VERSION ""

NS_ :

BS_:

BU_: ATCM_DMSM HCM_HS2 PAM_HS2 GSM TRCM GWM _delete SASM SCCM ATCM SUMA_RLM ATCM_FFSM PCU VDM_HS2 TBM OCS GENERIC TSTR RCM

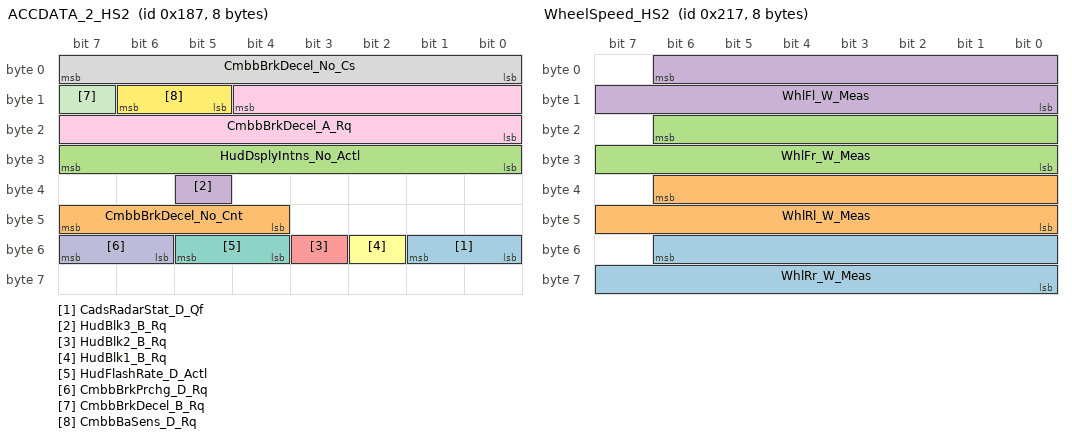
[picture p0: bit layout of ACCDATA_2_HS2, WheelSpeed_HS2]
BO_ 391 ACCDATA_2_HS2: 8 GWM
 SG_ CadsRadarStat_D_Qf : 49|2@0+ (1,0) [0|3] "SED"  GWM,GENERIC
 SG_ CmbbBrkDecel_No_Cnt : 47|4@0+ (1,0) [0|15] "Unitless"  GWM
 SG_ HudDsplyIntns_No_Actl : 31|8@0+ (0.5,0) [0|100] "%"  GWM
 SG_ HudBlk3_B_Rq : 37|1@0+ (1,0) [0|1] "SED"  GWM
 SG_ HudBlk2_B_Rq : 51|1@0+ (1,0) [0|1] "SED"  GWM
 SG_ HudBlk1_B_Rq : 50|1@0+ (1,0) [0|1] "SED"  GWM
 SG_ HudFlashRate_D_Actl : 53|2@0+ (1,0) [0|3] "SED"  GWM
 SG_ CmbbBrkDecel_No_Cs : 7|8@0+ (1,0) [0|255] "Unitless"  GWM
 SG_ CmbbBrkDecel_A_Rq : 12|13@0+ (0.0039,-20) [-20|11.9449] "m/s^2"  GWM,RCM
 SG_ CmbbBrkPrchg_D_Rq : 55|2@0+ (1,0) [0|3] "SED"  GWM,RCM
 SG_ CmbbBrkDecel_B_Rq : 15|1@0+ (1,0) [0|1] "SED"  GWM,RCM
 SG_ CmbbBaSens_D_Rq : 14|2@0+ (1,0) [0|3] "SED"  GWM,RCM

BO_ 535 WheelSpeed_HS2: 8 GWM
 SG_ WhlRr_W_Meas : 54|15@0+ (0.01,0) [0|327.65] "rad/s"  VDM_HS2,PAM_HS2,RCM
 SG_ WhlRl_W_Meas : 38|15@0+ (0.01,0) [0|327.65] "rad/s"  VDM_HS2,PAM_HS2,RCM
 SG_ WhlFr_W_Meas : 22|15@0+ (0.01,0) [0|327.65] "rad/s"  VDM_HS2,PAM_HS2,RCM
 SG_ WhlFl_W_Meas : 6|15@0+ (0.01,0) [0|327.65] "rad/s"  VDM_HS2,PAM_HS2,RCM

BO_ 531 DesiredTorqBrk_HS2: 8 GWM
 SG_ VehStop_D_Stat : 28|2@0+ (1,0) [0|3] "SED" Vector__XXX
 SG_ TracCtlPtActv_B_Actl : 31|1@0+ (1,0) [0|1] "SED"  PAM_HS2,VDM_HS2,RCM
 SG_ LscmbbMntr_B_Err : 17|1@0+ (1,0) [0|1] "SED" Vector__XXX
 SG_ LscmbbBrkDis_B_Actl : 19|1@0+ (1,0) [0|1] "SED" Vector__XXX
 SG_ LscmbbDeny_B_ActlBrk : 18|1@0+ (1,0) [0|1] "SED" Vector__XXX
 SG_ PrkBrkYwLamp_D_Rq : 38|2@0+ (1,0) [0|3] "SED" Vector__XXX
 SG_ PrkBrkRedLamp_D_Rq : 30|2@0+ (1,0) [0|3] "SED" Vector__XXX
 SG_ VehicleStationary : 39|1@0+ (1,0) [0|1] "SED" Vector__XXX
 SG_ LscmbbBrkDecel_B_Actl : 20|1@0+ (1,0) [0|1] "SED" Vector__XXX
 SG_ AbsActv_B_Actl : 45|1@0+ (1,0) [0|1] "SED"  PAM_HS2,SASM,TBM,RCM,TRCM,VDM_HS2
 SG_ StabCtlBrkActv_B_Actl : 23|1@0+ (1,0) [0|1] "SED"  PAM_HS2,SASM,VDM_HS2,RCM
 SG_ CmbbBrkPrchg_B_Actl : 59|1@0+ (1,0) [0|1] "SED"  TBM
 SG_ CmbbBrkDecel_B_Actl : 58|1@0+ (1,0) [0|1] "SED"  TBM
 SG_ CmbbBaSensInc_B_Actl : 57|1@0+ (1,0) [0|1] "SED" Vector__XXX
 SG_ AccBrkWarm_B_Actl : 63|1@0+ (1,0) [0|1] "SED" Vector__XXX
 SG_ AccBrkTotTqMn_B_Actl : 62|1@0+ (1,0) [0|1] "SED"  TBM
 SG_ AccBrkPrchgActv_B_Actl : 61|1@0+ (1,0) [0|1] "SED" Vector__XXX
 SG_ AccBrkDis_B_Actl : 44|1@0+ (1,0) [0|1] "SED" Vector__XXX
 SG_ AccBrkDeny_B_Actl : 42|1@0+ (1,0) [0|1] "SED" Vector__XXX
 SG_ AccBrkActv_B_Actl : 43|1@0+ (1,0) [0|1] "SED" Vector__XXX
 SG_ PrplDrgCtlActv_B_Actl : 46|1@0+ (1,0) [0|1] "SED" Vector__XXX
 SG_ PrplWhlTot_Tq_RqMx : 7|16@0+ (4,-131072) [-131072|131068] "Nm" Vector__XXX
 SG_ LscmbbBaSensInc_B_Actl : 21|1@0+ (1,0) [0|1] "SED" Vector__XXX
 SG_ CmbbBrkDis_B_Actl : 56|1@0+ (1,0) [0|1] "SED" Vector__XXX
 SG_ CmbbDeny_B_ActlBrk : 60|1@0+ (1,0) [0|1] "SED" Vector__XXX
 SG_ CcDis_B_Cmd : 47|1@0+ (1,0) [0|1] "SED" Vector__XXX
 SG_ VehLongOvrGnd_A_Est : 41|10@0+ (0.035,-17.9) [-17.9|17.835] "m/s^2"  VDM_HS2,TBM
 SG_ LscmbBrkPrchg_B_Actl : 16|1@0+ (1,0) [0|1] "SED" Vector__XXX
 SG_ AccStopActv_B_ActlBrk : 22|1@0+ (1,0) [0|1] "SED" Vector__XXX
 SG_ AccDis_B_ActlEpb : 32|1@0+ (1,0) [0|1] "SED" Vector__XXX
 SG_ PrkBrkMsgTxt_D_Rq : 36|4@0+ (1,0) [0|15] "SED" Vector__XXX
 SG_ PrkBrkStatus : 26|3@0+ (1,0) [0|7] "SED"  RCM,PAM_HS2,GSM

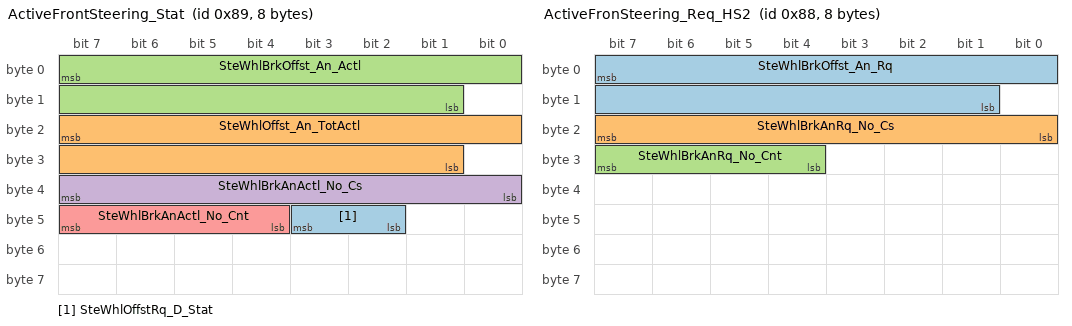
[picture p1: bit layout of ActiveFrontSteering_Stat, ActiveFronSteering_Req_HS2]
BO_ 137 ActiveFrontSteering_Stat: 8 SASM
 SG_ SteWhlOffstRq_D_Stat : 43|2@0+ (1,0) [0|3] "SED"  GWM
 SG_ SteWhlOffst_An_TotActl : 23|15@0+ (0.1,-1600) [-1600|1676.5] "degrees"  GWM
 SG_ SteWhlBrkOffst_An_Actl : 7|15@0+ (0.1,-1600) [-1600|1676.5] "degrees"  GWM
 SG_ SteWhlBrkAnActl_No_Cs : 39|8@0+ (1,0) [0|255] "Unitless"  GWM
 SG_ SteWhlBrkAnActl_No_Cnt : 47|4@0+ (1,0) [0|15] "Unitless"  GWM

BO_ 136 ActiveFronSteering_Req_HS2: 8 GWM
 SG_ SteWhlBrkOffst_An_Rq : 7|15@0+ (0.1,-1600) [-1600|1676.5] "degrees"  SASM
 SG_ SteWhlBrkAnRq_No_Cs : 23|8@0+ (1,0) [0|255] "Unitless"  SASM
 SG_ SteWhlBrkAnRq_No_Cnt : 31|4@0+ (1,0) [0|15] "Unitless"  SASM

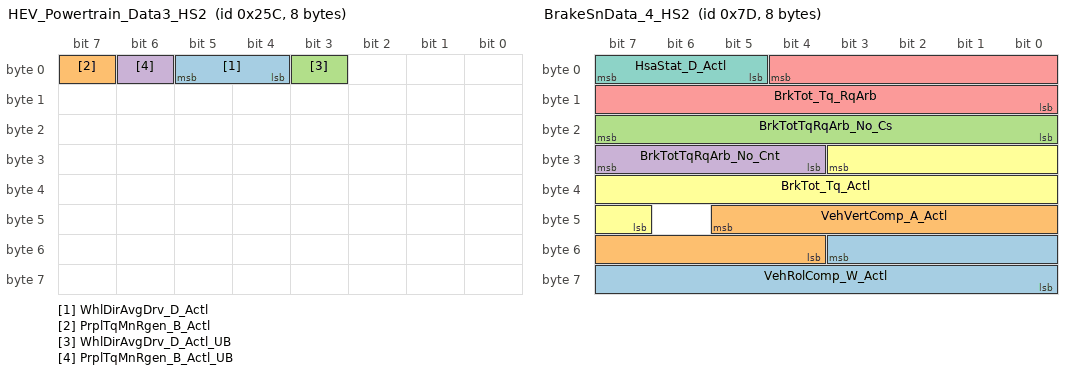
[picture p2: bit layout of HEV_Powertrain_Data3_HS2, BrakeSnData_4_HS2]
BO_ 604 HEV_Powertrain_Data3_HS2: 8 GWM
 SG_ WhlDirAvgDrv_D_Actl : 5|2@0+ (1,0) [0|3] "SED"  PAM_HS2
 SG_ PrplTqMnRgen_B_Actl : 7|1@0+ (1,0) [0|1] "SED" Vector__XXX
 SG_ WhlDirAvgDrv_D_Actl_UB : 3|1@0+ (1,0) [0|1] "SED" Vector__XXX
 SG_ PrplTqMnRgen_B_Actl_UB : 6|1@0+ (1,0) [0|1] "SED" Vector__XXX

BO_ 2015 TesterFunctionalReq_H2: 8 TSTR
 SG_ TesterFunctionalReq : 7|64@0+ (1,0) [0|1.84467E+019] "unitless"  HCM_HS2,PAM_HS2,SUMA_RLM,ATCM_FFSM,SASM,ATCM_DMSM,RCM,GSM,TRCM,PCU,OCS,ATCM,SCCM,TBM,VDM_HS2,GWM

BO_ 125 BrakeSnData_4_HS2: 8 GWM
 SG_ VehRolComp_W_Actl : 51|12@0+ (0.03663,-75) [-75|74.92659] "degrees/sec"  VDM_HS2
 SG_ VehVertComp_A_Actl : 45|10@0+ (0.035,-17.9) [-17.9|17.835] "m/s^2"  VDM_HS2
 SG_ BrkTotTqRqArb_No_Cs : 23|8@0+ (1,0) [0|255] "Unitless"  TBM
 SG_ BrkTotTqRqArb_No_Cnt : 31|4@0+ (1,0) [0|15] "Unitless"  TBM
 SG_ BrkTot_Tq_RqArb : 4|13@0+ (4,0) [0|32756] "Nm"  HCM_HS2,SUMA_RLM,TBM,VDM_HS2
 SG_ BrkTot_Tq_Actl : 27|13@0+ (4,0) [0|32756] "Nm"  RCM
 SG_ HsaStat_D_Actl : 7|3@0+ (1,0) [0|7] "SED"  GENERIC

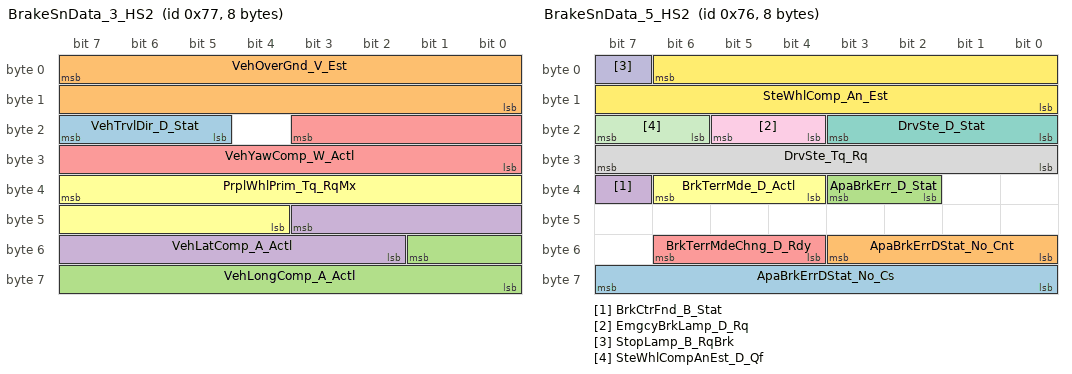
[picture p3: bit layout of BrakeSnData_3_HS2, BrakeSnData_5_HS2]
BO_ 119 BrakeSnData_3_HS2: 8 GWM
 SG_ VehTrvlDir_D_Stat : 23|3@0+ (1,0) [0|7] "SED"  SASM
 SG_ VehOverGnd_V_Est : 7|16@0+ (0.01,0) [0|655.33] "kph"  VDM_HS2,SASM
 SG_ VehLongComp_A_Actl : 49|10@0+ (0.035,-17.9) [-17.9|17.835] "m/s^2"  HCM_HS2,SUMA_RLM,VDM_HS2
 SG_ VehLatComp_A_Actl : 43|10@0+ (0.035,-17.9) [-17.9|17.835] "m/s^2"  HCM_HS2,SUMA_RLM,VDM_HS2
 SG_ VehYawComp_W_Actl : 19|12@0+ (0.03663,-75) [-75|74.92659] "deg/s"  PAM_HS2,VDM_HS2,SASM
 SG_ PrplWhlPrim_Tq_RqMx : 39|12@0+ (8,0) [0|32760] "Nm"  GENERIC

BO_ 118 BrakeSnData_5_HS2: 8 GWM
 SG_ ApaBrkErrDStat_No_Cs : 63|8@0+ (1,0) [0|255] "Unitless"  GENERIC
 SG_ ApaBrkErrDStat_No_Cnt : 51|4@0+ (1,0) [0|15] "Unitless"  GENERIC
 SG_ ApaBrkErr_D_Stat : 35|2@0+ (1,0) [0|3] "SED"  GENERIC
 SG_ BrkCtrFnd_B_Stat : 39|1@0+ (1,0) [0|1] "SED"  SASM
 SG_ BrkTerrMdeChng_D_Rdy : 54|3@0+ (1,0) [0|7] "SED"  ATCM,GENERIC
 SG_ BrkTerrMde_D_Actl : 38|3@0+ (1,0) [0|7] "SED"  ATCM,GENERIC
 SG_ DrvSte_D_Stat : 19|4@0+ (1,0) [0|15] "SED"  GENERIC
 SG_ DrvSte_Tq_Rq : 31|8@0+ (0.0625,-8) [-8|7.8125] "Nm"  GENERIC
 SG_ EmgcyBrkLamp_D_Rq : 21|2@0+ (1,0) [0|3] "SED"  GENERIC
 SG_ StopLamp_B_RqBrk : 7|1@0+ (1,0) [0|1] "SED"  GENERIC
 SG_ SteWhlCompAnEst_D_Qf : 23|2@0+ (1,0) [0|3] "SED"  PAM_HS2,SCCM,RCM
 SG_ SteWhlComp_An_Est : 6|15@0+ (0.1,-1600) [-1600|1676.7] "deg"  PAM_HS2,SCCM,RCM

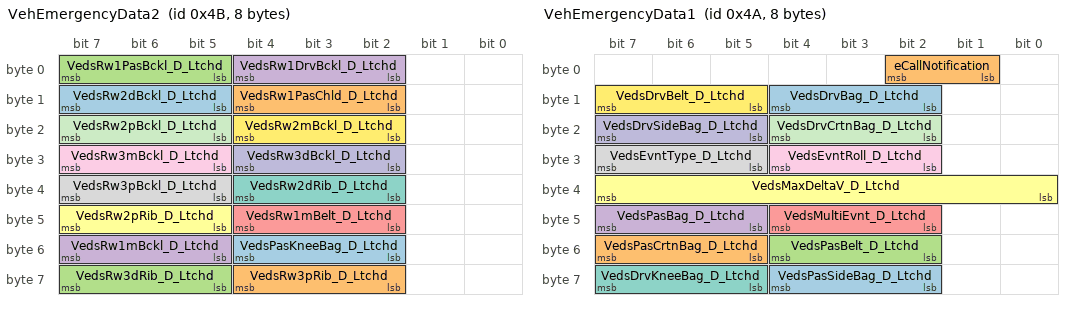
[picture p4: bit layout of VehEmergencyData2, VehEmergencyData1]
BO_ 75 VehEmergencyData2: 8 RCM
 SG_ VedsPasKneeBag_D_Ltchd : 52|3@0+ (1,0) [0|7] "SED"  GWM
 SG_ VedsRw3pRib_D_Ltchd : 60|3@0+ (1,0) [0|7] "SED"  GWM
 SG_ VedsRw3dRib_D_Ltchd : 63|3@0+ (1,0) [0|7] "SED"  GWM
 SG_ VedsRw1mBckl_D_Ltchd : 55|3@0+ (1,0) [0|7] "SED"  GWM
 SG_ VedsRw1mBelt_D_Ltchd : 44|3@0+ (1,0) [0|7] "SED"  GWM
 SG_ VedsRw2pRib_D_Ltchd : 47|3@0+ (1,0) [0|7] "SED"  GWM
 SG_ VedsRw2dRib_D_Ltchd : 36|3@0+ (1,0) [0|7] "SED"  GWM
 SG_ VedsRw3pBckl_D_Ltchd : 39|3@0+ (1,0) [0|7] "SED"  GWM
 SG_ VedsRw3mBckl_D_Ltchd : 31|3@0+ (1,0) [0|7] "SED"  GWM
 SG_ VedsRw3dBckl_D_Ltchd : 28|3@0+ (1,0) [0|7] "SED"  GWM
 SG_ VedsRw2pBckl_D_Ltchd : 23|3@0+ (1,0) [0|7] "SED"  GWM
 SG_ VedsRw2mBckl_D_Ltchd : 20|3@0+ (1,0) [0|7] "SED"  GWM
 SG_ VedsRw2dBckl_D_Ltchd : 15|3@0+ (1,0) [0|7] "SED"  GWM
 SG_ VedsRw1PasChld_D_Ltchd : 12|3@0+ (1,0) [0|7] "SED"  GWM
 SG_ VedsRw1PasBckl_D_Ltchd : 7|3@0+ (1,0) [0|7] "SED"  GWM
 SG_ VedsRw1DrvBckl_D_Ltchd : 4|3@0+ (1,0) [0|7] "SED"  GWM

BO_ 74 VehEmergencyData1: 8 RCM
 SG_ VedsPasSideBag_D_Ltchd : 60|3@0+ (1,0) [0|7] "SED"  GWM
 SG_ VedsPasCrtnBag_D_Ltchd : 55|3@0+ (1,0) [0|7] "SED"  GWM
 SG_ VedsPasBelt_D_Ltchd : 52|3@0+ (1,0) [0|7] "SED"  GWM
 SG_ VedsPasBag_D_Ltchd : 47|3@0+ (1,0) [0|7] "SED"  GWM
 SG_ VedsMultiEvnt_D_Ltchd : 44|3@0+ (1,0) [0|7] "SED"  GWM
 SG_ VedsMaxDeltaV_D_Ltchd : 39|8@0+ (1,0) [0|255] "kph"  GWM
 SG_ VedsDrvKneeBag_D_Ltchd : 63|3@0+ (1,0) [0|7] "SED"  GWM
 SG_ VedsEvntType_D_Ltchd : 31|3@0+ (1,0) [0|7] "SED"  GWM
 SG_ VedsEvntRoll_D_Ltchd : 28|3@0+ (1,0) [0|7] "SED"  GWM
 SG_ VedsDrvSideBag_D_Ltchd : 23|3@0+ (1,0) [0|7] "SED"  GWM
 SG_ VedsDrvCrtnBag_D_Ltchd : 20|3@0+ (1,0) [0|7] "SED"  GWM
 SG_ VedsDrvBelt_D_Ltchd : 15|3@0+ (1,0) [0|7] "SED"  GWM
 SG_ VedsDrvBag_D_Ltchd : 12|3@0+ (1,0) [0|7] "SED"  GWM
 SG_ eCallNotification : 2|2@0+ (1,0) [0|3] "SED"  GWM

BO_ 947 BodyInfo_3_HS2: 8 GWM
 SG_ ValetMode_D_Mem : 16|1@0+ (1,0) [0|1] "SED"  GENERIC
 SG_ DimmingLvlEvnt_No_Actl : 18|2@0+ (1,0) [0|3] "unitless"  GENERIC
 SG_ DrStatDrvErrCnt_B_Stat : 19|1@0+ (1,0) [0|1] "SED"  GENERIC
 SG_ Backlit_LED_Status : 23|4@0+ (1,0) [0|15] "SED"  ATCM_DMSM,ATCM_FFSM,ATCM,TBM,GSM
 SG_ TurnLghtRight_D_Rq : 63|2@0+ (1,0) [0|3] "SED"  HCM_HS2,SCCM
 SG_ TurnLghtRightOn_B_Stat : 35|1@0+ (1,0) [0|1] "SED"  GENERIC
 SG_ TurnLghtLeftOn_B_Stat : 54|1@0+ (1,0) [0|1] "SED"  GENERIC
 SG_ FogLghtRearOn_B_Stat : 1|1@0+ (1,0) [0|1] "SED"  HCM_HS2,GENERIC
 SG_ FogLghtFrontOn_B_Stat : 56|1@0+ (1,0) [0|1] "SED"  HCM_HS2
 SG_ TurnLghtLeft_D_Rq : 9|2@0+ (1,0) [0|3] "SED"  HCM_HS2,SCCM
 SG_ IgnKeyType_D_Actl : 39|4@0+ (1,0) [0|15] "SED"  PAM_HS2
 SG_ Parklamp_Status : 3|2@0+ (1,0) [0|3] "SED"  HCM_HS2,PAM_HS2,GSM,ATCM_FFSM,ATCM_DMSM
 SG_ Litval : 47|8@0+ (1,0) [0|253] "SED"  SCCM,HCM_HS2,ATCM,ATCM_DMSM,ATCM_FFSM,SASM,TBM,GSM
 SG_ Key_In_Ignition_Stat : 11|1@0+ (1,0) [0|1] "SED"  GSM,TRCM
 SG_ Ignition_Status : 7|4@0+ (1,0) [0|15] "SED"  HCM_HS2,PAM_HS2,SASM,SUMA_RLM,ATCM_DMSM,ATCM,OCS,TBM,VDM_HS2,TRCM,SCCM,GSM,RCM,ATCM_FFSM
 SG_ Dimming_Lvl : 31|8@0+ (1,0) [0|253] "SED"  SCCM,PAM_HS2,SASM,RCM,ATCM,ATCM_DMSM,ATCM_FFSM,GSM,TBM
 SG_ Day_Night_Status : 15|2@0+ (1,0) [0|3] "SED"  PAM_HS2,GSM,ATCM_DMSM,TBM,ATCM_FFSM,RCM
 SG_ Remote_Start_Status : 13|2@0+ (1,0) [0|3] "SED"  TRCM,RCM,GENERIC
 SG_ DrStatTgate_B_Actl : 0|1@0+ (1,0) [0|1] "SED"  PAM_HS2,SUMA_RLM,VDM_HS2,OCS
 SG_ DrStatRr_B_Actl : 49|1@0+ (1,0) [0|1] "SED"  PAM_HS2,SUMA_RLM,VDM_HS2,OCS
 SG_ DrStatRl_B_Actl : 48|1@0+ (1,0) [0|1] "SED"  PAM_HS2,SUMA_RLM,VDM_HS2,OCS
 SG_ DrStatPsngr_B_Actl : 60|1@0+ (1,0) [0|1] "SED"  PAM_HS2,SUMA_RLM,ATCM_FFSM,ATCM_DMSM,VDM_HS2,OCS
 SG_ DrStatInnrTgate_B_Actl : 58|1@0+ (1,0) [0|1] "SED"  PAM_HS2,SUMA_RLM,VDM_HS2,SCCM,OCS
 SG_ DrStatHood_B_Actl : 59|1@0+ (1,0) [0|1] "SED"  OCS
 SG_ DrStatDrv_B_Actl : 61|1@0+ (1,0) [0|1] "SED"  PAM_HS2,SUMA_RLM,ATCM_FFSM,ATCM_DMSM,SASM,VDM_HS2,GSM,OCS
 SG_ PrkBrkActv_B_Actl : 55|1@0+ (1,0) [0|1] "SED"  PAM_HS2
 SG_ LifeCycMde_D_Actl : 53|4@0+ (1,0) [0|15] "SED"  HCM_HS2,PAM_HS2,SUMA_RLM,SASM,SCCM,GSM,TRCM,VDM_HS2
 SG_ CrashEvnt_D_Stat : 34|2@0+ (1,0) [0|3] "SED"  GENERIC
 SG_ FuelPmpInhbt_B_Stat : 32|1@0+ (1,0) [0|1] "SED"  GENERIC
 SG_ BodySrvcRqd_B_Rq : 10|1@0+ (1,0) [0|1] "SED"  GENERIC
 SG_ Delay_Accy : 57|1@0+ (1,0) [0|1] "SED"  SASM,GENERIC

BO_ 131 Steering_Data: 8 SCCM
 SG_ HeadLghtHiCtrl_D_RqAhb : 43|3@0+ (1,0) [0|7] "SED"  HCM_HS2,GWM
 SG_ AhbStat_B_Dsply : 33|1@0+ (1,0) [0|1] "SED"  GWM
 SG_ WiprFrontSwtch_D_Stat : 47|4@0+ (1,0) [0|15] "SED"  GWM
 SG_ HeadLghtHiOn_B_StatAhb : 34|1@0+ (1,0) [0|1] "SED"  GENERIC,GWM
 SG_ HeadLghtHiFlash_D_Actl : 36|2@0+ (1,0) [0|3] "SED"  HCM_HS2,GWM
 SG_ TjaButtnOnOffPress : 40|1@0+ (1,0) [0|1] "SED"  GWM
 SG_ AccButtnGapTogglePress : 32|1@0+ (1,0) [0|1] "SED"  GWM
 SG_ HeadLghtHiFlash_D_Stat : 7|2@0+ (1,0) [0|3] "SED"  GENERIC,GWM
 SG_ WiprFront_D_Stat : 3|4@0+ (1,0) [0|15] "SED"  HCM_HS2,GWM
 SG_ TurnLghtSwtch_D_Stat : 5|2@0+ (1,0) [0|3] "SED"  RCM,HCM_HS2,PAM_HS2,SASM,GWM
 SG_ LghtAmb_D_Sns : 15|3@0+ (1,0) [0|7] "SED"  HCM_HS2,GWM
 SG_ AccButtnGapIncPress : 11|1@0+ (1,0) [0|1] "SED"  GWM
 SG_ AccButtnGapDecPress : 12|1@0+ (1,0) [0|1] "SED"  GWM
 SG_ AslButtnOnOffPress : 9|1@0+ (1,0) [0|1] "SED"  GWM
 SG_ AslButtnOnOffCnclPress : 10|1@0+ (1,0) [0|1] "SED"  GWM
 SG_ CcButtnOnPress : 37|1@0+ (1,0) [0|1] "SED"  GWM
 SG_ CcButtnOnOffPress : 38|1@0+ (1,0) [0|1] "SED"  GWM
 SG_ CcButtnOnOffCnclPress : 39|1@0+ (1,0) [0|1] "SED"  GWM
 SG_ CcButtnOffPress : 24|1@0+ (1,0) [0|1] "SED"  GWM
 SG_ CcAsllButtnResPress : 25|1@0+ (1,0) [0|1] "SED"  GWM
 SG_ CcAslButtnSetPress : 26|1@0+ (1,0) [0|1] "SED"  GWM
 SG_ CcAslButtnSetIncPress : 27|1@0+ (1,0) [0|1] "SED"  GWM
 SG_ CcAslButtnSetDecPress : 28|1@0+ (1,0) [0|1] "SED"  GWM
 SG_ CcAslButtnResIncPress : 29|1@0+ (1,0) [0|1] "SED"  GWM
 SG_ CcAslButtnResDecPress : 30|1@0+ (1,0) [0|1] "SED"  GWM
 SG_ CcAslButtnOnPress : 31|1@0+ (1,0) [0|1] "SED"  GWM
 SG_ CcAslButtnOnOffCncl : 16|1@0+ (1,0) [0|1] "SED"  GWM
 SG_ CcAslButtnOffCnclPress : 17|1@0+ (1,0) [0|1] "SED"  GWM
 SG_ CcAslButtnIndxIncPress : 18|1@0+ (1,0) [0|1] "SED"  GWM
 SG_ CcAslButtnIndxDecPress : 19|1@0+ (1,0) [0|1] "SED"  GWM
 SG_ CcAslButtnDeny_B_Actl : 20|1@0+ (1,0) [0|1] "SED"  GWM
 SG_ CcAslButtnCnclResPress : 21|1@0+ (1,0) [0|1] "SED"  GWM
 SG_ CcAslButtnCnclPress : 8|1@0+ (1,0) [0|1] "SED"  GWM
 SG_ LaSwtchPos_D_Stat : 23|2@0+ (1,0) [0|3] "SED"  GENERIC,GWM

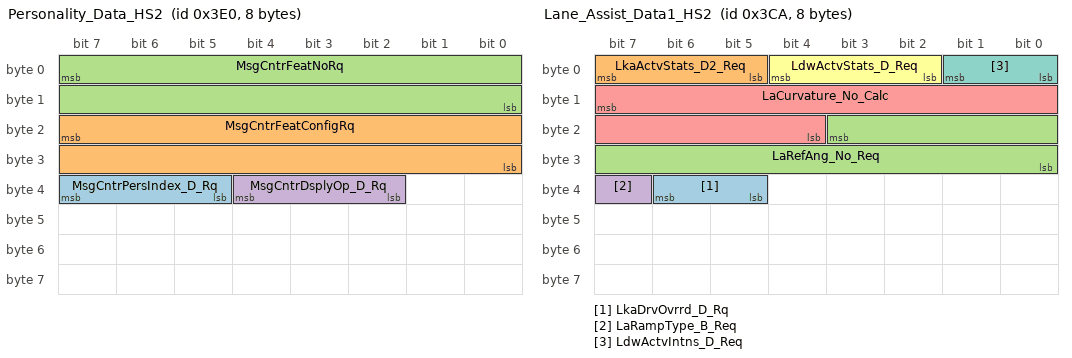
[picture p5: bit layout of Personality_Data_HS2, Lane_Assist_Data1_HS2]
BO_ 992 Personality_Data_HS2: 8 GWM
 SG_ MsgCntrPersIndex_D_Rq : 39|3@0+ (1,0) [0|7] "SED"  HCM_HS2,SUMA_RLM,SASM,VDM_HS2,SCCM
 SG_ MsgCntrFeatConfigRq : 23|16@0+ (1,0) [0|65535] "unitless"  HCM_HS2,SUMA_RLM,SASM,VDM_HS2,SCCM
 SG_ MsgCntrFeatNoRq : 7|16@0+ (1,0) [0|65535] "Number"  HCM_HS2,SUMA_RLM,SASM,VDM_HS2,SCCM
 SG_ MsgCntrDsplyOp_D_Rq : 36|3@0+ (1,0) [0|7] "SED"  HCM_HS2,SUMA_RLM,SASM,SCCM,VDM_HS2

BO_ 970 Lane_Assist_Data1_HS2: 8 GWM
 SG_ LkaDrvOvrrd_D_Rq : 38|2@0+ (1,0) [0|3] "SED"  GWM
 SG_ LkaActvStats_D2_Req : 7|3@0+ (1,0) [0|7] "SED"  GWM
 SG_ LaRefAng_No_Req : 19|12@0+ (0.05,-102.4) [-102.4|102.3] "mrad"  GWM
 SG_ LaRampType_B_Req : 39|1@0+ (1,0) [0|1] "SED"  GWM
 SG_ LaCurvature_No_Calc : 15|12@0+ (5E-006,-0.01024) [-0.01024|0.01023] "1/m"  GWM
 SG_ LdwActvStats_D_Req : 4|3@0+ (1,0) [0|7] "SED"  GWM,SASM,SCCM
 SG_ LdwActvIntns_D_Req : 1|2@0+ (1,0) [0|3] "SED"  GWM,SASM,SCCM

BO_ 129 Steering_Wheel_Data2: 8 SCCM
 SG_ SelDrvMdeSwtch4_D_Stat4 : 38|2@0+ (1,0) [0|3] "SED"  GWM
 SG_ EngExhMdeQuiet_B_RqDrv2 : 39|1@0+ (1,0) [0|1] "SED"  GWM
 SG_ PoliceAux4Swtch_B_Stat : 30|1@0+ (1,0) [0|1] "SED"  GWM
 SG_ PoliceAux3Swtch_B_Stat : 31|1@0+ (1,0) [0|1] "SED"  GWM
 SG_ PoliceAux2Swtch_B_Stat : 16|1@0+ (1,0) [0|1] "SED"  GWM
 SG_ PoliceAux1Swtch_B_Stat : 17|1@0+ (1,0) [0|1] "SED"  GWM
 SG_ SteWhlSwtchHome_B_Stat : 19|1@0+ (1,0) [0|1] "SED"  GWM
 SG_ SteWhlSwtchInfo_B_Stat : 18|1@0+ (1,0) [0|1] "SED"  GWM
 SG_ SelDrvMdeSwtch_D_Stat4 : 21|2@0+ (1,0) [0|3] "SED"  GWM
 SG_ SelDrvMdeSwtch3_D_Stat4 : 25|2@0+ (1,0) [0|3] "SED"  GWM
 SG_ SelDrvMdeSwtch2_D_Stat4 : 27|2@0+ (1,0) [0|3] "SED"  GWM
 SG_ SelDrvMdeSwtch1_D_Stat4 : 29|2@0+ (1,0) [0|3] "SED"  GWM
 SG_ SteWhlSwtchView_B_Stat : 23|1@0+ (1,0) [0|1] "SED"  GWM
 SG_ SteWhlSwtchSet_B_Stat : 8|1@0+ (1,0) [0|1] "SED"  GWM
 SG_ SteWhlSwtchPhon_B_Stat : 9|1@0+ (1,0) [0|1] "SED"  GWM
 SG_ SteWhlSwtchNav_B_Stat : 10|1@0+ (1,0) [0|1] "SED"  GWM
 SG_ SteWhlSwtchMed_B_Stat : 11|1@0+ (1,0) [0|1] "SED"  GWM
 SG_ SteWhlSwtchIod_B_Stat : 12|1@0+ (1,0) [0|1] "SED"  GWM
 SG_ SteWhlSwtchHud_B_Stat : 13|1@0+ (1,0) [0|1] "SED"  GWM
 SG_ SteWhlSwtchBack_B_Stat : 14|1@0+ (1,0) [0|1] "SED"  GWM
 SG_ SteWhlSwtchMenu_B_Stat : 22|1@0+ (1,0) [0|1] "SED"  GWM
 SG_ SteEffortInc_B_RqDrv : 5|1@0+ (1,0) [0|1] "SED"  GWM
 SG_ SelDrvMdeInc_B_RqDrv : 6|1@0+ (1,0) [0|1] "SED"  GWM
 SG_ SelDrvMdeDec_B_RqDrv : 7|1@0+ (1,0) [0|1] "SED"  GWM
 SG_ SuspDampInc_B_RqDrv : 15|1@0+ (1,0) [0|1] "SED"  GWM
 SG_ SteWhlSwtchUp_B_Stat : 3|1@0+ (1,0) [0|1] "SED"  GWM
 SG_ SteWhlSwtchRght_B_Stat : 2|1@0+ (1,0) [0|1] "SED"  GWM
 SG_ SteWhlSwtchOk_B_Stat : 4|1@0+ (1,0) [0|1] "SED"  GWM
 SG_ SteWhlSwtchLeft_B_Stat : 1|1@0+ (1,0) [0|1] "SED"  GWM
 SG_ SteWhlSwtchDown_B_Stat : 0|1@0+ (1,0) [0|1] "SED"  GWM

BO_ 1833 TesterPhysicalResVDM_HS2: 8 VDM_HS2
 SG_ TesterPhysicalResVDM : 7|64@0+ (1,0) [0|1.84467E+019] "unitless"  TSTR

BO_ 1109 eCall_Info_HS2: 8 GWM
 SG_ eCallConfirmation : 7|3@0+ (1,0) [0|7] "SED"  RCM

BO_ 1046 BrakeSysFeatures_2_HS2: 8 GWM
 SG_ BpedDiffLckTq_No_Cs : 23|8@0+ (1,0) [0|255] "Unitless"  GENERIC
 SG_ PrkBrkDynmc_D_Allw : 39|2@0+ (1,0) [0|3] "SED" Vector__XXX
 SG_ BrkPrkBrkDynmc_B_Actl : 24|1@0+ (1,0) [0|1] "SED" Vector__XXX
 SG_ ReserveTracCtlPtActv : 28|1@0+ (1,0) [0|1] "SED"  GENERIC
 SG_ HsaMde_D_Mem : 33|2@0+ (1,0) [0|3] "SED" Vector__XXX
 SG_ BrkBstrVac_B_Rq : 27|1@0+ (1,0) [0|1] "Discrete" Vector__XXX
 SG_ HdcMde_D_Actl : 31|3@0+ (1,0) [0|7] "SED" Vector__XXX
 SG_ RearDiffLck_Tq2_RqMx : 51|12@0+ (4,0) [0|16376] "Nm" Vector__XXX
 SG_ TRLR_SWAY_EVNT_IN_PROG : 25|1@0+ (1,0) [0|1] "SED"  RCM
 SG_ TRLR_SWAY_CONFIG_STAT : 26|1@0+ (1,0) [0|1] "SED" Vector__XXX
 SG_ TCMode : 15|1@0+ (1,0) [0|1] "SED"  PAM_HS2,VDM_HS2,RCM
 SG_ DrvSlipCtlLamp_D_Rq : 42|2@0+ (1,0) [0|3] "SED"  PAM_HS2,VDM_HS2,SASM,RCM
 SG_ Abs_B_Falt : 5|1@0+ (1,0) [0|1] "SED"  TBM
 SG_ DrvSlipCtlMde_D_Ind : 44|2@0+ (1,0) [0|3] "SED"  PAM_HS2,SASM,RCM
 SG_ DrvAntiLckLamp_D_Rq : 55|2@0+ (1,0) [0|3] "SED"  PAM_HS2,RCM
 SG_ BpedMove_No_Cnt : 3|4@0+ (1,0) [0|15] "Unitless" Vector__XXX
 SG_ StabCtlBrk_B_Avail : 4|1@0+ (1,0) [0|1] "SED"  RCM,SUMA_RLM,VDM_HS2
 SG_ DrvHdcWarnInfo_D_Rq : 35|2@0+ (1,0) [0|3] "SED" Vector__XXX
 SG_ DrvHdcMsg_D_Rq : 10|3@0+ (1,0) [0|7] "SED" Vector__XXX
 SG_ DrvHdcLampInfo_D_Rq : 12|2@0+ (1,0) [0|3] "SED"  ATCM
 SG_ RearDiffElckrOpen_B_Rq : 40|1@0+ (1,0) [0|1] "SED"  GENERIC
 SG_ BpedMove_D_Actl : 7|2@0+ (1,0) [0|3] "SED" Vector__XXX
 SG_ ChimeBrk_B_Rq : 14|1@0+ (1,0) [0|1] "SED" Vector__XXX
 SG_ BrkLamp_B_Rq : 13|1@0+ (1,0) [0|1] "SED"  RCM
 SG_ HILL_DESC_MC : 47|3@0+ (1,0) [0|7] "SED" Vector__XXX

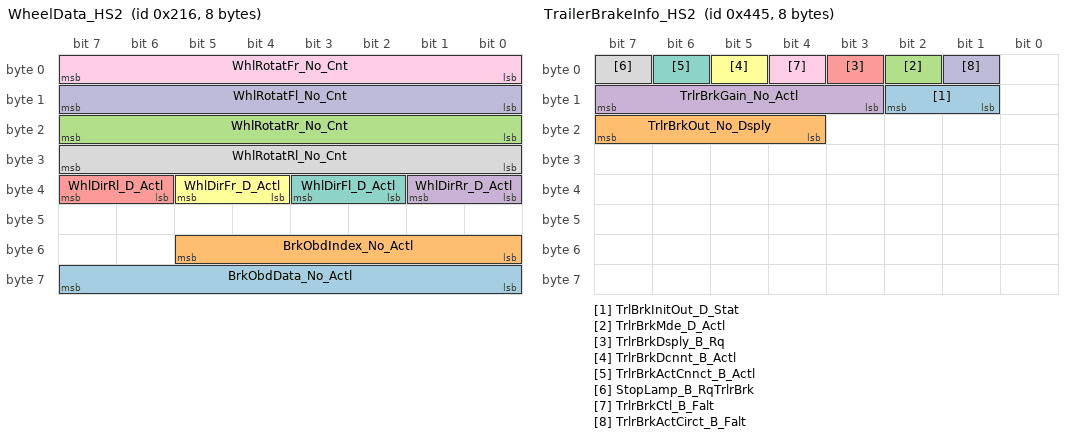
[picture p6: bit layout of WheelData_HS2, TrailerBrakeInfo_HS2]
BO_ 534 WheelData_HS2: 8 GWM
 SG_ BrkObdData_No_Actl : 63|8@0+ (1,0) [0|255] "unitless" Vector__XXX
 SG_ BrkObdIndex_No_Actl : 53|6@0+ (1,0) [0|63] "unitless" Vector__XXX
 SG_ WhlRotatRr_No_Cnt : 23|8@0+ (1,0) [0|255] "Unitless"  PAM_HS2,RCM
 SG_ WhlDirRr_D_Actl : 33|2@0+ (1,0) [0|3] "SED"  PAM_HS2,RCM
 SG_ WhlDirRl_D_Actl : 39|2@0+ (1,0) [0|3] "SED"  PAM_HS2,RCM
 SG_ WhlDirFr_D_Actl : 37|2@0+ (1,0) [0|3] "SED"  PAM_HS2,RCM
 SG_ WhlDirFl_D_Actl : 35|2@0+ (1,0) [0|3] "SED"  PAM_HS2,RCM
 SG_ WhlRotatRl_No_Cnt : 31|8@0+ (1,0) [0|255] "Unitless"  PAM_HS2,RCM
 SG_ WhlRotatFr_No_Cnt : 7|8@0+ (1,0) [0|255] "Unitless"  PAM_HS2,RCM
 SG_ WhlRotatFl_No_Cnt : 15|8@0+ (1,0) [0|255] "Unitless"  PAM_HS2,RCM

BO_ 1093 TrailerBrakeInfo_HS2: 8 GWM
 SG_ TrlBrkInitOut_D_Stat : 10|2@0+ (1,0) [0|3] "SED" Vector__XXX
 SG_ TrlrBrkOut_No_Dsply : 23|4@0+ (1,0) [0|15] "unitless" Vector__XXX
 SG_ TrlrBrkMde_D_Actl : 2|1@0+ (1,0) [0|1] "SED" Vector__XXX
 SG_ TrlrBrkGain_No_Actl : 15|5@0+ (0.5,0) [0|15.5] "unitless" Vector__XXX
 SG_ TrlrBrkDsply_B_Rq : 3|1@0+ (1,0) [0|1] "SED" Vector__XXX
 SG_ TrlrBrkDcnnt_B_Actl : 5|1@0+ (1,0) [0|1] "SED"  VDM_HS2
 SG_ TrlrBrkActCnnct_B_Actl : 6|1@0+ (1,0) [0|1] "SED"  SCCM,VDM_HS2
 SG_ StopLamp_B_RqTrlrBrk : 7|1@0+ (1,0) [0|1] "SED" Vector__XXX
 SG_ TrlrBrkCtl_B_Falt : 4|1@0+ (1,0) [0|1] "SED"  PAM_HS2
 SG_ TrlrBrkActCirct_B_Falt : 1|1@0+ (1,0) [0|1] "SED"  PAM_HS2

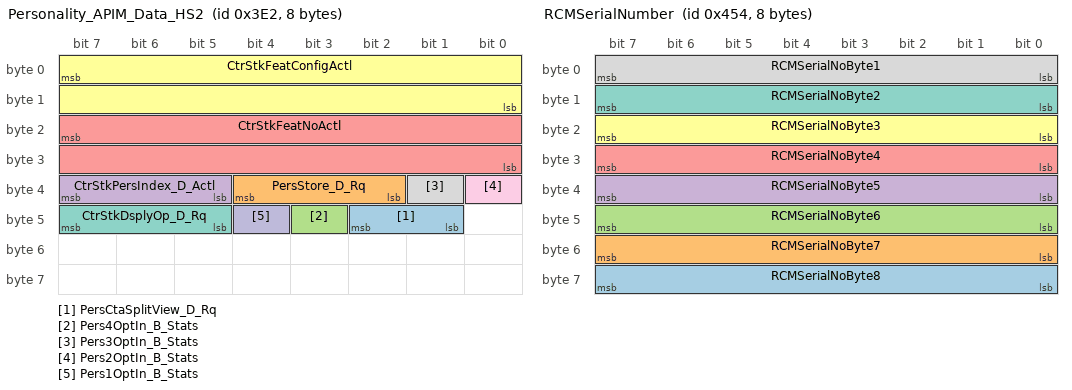
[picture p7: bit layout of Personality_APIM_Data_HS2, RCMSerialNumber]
BO_ 994 Personality_APIM_Data_HS2: 8 GWM
 SG_ PersCtaSplitView_D_Rq : 42|2@0+ (1,0) [0|3] "SED"  GENERIC
 SG_ PersStore_D_Rq : 36|3@0+ (1,0) [0|7] "SED"  GENERIC
 SG_ Pers4OptIn_B_Stats : 43|1@0+ (1,0) [0|1] "SED"  GENERIC
 SG_ CtrStkPersIndex_D_Actl : 39|3@0+ (1,0) [0|7] "SED"  HCM_HS2,SASM,SCCM,VDM_HS2
 SG_ CtrStkFeatNoActl : 23|16@0+ (1,0) [0|65535] "Undefined"  HCM_HS2,SASM,SCCM,VDM_HS2
 SG_ CtrStkFeatConfigActl : 7|16@0+ (1,0) [0|65535] "Undefined"  HCM_HS2,SASM,SCCM,VDM_HS2
 SG_ CtrStkDsplyOp_D_Rq : 47|3@0+ (1,0) [0|7] "SED"  HCM_HS2,SASM,SCCM,VDM_HS2
 SG_ Pers3OptIn_B_Stats : 33|1@0+ (1,0) [0|1] "SED"  GENERIC
 SG_ Pers2OptIn_B_Stats : 32|1@0+ (1,0) [0|1] "SED"  GENERIC
 SG_ Pers1OptIn_B_Stats : 44|1@0+ (1,0) [0|1] "SED"  GENERIC

BO_ 1836 TesterPhysicalResSCCM: 8 SCCM
 SG_ TesterPhysicalResSCCM : 7|64@0+ (1,0) [0|1.84467E+019] "unitless"  TSTR

BO_ 1825 TesterPhysicalReqVDM_HS2: 8 TSTR
 SG_ TesterPhysicalReqVDM : 7|64@0+ (1,0) [0|1.84467E+019] "unitless"  VDM_HS2

BO_ 1108 RCMSerialNumber: 8 RCM
 SG_ RCMSerialNoByte8 : 63|8@0+ (1,0) [0|253] "Unitless"  GWM,OCS
 SG_ RCMSerialNoByte7 : 55|8@0+ (1,0) [0|253] "Unitless"  GWM,OCS
 SG_ RCMSerialNoByte6 : 47|8@0+ (1,0) [0|253] "Unitless"  GWM,OCS
 SG_ RCMSerialNoByte5 : 39|8@0+ (1,0) [0|253] "Unitless"  GWM,OCS
 SG_ RCMSerialNoByte4 : 31|8@0+ (1,0) [0|253] "Unitless"  GWM,OCS
 SG_ RCMSerialNoByte3 : 23|8@0+ (1,0) [0|253] "Unitless"  GWM,OCS
 SG_ RCMSerialNoByte2 : 15|8@0+ (1,0) [0|253] "Unitless"  GWM,OCS
 SG_ RCMSerialNoByte1 : 7|8@0+ (1,0) [0|253] "Unitless"  GWM,OCS

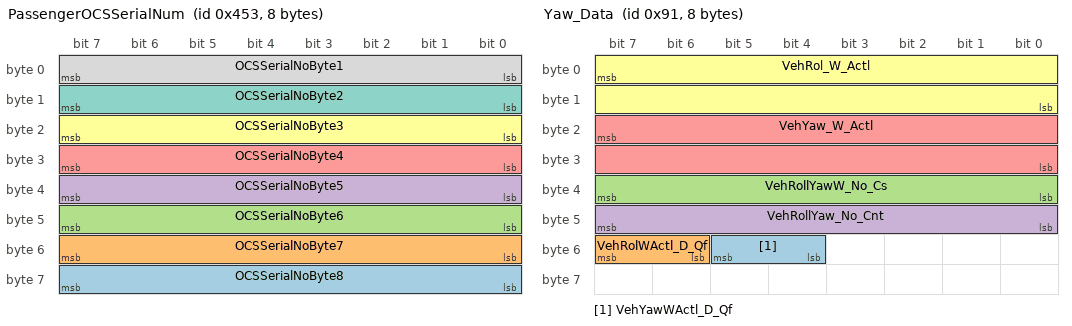
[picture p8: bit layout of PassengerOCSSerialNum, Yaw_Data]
BO_ 1107 PassengerOCSSerialNum: 8 OCS
 SG_ OCSSerialNoByte8 : 63|8@0+ (1,0) [0|253] "Unitless"  GWM,RCM
 SG_ OCSSerialNoByte7 : 55|8@0+ (1,0) [0|253] "Unitless"  GWM,RCM
 SG_ OCSSerialNoByte6 : 47|8@0+ (1,0) [0|253] "Unitless"  GWM,RCM
 SG_ OCSSerialNoByte5 : 39|8@0+ (1,0) [0|253] "Unitless"  GWM,RCM
 SG_ OCSSerialNoByte4 : 31|8@0+ (1,0) [0|253] "Unitless"  GWM,RCM
 SG_ OCSSerialNoByte3 : 23|8@0+ (1,0) [0|253] "Unitless"  GWM,RCM
 SG_ OCSSerialNoByte2 : 15|8@0+ (1,0) [0|253] "Unitless"  GWM,RCM
 SG_ OCSSerialNoByte1 : 7|8@0+ (1,0) [0|253] "Unitless"  GWM,RCM

BO_ 1879 TesterPhysicalReqTBM: 8 TSTR
 SG_ TesterPhysicalReqTBM : 7|64@0+ (1,0) [0|1.84467E+019] "unitless"  TBM

BO_ 145 Yaw_Data: 8 RCM
 SG_ VehYawWActl_D_Qf : 53|2@0+ (1,0) [0|3] "SED"  HCM_HS2,GWM,VDM_HS2
 SG_ VehRolWActl_D_Qf : 55|2@0+ (1,0) [0|3] "SED"  GWM,VDM_HS2
 SG_ VehRollYawW_No_Cs : 39|8@0+ (1,0) [0|255] "Unitless"  GWM
 SG_ VehRollYaw_No_Cnt : 47|8@0+ (1,0) [0|255] "Unitless"  GWM,VDM_HS2
 SG_ VehYaw_W_Actl : 23|16@0+ (0.0002,-6.5) [-6.5|6.6066] "rad/s"  HCM_HS2,VDM_HS2,GWM
 SG_ VehRol_W_Actl : 7|16@0+ (0.0002,-6.5) [-6.5|6.6066] "rad/s"  VDM_HS2,GWM

BO_ 1828 TesterPhysicalReqSCCM: 8 TSTR
 SG_ TesterPhysicalReqSCCM : 7|64@0+ (1,0) [0|1.84467E+019] "unitless"  SCCM

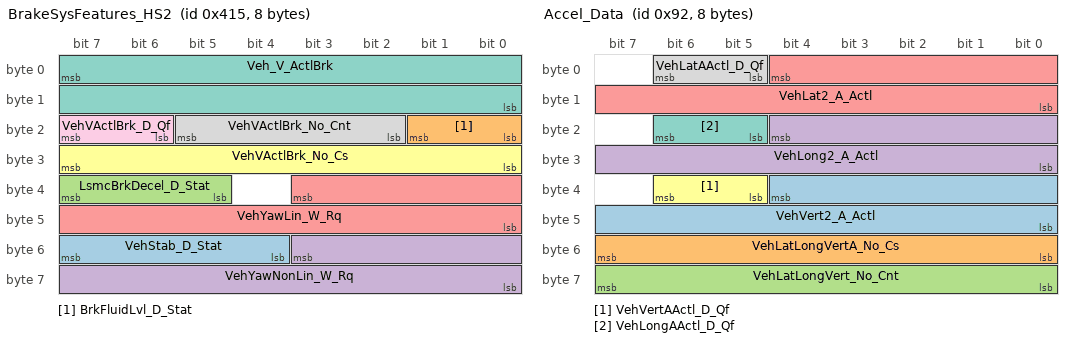
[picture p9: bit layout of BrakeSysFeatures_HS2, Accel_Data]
BO_ 1045 BrakeSysFeatures_HS2: 8 GWM
 SG_ VehStab_D_Stat : 55|4@0+ (1,0) [0|15] "SED"  HCM_HS2
 SG_ BrkFluidLvl_D_Stat : 17|2@0+ (1,0) [0|3] "SED" Vector__XXX
 SG_ LsmcBrkDecel_D_Stat : 39|3@0+ (1,0) [0|7] "SED" Vector__XXX
 SG_ VehYawNonLin_W_Rq : 51|12@0+ (0.03663,-75) [-75|74.92659] "deg/s" Vector__XXX
 SG_ VehYawLin_W_Rq : 35|12@0+ (0.03663,-75) [-75|74.92659] "deg/s" Vector__XXX
 SG_ VehVActlBrk_No_Cs : 31|8@0+ (1,0) [0|255] "Unitless"  PAM_HS2,SASM
 SG_ Veh_V_ActlBrk : 7|16@0+ (0.01,0) [0|655.35] "kph"  PAM_HS2,SCCM,SASM,GSM,TRCM
 SG_ VehVActlBrk_No_Cnt : 21|4@0+ (1,0) [0|15] "Unitless"  PAM_HS2,SASM
 SG_ VehVActlBrk_D_Qf : 23|2@0+ (1,0) [0|3] "SED"  PAM_HS2,SCCM,SASM,GSM,TRCM

BO_ 146 Accel_Data: 8 RCM
 SG_ VehVert2_A_Actl : 36|13@0+ (0.01,-40) [-40|41.89] "m/s^2"  OCS,VDM_HS2,GWM
 SG_ VehLatLongVertA_No_Cs : 55|8@0+ (1,0) [0|255] "Unitless"  GWM
 SG_ VehLatLongVert_No_Cnt : 63|8@0+ (1,0) [0|255] "Unitless"  GWM,VDM_HS2
 SG_ VehLong2_A_Actl : 20|13@0+ (0.01,-40) [-40|41.89] "m/s^2"  PAM_HS2,GWM,VDM_HS2,OCS
 SG_ VehLat2_A_Actl : 4|13@0+ (0.01,-40) [-40|41.89] "m/s^2"  OCS,VDM_HS2,GWM
 SG_ VehVertAActl_D_Qf : 38|2@0+ (1,0) [0|3] "SED"  OCS,GWM,VDM_HS2
 SG_ VehLongAActl_D_Qf : 22|2@0+ (1,0) [0|3] "SED"  PAM_HS2,OCS,VDM_HS2,GWM
 SG_ VehLatAActl_D_Qf : 6|2@0+ (1,0) [0|3] "SED"  OCS,VDM_HS2,GWM

BO_ 1152 All_Terrain_Data: 8 ATCM
 SG_ TerrStat_D_RqDsply : 7|4@0+ (1,0) [0|15] "SED"  GWM
 SG_ TerrMde_D_RqDrv : 3|3@0+ (1,0) [0|7] "SED"  GWM

BO_ 1938 TesterPhysicalReqATCM: 8 TSTR
 SG_ TesterPhysicalReqATCM : 7|64@0+ (1,0) [0|1.84467E+019] "unitless"  ATCM_FFSM,ATCM_DMSM,ATCM

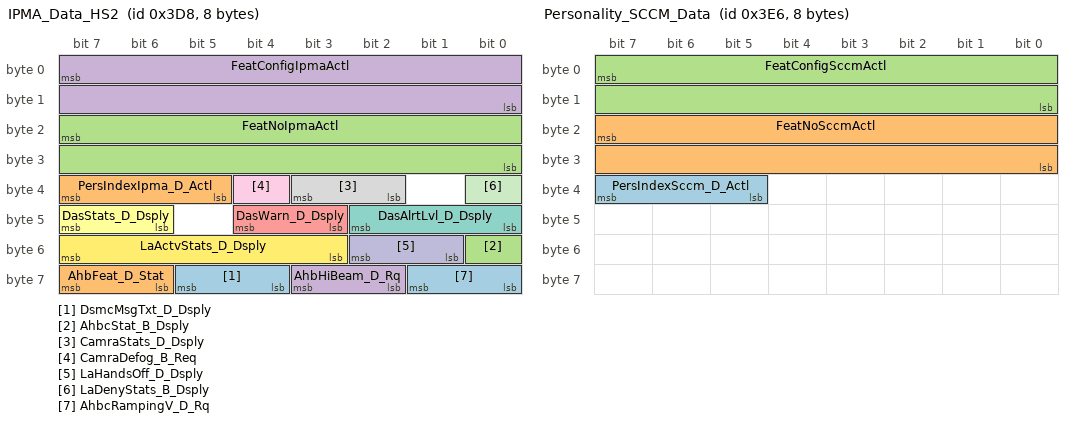
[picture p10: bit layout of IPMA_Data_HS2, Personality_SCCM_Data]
BO_ 984 IPMA_Data_HS2: 8 GWM
 SG_ DsmcMsgTxt_D_Dsply : 61|2@0+ (1,0) [0|3] "SED"  GENERIC,GWM
 SG_ AhbFeat_D_Stat : 63|2@0+ (1,0) [0|3] "SED"  GWM,HCM_HS2,SCCM
 SG_ AhbcStat_B_Dsply : 48|1@0+ (1,0) [0|1] "SED"  GWM
 SG_ AhbHiBeam_D_Rq : 59|2@0+ (1,0) [0|3] "SED"  GWM,HCM_HS2,SCCM
 SG_ DasWarn_D_Dsply : 44|2@0+ (1,0) [0|3] "SED"  GWM
 SG_ DasStats_D_Dsply : 47|2@0+ (1,0) [0|3] "SED"  GWM
 SG_ DasAlrtLvl_D_Dsply : 42|3@0+ (1,0) [0|7] "SED"  GWM
 SG_ CamraStats_D_Dsply : 35|2@0+ (1,0) [0|3] "SED"  GWM
 SG_ CamraDefog_B_Req : 36|1@0+ (1,0) [0|1] "SED"  GWM
 SG_ LaHandsOff_D_Dsply : 50|2@0+ (1,0) [0|3] "SED"  GWM
 SG_ LaDenyStats_B_Dsply : 32|1@0+ (1,0) [0|1] "SED"  GWM
 SG_ LaActvStats_D_Dsply : 55|5@0+ (1,0) [0|31] "SED"  GWM
 SG_ AhbcRampingV_D_Rq : 57|2@0+ (1,0) [0|3] "SED"  GWM,HCM_HS2
 SG_ PersIndexIpma_D_Actl : 39|3@0+ (1,0) [0|7] "SED"  GWM
 SG_ FeatNoIpmaActl : 23|16@0+ (1,0) [0|65535] "Number"  GWM
 SG_ FeatConfigIpmaActl : 7|16@0+ (1,0) [0|65535] "Undefined"  GWM

BO_ 998 Personality_SCCM_Data: 8 SCCM
 SG_ PersIndexSccm_D_Actl : 39|3@0+ (1,0) [0|7] "SED"  GWM
 SG_ FeatNoSccmActl : 23|16@0+ (1,0) [0|65535] "Number"  GWM
 SG_ FeatConfigSccmActl : 7|16@0+ (1,0) [0|65535] "Undefined"  GWM

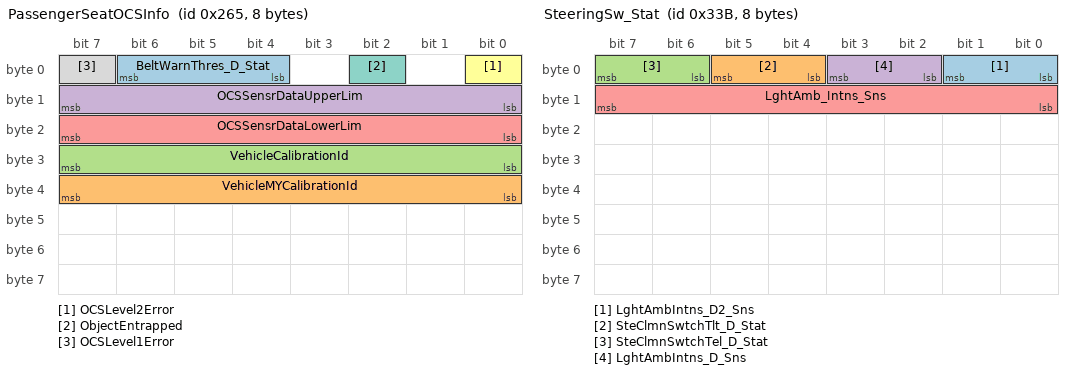
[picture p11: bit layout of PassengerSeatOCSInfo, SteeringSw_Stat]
BO_ 613 PassengerSeatOCSInfo: 8 OCS
 SG_ BeltWarnThres_D_Stat : 6|3@0+ (1,0) [0|7] "SED"  GWM,RCM
 SG_ VehicleMYCalibrationId : 39|8@0+ (1,0) [0|254] "SED"  GWM,RCM
 SG_ VehicleCalibrationId : 31|8@0+ (1,0) [0|254] "SED"  GWM,RCM
 SG_ OCSSensrDataUpperLim : 15|8@0+ (1,0) [0|254] "SED"  GWM,RCM
 SG_ OCSSensrDataLowerLim : 23|8@0+ (1,0) [0|254] "SED"  GWM,RCM
 SG_ OCSLevel2Error : 0|1@0+ (1,0) [0|1] "SED"  GWM,RCM
 SG_ ObjectEntrapped : 2|1@0+ (1,0) [0|1] "SED"  GWM
 SG_ OCSLevel1Error : 7|1@0+ (1,0) [0|1] "SED"  GWM,RCM

BO_ 1664 RCM_Rapid_Data_Response_1: 8 RCM
 SG_ UUDTRCMResponse1 : 7|64@0+ (1,0) [0|1.84467440737096E+019] "unitless"  TSTR

BO_ 1814 TesterPhysicalReqGWM_H2: 8 TSTR
 SG_ TesterPhysicalReqGWM_H2 : 7|64@0+ (1,0) [0|1.84467E+019] "unitless"  GWM

BO_ 2033 TesterPhysicalReqPCU: 8 TSTR
 SG_ TesterPhysicalReqPCU : 7|64@0+ (1,0) [0|1.84467E+019] "unitless"  RCM

BO_ 130 EPAS_INFO_HS2: 8 GWM
 SG_ TrlrHitchLamp_D_Rqst : 24|1@0+ (1,0) [0|1] "SED" Vector__XXX
 SG_ VehVTrlrAid_B_Rq : 25|1@0+ (1,0) [0|1] "SED"  GENERIC
 SG_ SteEffort_D_Stat : 52|3@0+ (1,0) [0|7] "SED"  GENERIC
 SG_ Veh_V_RqMxTrlrAid : 63|8@0+ (0.1,0) [0|25.5] "km/h"  GENERIC
 SG_ DrvSteActv_B_Stat : 10|1@0+ (1,0) [0|1] "SED"  GENERIC
 SG_ DrvSte_Tq_Actl : 47|8@0+ (0.0625,-8) [-8|7.8125] "Nm"  GENERIC
 SG_ SteMdule_D_Stat : 55|3@0+ (1,0) [0|7] "SED"  SASM,SCCM
 SG_ SteMdule_U_Meas : 39|8@0+ (0.05,6) [6|18.7] "Volts"  SASM
 SG_ SteMdule_I_Est : 21|12@0+ (0.05,-64) [-64|140.7] "Amps"  SASM
 SG_ EPAS_Failure : 9|2@0+ (1,0) [0|3] "SED"  RCM,PAM_HS2,SASM
 SG_ SteeringColumnTorque : 7|8@0+ (0.0625,-8) [-8|7.8125] "Nm"  PAM_HS2,SCCM,SASM
 SG_ SAPPAngleControlStat6 : 15|1@0+ (1,0) [0|1] "SED"  PAM_HS2
 SG_ SAPPAngleControlStat5 : 14|1@0+ (1,0) [0|1] "SED"  PAM_HS2
 SG_ SAPPAngleControlStat4 : 13|1@0+ (1,0) [0|1] "SED"  PAM_HS2
 SG_ SAPPAngleControlStat3 : 12|1@0+ (1,0) [0|1] "SED"  PAM_HS2
 SG_ SAPPAngleControlStat2 : 11|1@0+ (1,0) [0|1] "SED"  PAM_HS2
 SG_ SAPPAngleControlStat1 : 23|2@0+ (1,0) [0|3] "SED"  PAM_HS2

BO_ 1855 TesterPhysicalResRCM: 8 RCM
 SG_ TesterPhysicalResRCM : 7|64@0+ (1,0) [0|1.84467E+019] "unitless"  TSTR

BO_ 1847 TesterPhysicalReqRCM: 8 TSTR
 SG_ TesterPhysicalReqRCM : 7|64@0+ (1,0) [0|1.84467E+019] "unitless"  RCM

BO_ 827 SteeringSw_Stat: 8 SCCM
 SG_ LghtAmbIntns_D2_Sns : 1|2@0+ (1,0) [0|3] "SED"  GWM
 SG_ SteClmnSwtchTlt_D_Stat : 5|2@0+ (1,0) [0|3] "SED"  GWM
 SG_ SteClmnSwtchTel_D_Stat : 7|2@0+ (1,0) [0|3] "SED"  GWM
 SG_ LghtAmbIntns_D_Sns : 3|2@0+ (1,0) [0|3] "SED"  GWM
 SG_ LghtAmb_Intns_Sns : 15|8@0+ (1,0) [0|255] "unitless"  GWM

BO_ 848 RestraintsData_HS2: 8 GWM
 SG_ RILStat : 7|2@0+ (1,0) [0|3] "SED"  RCM

BO_ 1822 TesterPhysicalResGWM_HS2: 8 GWM
 SG_ TesterPhysicalResGWM_H2 : 7|64@0+ (1,0) [0|1.84467E+019] "unitless"  TSTR

BO_ 1901 TesterPhysicalResOCS: 8 OCS
 SG_ TesterPhysicalResOCS : 7|64@0+ (1,0) [0|1.84467E+019] "unitless"  TSTR

BO_ 1893 TesterPhysicalReqOCS: 8 TSTR
 SG_ TesterPhysicalReqOCS : 7|64@0+ (1,0) [0|1.84467E+019] "unitless"  OCS

BO_ 1946 TesterPhysicalResATCM: 8 ATCM
 SG_ TesterPhysicalResATCM : 7|64@0+ (1,0) [0|1.84467E+019] "unitless"  TSTR

BO_ 1887 TesterPhysicalResTBM: 8 TBM
 SG_ TesterPhysicalResTBM : 7|64@0+ (1,0) [0|1.84467E+019] "unitless"  TSTR

BO_ 392 HeadUpDisplayStat: 8 GENERIC
 SG_ HudShifPoint_N_Actl : 29|6@0+ (100,2000) [2000|8300] "rpm" Vector__XXX
 SG_ HudMde_D_Stat : 18|3@0+ (1,0) [0|7] "SED" Vector__XXX
 SG_ HudLedMde_D_Stat : 31|2@0+ (1,0) [0|3] "SED" Vector__XXX
 SG_ HudLedIntns_Pc_Actl : 39|7@0+ (1,0) [0|127] "percent" Vector__XXX
 SG_ HudLed9On_B_Stat : 12|1@0+ (1,0) [0|1] "SED" Vector__XXX
 SG_ HudLed8On_B_Stat : 13|1@0+ (1,0) [0|1] "SED" Vector__XXX
 SG_ HudLed7On_B_Stat : 14|1@0+ (1,0) [0|1] "SED" Vector__XXX
 SG_ Hud_B_Falt : 5|1@0+ (1,0) [0|1] "SED" Vector__XXX
 SG_ HudActv_B_Actl : 7|1@0+ (1,0) [0|1] "SED" Vector__XXX
 SG_ Hud_B_Avail : 6|1@0+ (1,0) [0|1] "SED" Vector__XXX
 SG_ HudLed6On_B_Stat : 15|1@0+ (1,0) [0|1] "SED" Vector__XXX
 SG_ HudLed5On_B_Stat : 0|1@0+ (1,0) [0|1] "SED" Vector__XXX
 SG_ HudLed4On_B_Stat : 1|1@0+ (1,0) [0|1] "SED" Vector__XXX
 SG_ HudLed3On_B_Stat : 2|1@0+ (1,0) [0|1] "SED" Vector__XXX
 SG_ HudLed2On_B_Stat : 3|1@0+ (1,0) [0|1] "SED" Vector__XXX
 SG_ HudLed1On_B_Stat : 4|1@0+ (1,0) [0|1] "SED" Vector__XXX
 SG_ HudLed18On_B_Stat : 19|1@0+ (1,0) [0|1] "SED" Vector__XXX
 SG_ HudLed17On_B_Stat : 20|1@0+ (1,0) [0|1] "SED" Vector__XXX
 SG_ HudLed16On_B_Stat : 21|1@0+ (1,0) [0|1] "SED" Vector__XXX
 SG_ HudLed15On_B_Stat : 22|1@0+ (1,0) [0|1] "SED" Vector__XXX
 SG_ HudLed14On_B_Stat : 23|1@0+ (1,0) [0|1] "SED" Vector__XXX
 SG_ HudLed13On_B_Stat : 8|1@0+ (1,0) [0|1] "SED" Vector__XXX
 SG_ HudLed12On_B_Stat : 9|1@0+ (1,0) [0|1] "SED" Vector__XXX
 SG_ HudLed11On_B_Stat : 10|1@0+ (1,0) [0|1] "SED" Vector__XXX
 SG_ HudLed10On_B_Stat : 11|1@0+ (1,0) [0|1] "SED" Vector__XXX

BO_TX_BU_ 129 : SASM,SCCM;
BO_TX_BU_ 1946 : ATCM_DMSM,ATCM_FFSM,ATCM;
CM_ BO_ 531 "When PBM is present use 0x41B for PrkMsgTxt_D_Rq, PrkBrkRedLamp_D_Rq, PrkBrkYwLamp_D_Rq source signals otherwise ABS will source from 0x213.";
CM_ SG_ 604 WhlDirAvgDrv_D_Actl "48V mHEV: ECM_HEVDSL is Tx,  MHT HEV: PCM_HEV is Tx,  Powersplit HEV: SOBDMC_HPCM is Tx";
CM_ SG_ 604 PrplTqMnRgen_B_Actl "48V mHEV: ECM_HEVDSL is Tx,  MHT HEV: PCM_HEV is Tx,  Powersplit HEV: SOBDMC_HPCM is Tx";
CM_ BO_ 2015 "OBDII Request ($7DF) messages are for FNOS 1.0.1 only.
Diagnostic Functional Addressing ($7DF) and Dual Rate Periodic messages are for FNOS I3 only.";
CM_ SG_ 118 SteWhlCompAnEst_D_Qf "Legacy signal not supported, reserving bit locations for commodity BCM, PAM, RCM, APIM dbc files.  GWM to Tx Init value, no valid data. ";
CM_ SG_ 118 SteWhlComp_An_Est "Legacy signal not supported, reserving bit locations for commodity BCM, PAM, RCM, APIM dbc files.  GWM to Tx Init value, no valid data. ";
CM_ BO_ 74 "Reserve eCallNotification message";
CM_ SG_ 947 Dimming_Lvl "Refer to Vehicle Interior Illum Dimming Ctrl Sys Eng Spec, Table 2

";
CM_ SG_ 947 PrkBrkActv_B_Actl "Signal not transmitted on vehicles with electric park brake. ";
CM_ SG_ 129 SelDrvMdeSwtch3_D_Stat4 "ECM_HEV does not support or Transmit signal.";
CM_ SG_ 1046 TCMode "Signal data set to 0x0 for ABS only vehicle option content";
CM_ SG_ 1046 DrvAntiLckLamp_D_Rq "update value table v8.34, not align w/GSDB, need etracker.  ABS & IPC implemented as updated.";
CM_ SG_ 534 BrkObdData_No_Actl "Signal not transmitted on gas, diesel and HEV.  Only supported on PHEV.";
CM_ SG_ 534 BrkObdIndex_No_Actl "Signal not transmitted on gas, diesel and HEV.  Only supported on PHEV.";
CM_ SG_ 534 WhlRotatRr_No_Cnt "DCR 1833 to update Tx from GWM to EP100ms. Wheel Count signals are used by complex algorithm to determine Tire Pressure by Location & can't change from 20msec. (jweinfur)";
CM_ SG_ 534 WhlRotatRl_No_Cnt "DCR 1833 to update Tx from GWM to EP100ms. Wheel Count signals are used by complex algorithm to determine Tire Pressure by Location & can't change from 20msec. (jweinfur)";
CM_ SG_ 534 WhlRotatFr_No_Cnt "DCR 1833 to update Tx from GWM to EP100ms. Wheel Count signals are used by complex algorithm to determine Tire Pressure by Location & can't change from 20msec. (jweinfur)";
CM_ SG_ 534 WhlRotatFl_No_Cnt "DCR 1833 to update Tx from GWM to EP100ms. Wheel Count signals are used by complex algorithm to determine Tire Pressure by Location & can't change from 20msec. (jweinfur)";
CM_ SG_ 1093 StopLamp_B_RqTrlrBrk "Signal not transmitted on all variants.";
CM_ BO_ 130 "drecker 10/23/09 Need SAPP in sync w/Strg Torque for proper PAM interpretation, else fault msg's displayed FP@20ms IPC needs EPAS_Failure for msg to driver.  Not map w/Lane Assist FP@30s FP), save bandwidth if feature not on vehicle ";
CM_ SG_ 130 VehVTrlrAid_B_Rq "VR session start- req. limit blower speed no more than X volts.  CC restriction on time msg. will be honored.Double Event msg1st event to request limit, 2nd event to release limit, No msg. CC Grammar v7.xls";
CM_ SG_ 130 SteMdule_U_Meas "DCR 1745  to update Tx from GWM to EP100ms. SteMdule_I_Est & SteMdule_U_Meas are used by BMS system & filtered. The filter uses standard periodic rate & changing to EP would adversely affect the filter.(jweinfur)";
CM_ SG_ 130 SteMdule_I_Est "DCR 1745  to update Tx from GWM to EP100ms. SteMdule_I_Est & SteMdule_U_Meas are used by BMS system & filtered. The filter uses standard periodic rate & changing to EP would adversely affect the filter.(jweinfur)";
CM_ BO_ 827 "MSGDCR 000176 HUD_ADV requested EP 60ms.   ";
BA_DEF_ BO_  "FrameRouting" STRING ;
BA_DEF_ BO_  "FrameGatewayNetwork" STRING ;
BA_DEF_ BO_  "NetworkInitialization" ENUM  "No","Yes";
BA_DEF_ BO_  "FrameGatewayId" HEX 0 1407;
BA_DEF_ BO_  "EventRateOfChange" INT 10 10000;
BA_DEF_ BO_  "GenMsgNrOfRepetition" INT 0 100;
BA_DEF_ BO_  "GenMsgDelayTime" INT 0 1000;
BA_DEF_ BO_  "GenMsgCycleTime" INT 0 100000;
BA_DEF_ BO_  "GenMsgSendType" ENUM  "FixedPeriodic","Event","EnabledPeriodic","NotUsed","NotUsed","EventPeriodic","NotUsed","NotUsed","NoMsgSendType";
BA_DEF_ SG_  "U_CD764_MY2022_Tx" ENUM  "No","Yes";
BA_DEF_ SG_  "U_U55X_MY2022_Tx" ENUM  "No","Yes";
BA_DEF_ SG_  "U_CD542_MY2021_Tx" ENUM  "No","Yes";
BA_DEF_ SG_  "ECGUsedTxSignal" ENUM  "No","Yes";
BA_DEF_ SG_  "U_T6_MCA_MY2020_Tx" ENUM  "No","Yes";
BA_DEF_ SG_  "U_P702_MY2021_Tx" ENUM  "No","Yes";
BA_DEF_ SG_  "U_CX727_MY2021_Tx" ENUM  "No","Yes";
BA_DEF_ SG_  "U_CD764_MY2022_Rx" ENUM  "No","Yes";
BA_DEF_ SG_  "U_U55X_MY2022_Rx" ENUM  "No","Yes";
BA_DEF_ SG_  "U_CD542_MY2021_Rx" ENUM  "No","Yes";
BA_DEF_ SG_  "ECGUsedRxSignal" ENUM  "No","Yes";
BA_DEF_ SG_  "U_T6_MCA_MY2020_Rx" ENUM  "No","Yes";
BA_DEF_ SG_  "U_P702_MY2021_Rx" ENUM  "No","Yes";
BA_DEF_ SG_  "U_CX727_MY2021_Rx" ENUM  "No","Yes";
BA_DEF_ SG_  "GenSigStartValue" HEX 0 268435455;
BA_DEF_ SG_  "MetaData" ENUM  "No","Yes";
BA_DEF_ SG_  "ContentDependant" ENUM  "No","Yes";
BA_DEF_ SG_  "GenSigStartValueInteger" INT 0 1000000000;
BA_DEF_ SG_  "UsedOnPgmDBC" ENUM  "No","Yes";
BA_DEF_ SG_  "WakeupSignal" ENUM  "No","Yes";
BA_DEF_ SG_  "GenSigInactiveValue" INT 0 100000;
BA_DEF_ SG_  "GenSigSendType" ENUM  "Cyclic","OnWrite","vector_leerstring","OnChange","vector_leerstring","IfActive","vector_leerstring","NoSigSendType";
BA_DEF_ BO_  "OvtpPushApplication" ENUM  "FALSE","TRUE";
BA_DEF_ BO_  "SCP_FreshnessValueLength" INT 0 512;
BA_DEF_ BO_  "SCP_FreshnessValueTxLength" INT 0 512;
BA_DEF_ BO_  "SCP_AuthInfoTxLength" INT 0 512;
BA_DEF_ BO_  "GenMsgRoutingTimeoutTime" INT 0 5000;
BA_DEF_ BO_  "MessageGateway" ENUM  "No","Yes";
BA_DEF_ BO_  "NmAsrMessage" ENUM  "No","Yes";
BA_DEF_ BO_  "TpApplType" STRING ;
BA_DEF_ BO_  "DiagState" ENUM  "No","Yes";
BA_DEF_ BO_  "TpTxIndex" INT 0 536870911;
BA_DEF_ BO_  "DiagRequest" ENUM  "No","Yes";
BA_DEF_ BO_  "DiagResponse" ENUM  "No","Yes";
BA_DEF_ BO_  "GenMsgILSupport" ENUM  "No","Yes";
BA_DEF_DEF_  "FrameRouting" "";
BA_DEF_DEF_  "FrameGatewayNetwork" "NONE";
BA_DEF_DEF_  "NetworkInitialization" "Yes";
BA_DEF_DEF_  "FrameGatewayId" 0;
BA_DEF_DEF_  "EventRateOfChange" 10000;
BA_DEF_DEF_  "GenMsgNrOfRepetition" 1;
BA_DEF_DEF_  "GenMsgDelayTime" 20;
BA_DEF_DEF_  "GenMsgCycleTime" 0;
BA_DEF_DEF_  "GenMsgSendType" "NoMsgSendType";
BA_DEF_DEF_  "U_CD764_MY2022_Tx" "No";
BA_DEF_DEF_  "U_U55X_MY2022_Tx" "No";
BA_DEF_DEF_  "U_CD542_MY2021_Tx" "No";
BA_DEF_DEF_  "ECGUsedTxSignal" "No";
BA_DEF_DEF_  "U_T6_MCA_MY2020_Tx" "No";
BA_DEF_DEF_  "U_P702_MY2021_Tx" "No";
BA_DEF_DEF_  "U_CX727_MY2021_Tx" "No";
BA_DEF_DEF_  "U_CD764_MY2022_Rx" "No";
BA_DEF_DEF_  "U_U55X_MY2022_Rx" "No";
BA_DEF_DEF_  "U_CD542_MY2021_Rx" "No";
BA_DEF_DEF_  "ECGUsedRxSignal" "No";
BA_DEF_DEF_  "U_T6_MCA_MY2020_Rx" "No";
BA_DEF_DEF_  "U_P702_MY2021_Rx" "No";
BA_DEF_DEF_  "U_CX727_MY2021_Rx" "No";
BA_DEF_DEF_  "GenSigStartValue" 0;
BA_DEF_DEF_  "MetaData" "No";
BA_DEF_DEF_  "ContentDependant" "No";
BA_DEF_DEF_  "GenSigStartValueInteger" 0;
BA_DEF_DEF_  "UsedOnPgmDBC" "Yes";
BA_DEF_DEF_  "WakeupSignal" "No";
BA_DEF_DEF_  "GenSigInactiveValue" 0;
BA_DEF_DEF_  "GenSigSendType" "NoSigSendType";
BA_DEF_DEF_  "OvtpPushApplication" "FALSE";
BA_DEF_DEF_  "SCP_FreshnessValueLength" 64;
BA_DEF_DEF_  "SCP_FreshnessValueTxLength" 11;
BA_DEF_DEF_  "SCP_AuthInfoTxLength" 53;
BA_DEF_DEF_  "GenMsgRoutingTimeoutTime" 0;
BA_DEF_DEF_  "MessageGateway" "No";
BA_DEF_DEF_  "NmAsrMessage" "No";
BA_DEF_DEF_  "TpApplType" "";
BA_DEF_DEF_  "DiagState" "No";
BA_DEF_DEF_  "TpTxIndex" 0;
BA_DEF_DEF_  "DiagRequest" "No";
BA_DEF_DEF_  "DiagResponse" "No";
BA_DEF_DEF_  "GenMsgILSupport" "Yes";
BA_ "FrameRouting" BO_ 391 "FD1_CAN,0x187;HS2_CAN,0x187;";
BA_ "FrameGatewayNetwork" BO_ 391 "FD1_CAN";
BA_ "FrameGatewayId" BO_ 391 391;
BA_ "FrameRouting" BO_ 535 "FD1_CAN,0x217;";
BA_ "FrameGatewayNetwork" BO_ 535 "FD1_CAN";
BA_ "FrameGatewayId" BO_ 535 535;
BA_ "FrameRouting" BO_ 531 "FD1_CAN,0x213;";
BA_ "FrameGatewayNetwork" BO_ 531 "FD1_CAN";
BA_ "FrameGatewayId" BO_ 531 531;
BA_ "GenMsgDelayTime" BO_ 137 0;
BA_ "GenMsgCycleTime" BO_ 137 10;
BA_ "GenMsgSendType" BO_ 137 0;
BA_ "FrameRouting" BO_ 136 "FD1_CAN,0x88;";
BA_ "FrameGatewayNetwork" BO_ 136 "FD1_CAN";
BA_ "FrameGatewayId" BO_ 136 136;
BA_ "GenMsgCycleTime" BO_ 604 100;
BA_ "GenMsgSendType" BO_ 604 5;
BA_ "NetworkInitialization" BO_ 2015 0;
BA_ "GenMsgDelayTime" BO_ 2015 0;
BA_ "GenMsgSendType" BO_ 2015 1;
BA_ "DiagState" BO_ 2015 1;
BA_ "GenMsgILSupport" BO_ 2015 0;
BA_ "FrameRouting" BO_ 125 "FD1_CAN,0x7D;";
BA_ "FrameGatewayNetwork" BO_ 125 "FD1_CAN";
BA_ "FrameGatewayId" BO_ 125 125;
BA_ "FrameRouting" BO_ 119 "FD1_CAN,0x77;";
BA_ "FrameGatewayNetwork" BO_ 119 "FD1_CAN";
BA_ "FrameGatewayId" BO_ 119 119;
BA_ "FrameRouting" BO_ 118 "FD1_CAN,0x76;";
BA_ "FrameGatewayNetwork" BO_ 118 "FD1_CAN";
BA_ "FrameGatewayId" BO_ 118 118;
BA_ "GenMsgDelayTime" BO_ 75 10;
BA_ "GenMsgCycleTime" BO_ 75 100;
BA_ "GenMsgSendType" BO_ 75 5;
BA_ "GenMsgDelayTime" BO_ 74 10;
BA_ "GenMsgCycleTime" BO_ 74 100;
BA_ "GenMsgSendType" BO_ 74 5;
BA_ "FrameRouting" BO_ 947 "HS1_CAN,0x3B3;";
BA_ "FrameGatewayNetwork" BO_ 947 "HS1_CAN";
BA_ "FrameGatewayId" BO_ 947 947;
BA_ "GenMsgCycleTime" BO_ 131 100;
BA_ "GenMsgSendType" BO_ 131 5;
BA_ "MessageGateway" BO_ 131 1;
BA_ "FrameRouting" BO_ 992 "HS3_CAN,0x3E0;";
BA_ "FrameGatewayNetwork" BO_ 992 "HS3_CAN";
BA_ "FrameGatewayId" BO_ 992 992;
BA_ "FrameRouting" BO_ 970 "FD1_CAN,0x3CA;";
BA_ "FrameGatewayNetwork" BO_ 970 "FD1_CAN";
BA_ "FrameGatewayId" BO_ 970 970;
BA_ "GenMsgCycleTime" BO_ 129 1000;
BA_ "GenMsgSendType" BO_ 129 5;
BA_ "NetworkInitialization" BO_ 1833 0;
BA_ "GenMsgDelayTime" BO_ 1833 0;
BA_ "GenMsgSendType" BO_ 1833 1;
BA_ "DiagResponse" BO_ 1833 1;
BA_ "GenMsgILSupport" BO_ 1833 0;
BA_ "FrameRouting" BO_ 1109 "HS3_CAN,0x455;";
BA_ "FrameGatewayNetwork" BO_ 1109 "HS3_CAN";
BA_ "FrameGatewayId" BO_ 1109 1109;
BA_ "FrameRouting" BO_ 1046 "FD1_CAN,0x416;";
BA_ "FrameGatewayNetwork" BO_ 1046 "FD1_CAN";
BA_ "FrameGatewayId" BO_ 1046 1046;
BA_ "FrameRouting" BO_ 534 "FD1_CAN,0x216;";
BA_ "FrameGatewayNetwork" BO_ 534 "FD1_CAN";
BA_ "FrameGatewayId" BO_ 534 534;
BA_ "FrameRouting" BO_ 1093 "HS3_CAN,0x445;";
BA_ "FrameGatewayNetwork" BO_ 1093 "HS3_CAN";
BA_ "FrameGatewayId" BO_ 1093 1093;
BA_ "FrameRouting" BO_ 994 "HS3_CAN,0x3E2;";
BA_ "FrameGatewayNetwork" BO_ 994 "HS3_CAN";
BA_ "FrameGatewayId" BO_ 994 994;
BA_ "NetworkInitialization" BO_ 1836 0;
BA_ "GenMsgDelayTime" BO_ 1836 0;
BA_ "GenMsgSendType" BO_ 1836 1;
BA_ "DiagResponse" BO_ 1836 1;
BA_ "GenMsgILSupport" BO_ 1836 0;
BA_ "NetworkInitialization" BO_ 1825 0;
BA_ "GenMsgDelayTime" BO_ 1825 0;
BA_ "GenMsgSendType" BO_ 1825 1;
BA_ "DiagRequest" BO_ 1825 1;
BA_ "GenMsgILSupport" BO_ 1825 0;
BA_ "GenMsgCycleTime" BO_ 1108 1000;
BA_ "GenMsgSendType" BO_ 1108 0;
BA_ "GenMsgCycleTime" BO_ 1107 1000;
BA_ "GenMsgSendType" BO_ 1107 0;
BA_ "NetworkInitialization" BO_ 1879 0;
BA_ "GenMsgDelayTime" BO_ 1879 0;
BA_ "GenMsgSendType" BO_ 1879 1;
BA_ "DiagRequest" BO_ 1879 1;
BA_ "GenMsgILSupport" BO_ 1879 0;
BA_ "GenMsgDelayTime" BO_ 145 0;
BA_ "GenMsgCycleTime" BO_ 145 10;
BA_ "GenMsgSendType" BO_ 145 0;
BA_ "NetworkInitialization" BO_ 1828 0;
BA_ "GenMsgDelayTime" BO_ 1828 0;
BA_ "GenMsgSendType" BO_ 1828 1;
BA_ "DiagRequest" BO_ 1828 1;
BA_ "GenMsgILSupport" BO_ 1828 0;
BA_ "FrameRouting" BO_ 1045 "FD1_CAN,0x415;";
BA_ "FrameGatewayNetwork" BO_ 1045 "FD1_CAN";
BA_ "FrameGatewayId" BO_ 1045 1045;
BA_ "GenMsgDelayTime" BO_ 146 0;
BA_ "GenMsgCycleTime" BO_ 146 10;
BA_ "GenMsgSendType" BO_ 146 0;
BA_ "GenMsgCycleTime" BO_ 1152 100;
BA_ "GenMsgSendType" BO_ 1152 0;
BA_ "NetworkInitialization" BO_ 1938 0;
BA_ "GenMsgDelayTime" BO_ 1938 0;
BA_ "GenMsgSendType" BO_ 1938 1;
BA_ "DiagRequest" BO_ 1938 1;
BA_ "GenMsgILSupport" BO_ 1938 0;
BA_ "FrameRouting" BO_ 984 "FD1_CAN,0x3D8;";
BA_ "FrameGatewayNetwork" BO_ 984 "FD1_CAN";
BA_ "FrameGatewayId" BO_ 984 984;
BA_ "GenMsgCycleTime" BO_ 998 1000;
BA_ "GenMsgSendType" BO_ 998 5;
BA_ "GenMsgCycleTime" BO_ 613 1000;
BA_ "GenMsgSendType" BO_ 613 5;
BA_ "NetworkInitialization" BO_ 1664 0;
BA_ "GenMsgSendType" BO_ 1664 1;
BA_ "TpApplType" BO_ 1664 "DiagUUDTResponse";
BA_ "GenMsgILSupport" BO_ 1664 0;
BA_ "NetworkInitialization" BO_ 1814 0;
BA_ "GenMsgDelayTime" BO_ 1814 0;
BA_ "GenMsgSendType" BO_ 1814 1;
BA_ "DiagRequest" BO_ 1814 1;
BA_ "GenMsgILSupport" BO_ 1814 0;
BA_ "NetworkInitialization" BO_ 2033 0;
BA_ "GenMsgDelayTime" BO_ 2033 0;
BA_ "GenMsgSendType" BO_ 2033 1;
BA_ "GenMsgILSupport" BO_ 2033 0;
BA_ "FrameRouting" BO_ 130 "FD1_CAN,0x82;";
BA_ "FrameGatewayNetwork" BO_ 130 "FD1_CAN";
BA_ "FrameGatewayId" BO_ 130 130;
BA_ "NetworkInitialization" BO_ 1855 0;
BA_ "GenMsgDelayTime" BO_ 1855 0;
BA_ "GenMsgSendType" BO_ 1855 1;
BA_ "DiagResponse" BO_ 1855 1;
BA_ "GenMsgILSupport" BO_ 1855 0;
BA_ "NetworkInitialization" BO_ 1847 0;
BA_ "GenMsgDelayTime" BO_ 1847 0;
BA_ "GenMsgSendType" BO_ 1847 1;
BA_ "DiagRequest" BO_ 1847 1;
BA_ "GenMsgILSupport" BO_ 1847 0;
BA_ "GenMsgCycleTime" BO_ 827 60;
BA_ "GenMsgSendType" BO_ 827 5;
BA_ "MessageGateway" BO_ 827 1;
BA_ "FrameRouting" BO_ 848 "HS3_CAN,0x350;";
BA_ "FrameGatewayNetwork" BO_ 848 "HS3_CAN";
BA_ "FrameGatewayId" BO_ 848 848;
BA_ "NetworkInitialization" BO_ 1822 0;
BA_ "GenMsgDelayTime" BO_ 1822 0;
BA_ "GenMsgSendType" BO_ 1822 1;
BA_ "DiagResponse" BO_ 1822 1;
BA_ "GenMsgILSupport" BO_ 1822 0;
BA_ "NetworkInitialization" BO_ 1901 0;
BA_ "GenMsgDelayTime" BO_ 1901 0;
BA_ "GenMsgSendType" BO_ 1901 1;
BA_ "DiagResponse" BO_ 1901 1;
BA_ "GenMsgILSupport" BO_ 1901 0;
BA_ "NetworkInitialization" BO_ 1893 0;
BA_ "GenMsgDelayTime" BO_ 1893 0;
BA_ "GenMsgSendType" BO_ 1893 1;
BA_ "DiagRequest" BO_ 1893 1;
BA_ "GenMsgILSupport" BO_ 1893 0;
BA_ "NetworkInitialization" BO_ 1946 0;
BA_ "GenMsgDelayTime" BO_ 1946 0;
BA_ "GenMsgSendType" BO_ 1946 1;
BA_ "DiagResponse" BO_ 1946 1;
BA_ "GenMsgILSupport" BO_ 1946 0;
BA_ "NetworkInitialization" BO_ 1887 0;
BA_ "GenMsgDelayTime" BO_ 1887 0;
BA_ "GenMsgSendType" BO_ 1887 1;
BA_ "DiagResponse" BO_ 1887 1;
BA_ "GenMsgILSupport" BO_ 1887 0;
BA_ "GenMsgCycleTime" BO_ 392 1000;
BA_ "GenMsgSendType" BO_ 392 5;
BA_ "GenSigStartValue" SG_ 391 CadsRadarStat_D_Qf 1;
BA_ "MetaData" SG_ 391 CadsRadarStat_D_Qf 1;
BA_ "GenSigStartValueInteger" SG_ 391 CadsRadarStat_D_Qf 1;
BA_ "MetaData" SG_ 391 CmbbBrkDecel_No_Cnt 1;
BA_ "MetaData" SG_ 391 CmbbBrkDecel_No_Cs 1;
BA_ "U_CD764_MY2022_Rx" SG_ 391 CmbbBrkDecel_A_Rq 1;
BA_ "U_U55X_MY2022_Rx" SG_ 391 CmbbBrkDecel_A_Rq 1;
BA_ "U_CD542_MY2021_Rx" SG_ 391 CmbbBrkDecel_A_Rq 1;
BA_ "U_T6_MCA_MY2020_Rx" SG_ 391 CmbbBrkDecel_A_Rq 1;
BA_ "U_P702_MY2021_Rx" SG_ 391 CmbbBrkDecel_A_Rq 1;
BA_ "U_CX727_MY2021_Rx" SG_ 391 CmbbBrkDecel_A_Rq 1;
BA_ "GenSigStartValueInteger" SG_ 391 CmbbBrkDecel_A_Rq 5129;
BA_ "U_CD764_MY2022_Rx" SG_ 391 CmbbBrkPrchg_D_Rq 1;
BA_ "U_U55X_MY2022_Rx" SG_ 391 CmbbBrkPrchg_D_Rq 1;
BA_ "U_CD542_MY2021_Rx" SG_ 391 CmbbBrkPrchg_D_Rq 1;
BA_ "U_T6_MCA_MY2020_Rx" SG_ 391 CmbbBrkPrchg_D_Rq 1;
BA_ "U_P702_MY2021_Rx" SG_ 391 CmbbBrkPrchg_D_Rq 1;
BA_ "U_CX727_MY2021_Rx" SG_ 391 CmbbBrkPrchg_D_Rq 1;
BA_ "U_CD764_MY2022_Rx" SG_ 391 CmbbBrkDecel_B_Rq 1;
BA_ "U_U55X_MY2022_Rx" SG_ 391 CmbbBrkDecel_B_Rq 1;
BA_ "U_CD542_MY2021_Rx" SG_ 391 CmbbBrkDecel_B_Rq 1;
BA_ "U_T6_MCA_MY2020_Rx" SG_ 391 CmbbBrkDecel_B_Rq 1;
BA_ "U_P702_MY2021_Rx" SG_ 391 CmbbBrkDecel_B_Rq 1;
BA_ "U_CX727_MY2021_Rx" SG_ 391 CmbbBrkDecel_B_Rq 1;
BA_ "U_CD764_MY2022_Rx" SG_ 391 CmbbBaSens_D_Rq 1;
BA_ "U_U55X_MY2022_Rx" SG_ 391 CmbbBaSens_D_Rq 1;
BA_ "U_CD542_MY2021_Rx" SG_ 391 CmbbBaSens_D_Rq 1;
BA_ "U_T6_MCA_MY2020_Rx" SG_ 391 CmbbBaSens_D_Rq 1;
BA_ "U_P702_MY2021_Rx" SG_ 391 CmbbBaSens_D_Rq 1;
BA_ "U_CX727_MY2021_Rx" SG_ 391 CmbbBaSens_D_Rq 1;
BA_ "U_CD764_MY2022_Rx" SG_ 535 WhlRr_W_Meas 1;
BA_ "U_T6_MCA_MY2020_Rx" SG_ 535 WhlRr_W_Meas 1;
BA_ "U_CD764_MY2022_Rx" SG_ 535 WhlRl_W_Meas 1;
BA_ "U_T6_MCA_MY2020_Rx" SG_ 535 WhlRl_W_Meas 1;
BA_ "U_CD764_MY2022_Rx" SG_ 535 WhlFr_W_Meas 1;
BA_ "U_T6_MCA_MY2020_Rx" SG_ 535 WhlFr_W_Meas 1;
BA_ "U_CD764_MY2022_Rx" SG_ 535 WhlFl_W_Meas 1;
BA_ "U_T6_MCA_MY2020_Rx" SG_ 535 WhlFl_W_Meas 1;
BA_ "GenSigStartValue" SG_ 531 VehStop_D_Stat 2;
BA_ "GenSigStartValueInteger" SG_ 531 VehStop_D_Stat 2;
BA_ "U_CD764_MY2022_Rx" SG_ 531 TracCtlPtActv_B_Actl 1;
BA_ "U_U55X_MY2022_Rx" SG_ 531 TracCtlPtActv_B_Actl 1;
BA_ "U_CD542_MY2021_Rx" SG_ 531 TracCtlPtActv_B_Actl 1;
BA_ "U_T6_MCA_MY2020_Rx" SG_ 531 TracCtlPtActv_B_Actl 1;
BA_ "U_P702_MY2021_Rx" SG_ 531 TracCtlPtActv_B_Actl 1;
BA_ "U_CX727_MY2021_Rx" SG_ 531 TracCtlPtActv_B_Actl 1;
BA_ "WakeupSignal" SG_ 531 PrkBrkYwLamp_D_Rq 1;
BA_ "WakeupSignal" SG_ 531 PrkBrkRedLamp_D_Rq 1;
BA_ "U_CD764_MY2022_Rx" SG_ 531 AbsActv_B_Actl 1;
BA_ "U_U55X_MY2022_Rx" SG_ 531 AbsActv_B_Actl 1;
BA_ "U_CD542_MY2021_Rx" SG_ 531 AbsActv_B_Actl 1;
BA_ "U_T6_MCA_MY2020_Rx" SG_ 531 AbsActv_B_Actl 1;
BA_ "U_CX727_MY2021_Rx" SG_ 531 AbsActv_B_Actl 1;
BA_ "U_P702_MY2021_Rx" SG_ 531 AbsActv_B_Actl 1;
BA_ "U_CD764_MY2022_Rx" SG_ 531 StabCtlBrkActv_B_Actl 1;
BA_ "U_U55X_MY2022_Rx" SG_ 531 StabCtlBrkActv_B_Actl 1;
BA_ "U_CD542_MY2021_Rx" SG_ 531 StabCtlBrkActv_B_Actl 1;
BA_ "U_T6_MCA_MY2020_Rx" SG_ 531 StabCtlBrkActv_B_Actl 1;
BA_ "U_P702_MY2021_Rx" SG_ 531 StabCtlBrkActv_B_Actl 1;
BA_ "U_CX727_MY2021_Rx" SG_ 531 StabCtlBrkActv_B_Actl 1;
BA_ "U_P702_MY2021_Rx" SG_ 531 CmbbBrkPrchg_B_Actl 1;
BA_ "U_P702_MY2021_Rx" SG_ 531 CmbbBrkDecel_B_Actl 1;
BA_ "U_P702_MY2021_Rx" SG_ 531 AccBrkTotTqMn_B_Actl 1;
BA_ "U_P702_MY2021_Rx" SG_ 531 VehLongOvrGnd_A_Est 1;
BA_ "GenSigStartValueInteger" SG_ 531 VehLongOvrGnd_A_Est 511;
BA_ "WakeupSignal" SG_ 531 PrkBrkMsgTxt_D_Rq 1;
BA_ "U_U55X_MY2022_Rx" SG_ 531 PrkBrkStatus 1;
BA_ "U_CD542_MY2021_Rx" SG_ 531 PrkBrkStatus 1;
BA_ "U_T6_MCA_MY2020_Rx" SG_ 531 PrkBrkStatus 1;
BA_ "U_P702_MY2021_Rx" SG_ 531 PrkBrkStatus 1;
BA_ "U_CX727_MY2021_Rx" SG_ 531 PrkBrkStatus 1;
BA_ "U_CD764_MY2022_Rx" SG_ 531 PrkBrkStatus 1;
BA_ "GenSigStartValue" SG_ 531 PrkBrkStatus 7;
BA_ "GenSigStartValueInteger" SG_ 531 PrkBrkStatus 7;
BA_ "U_P702_MY2021_Tx" SG_ 137 SteWhlOffstRq_D_Stat 1;
BA_ "GenSigStartValue" SG_ 137 SteWhlOffstRq_D_Stat 2;
BA_ "GenSigStartValueInteger" SG_ 137 SteWhlOffstRq_D_Stat 2;
BA_ "U_P702_MY2021_Tx" SG_ 137 SteWhlOffst_An_TotActl 1;
BA_ "GenSigStartValue" SG_ 137 SteWhlOffst_An_TotActl 32765;
BA_ "GenSigStartValueInteger" SG_ 137 SteWhlOffst_An_TotActl 32766;
BA_ "U_P702_MY2021_Tx" SG_ 137 SteWhlBrkOffst_An_Actl 1;
BA_ "GenSigStartValue" SG_ 137 SteWhlBrkOffst_An_Actl 32765;
BA_ "GenSigStartValueInteger" SG_ 137 SteWhlBrkOffst_An_Actl 32766;
BA_ "U_P702_MY2021_Tx" SG_ 137 SteWhlBrkAnActl_No_Cs 1;
BA_ "MetaData" SG_ 137 SteWhlBrkAnActl_No_Cs 1;
BA_ "U_P702_MY2021_Tx" SG_ 137 SteWhlBrkAnActl_No_Cnt 1;
BA_ "MetaData" SG_ 137 SteWhlBrkAnActl_No_Cnt 1;
BA_ "U_P702_MY2021_Rx" SG_ 136 SteWhlBrkOffst_An_Rq 1;
BA_ "GenSigStartValue" SG_ 136 SteWhlBrkOffst_An_Rq 32765;
BA_ "GenSigStartValueInteger" SG_ 136 SteWhlBrkOffst_An_Rq 32766;
BA_ "U_P702_MY2021_Rx" SG_ 136 SteWhlBrkAnRq_No_Cs 1;
BA_ "MetaData" SG_ 136 SteWhlBrkAnRq_No_Cs 1;
BA_ "U_P702_MY2021_Rx" SG_ 136 SteWhlBrkAnRq_No_Cnt 1;
BA_ "MetaData" SG_ 136 SteWhlBrkAnRq_No_Cnt 1;
BA_ "U_CD764_MY2022_Rx" SG_ 604 WhlDirAvgDrv_D_Actl 1;
BA_ "U_T6_MCA_MY2020_Rx" SG_ 604 WhlDirAvgDrv_D_Actl 1;
BA_ "ContentDependant" SG_ 604 WhlDirAvgDrv_D_Actl 1;
BA_ "ContentDependant" SG_ 604 PrplTqMnRgen_B_Actl 1;
BA_ "ECGUsedRxSignal" SG_ 2015 TesterFunctionalReq 1;
BA_ "U_CD764_MY2022_Rx" SG_ 2015 TesterFunctionalReq 1;
BA_ "U_U55X_MY2022_Rx" SG_ 2015 TesterFunctionalReq 1;
BA_ "U_CD542_MY2021_Rx" SG_ 2015 TesterFunctionalReq 1;
BA_ "U_T6_MCA_MY2020_Rx" SG_ 2015 TesterFunctionalReq 1;
BA_ "U_CX727_MY2021_Rx" SG_ 2015 TesterFunctionalReq 1;
BA_ "U_P702_MY2021_Rx" SG_ 2015 TesterFunctionalReq 1;
BA_ "GenSigSendType" SG_ 2015 TesterFunctionalReq 3;
BA_ "GenSigStartValue" SG_ 125 VehRolComp_W_Actl 4094;
BA_ "GenSigStartValueInteger" SG_ 125 VehRolComp_W_Actl 4094;
BA_ "GenSigStartValue" SG_ 125 VehVertComp_A_Actl 1022;
BA_ "GenSigStartValueInteger" SG_ 125 VehVertComp_A_Actl 1022;
BA_ "U_P702_MY2021_Rx" SG_ 125 BrkTotTqRqArb_No_Cs 1;
BA_ "MetaData" SG_ 125 BrkTotTqRqArb_No_Cs 1;
BA_ "U_P702_MY2021_Rx" SG_ 125 BrkTotTqRqArb_No_Cnt 1;
BA_ "MetaData" SG_ 125 BrkTotTqRqArb_No_Cnt 1;
BA_ "U_CD542_MY2021_Rx" SG_ 125 BrkTot_Tq_RqArb 1;
BA_ "U_T6_MCA_MY2020_Rx" SG_ 125 BrkTot_Tq_RqArb 1;
BA_ "U_CX727_MY2021_Rx" SG_ 125 BrkTot_Tq_RqArb 1;
BA_ "U_P702_MY2021_Rx" SG_ 125 BrkTot_Tq_RqArb 1;
BA_ "U_CD764_MY2022_Rx" SG_ 125 BrkTot_Tq_Actl 1;
BA_ "U_U55X_MY2022_Rx" SG_ 125 BrkTot_Tq_Actl 1;
BA_ "U_CD542_MY2021_Rx" SG_ 125 BrkTot_Tq_Actl 1;
BA_ "U_T6_MCA_MY2020_Rx" SG_ 125 BrkTot_Tq_Actl 1;
BA_ "U_P702_MY2021_Rx" SG_ 125 BrkTot_Tq_Actl 1;
BA_ "U_CX727_MY2021_Rx" SG_ 125 BrkTot_Tq_Actl 1;
BA_ "U_P702_MY2021_Rx" SG_ 119 VehTrvlDir_D_Stat 1;
BA_ "GenSigStartValue" SG_ 119 VehTrvlDir_D_Stat 6;
BA_ "GenSigStartValueInteger" SG_ 119 VehTrvlDir_D_Stat 6;
BA_ "U_P702_MY2021_Rx" SG_ 119 VehOverGnd_V_Est 1;
BA_ "GenSigStartValue" SG_ 119 VehLongComp_A_Actl 1022;
BA_ "GenSigStartValueInteger" SG_ 119 VehLongComp_A_Actl 1022;
BA_ "GenSigStartValue" SG_ 119 VehLatComp_A_Actl 1022;
BA_ "GenSigStartValueInteger" SG_ 119 VehLatComp_A_Actl 1022;
BA_ "U_P702_MY2021_Rx" SG_ 119 VehYawComp_W_Actl 1;
BA_ "U_T6_MCA_MY2020_Rx" SG_ 119 VehYawComp_W_Actl 1;
BA_ "GenSigStartValue" SG_ 119 VehYawComp_W_Actl 4094;
BA_ "GenSigStartValueInteger" SG_ 119 VehYawComp_W_Actl 4094;
BA_ "MetaData" SG_ 118 ApaBrkErrDStat_No_Cs 1;
BA_ "MetaData" SG_ 118 ApaBrkErrDStat_No_Cnt 1;
BA_ "GenSigStartValue" SG_ 118 ApaBrkErr_D_Stat 2;
BA_ "U_P702_MY2021_Rx" SG_ 118 BrkCtrFnd_B_Stat 1;
BA_ "GenSigSendType" SG_ 118 DrvSte_D_Stat 3;
BA_ "GenSigStartValueInteger" SG_ 118 DrvSte_Tq_Rq 128;
BA_ "GenSigSendType" SG_ 118 EmgcyBrkLamp_D_Rq 3;
BA_ "GenSigSendType" SG_ 118 StopLamp_B_RqBrk 3;
BA_ "U_P702_MY2021_Rx" SG_ 118 SteWhlCompAnEst_D_Qf 1;
BA_ "U_CX727_MY2021_Rx" SG_ 118 SteWhlCompAnEst_D_Qf 1;
BA_ "MetaData" SG_ 118 SteWhlCompAnEst_D_Qf 1;
BA_ "ContentDependant" SG_ 118 SteWhlCompAnEst_D_Qf 1;
BA_ "U_P702_MY2021_Rx" SG_ 118 SteWhlComp_An_Est 1;
BA_ "U_CX727_MY2021_Rx" SG_ 118 SteWhlComp_An_Est 1;
BA_ "ContentDependant" SG_ 118 SteWhlComp_An_Est 1;
BA_ "U_CD764_MY2022_Tx" SG_ 75 VedsPasKneeBag_D_Ltchd 1;
BA_ "U_U55X_MY2022_Tx" SG_ 75 VedsPasKneeBag_D_Ltchd 1;
BA_ "U_CD542_MY2021_Tx" SG_ 75 VedsPasKneeBag_D_Ltchd 1;
BA_ "U_T6_MCA_MY2020_Tx" SG_ 75 VedsPasKneeBag_D_Ltchd 1;
BA_ "U_P702_MY2021_Tx" SG_ 75 VedsPasKneeBag_D_Ltchd 1;
BA_ "U_CX727_MY2021_Tx" SG_ 75 VedsPasKneeBag_D_Ltchd 1;
BA_ "GenSigSendType" SG_ 75 VedsPasKneeBag_D_Ltchd 3;
BA_ "U_CD764_MY2022_Tx" SG_ 75 VedsRw3pRib_D_Ltchd 1;
BA_ "U_U55X_MY2022_Tx" SG_ 75 VedsRw3pRib_D_Ltchd 1;
BA_ "U_CD542_MY2021_Tx" SG_ 75 VedsRw3pRib_D_Ltchd 1;
BA_ "U_T6_MCA_MY2020_Tx" SG_ 75 VedsRw3pRib_D_Ltchd 1;
BA_ "U_P702_MY2021_Tx" SG_ 75 VedsRw3pRib_D_Ltchd 1;
BA_ "U_CX727_MY2021_Tx" SG_ 75 VedsRw3pRib_D_Ltchd 1;
BA_ "GenSigSendType" SG_ 75 VedsRw3pRib_D_Ltchd 3;
BA_ "U_CD764_MY2022_Tx" SG_ 75 VedsRw3dRib_D_Ltchd 1;
BA_ "U_U55X_MY2022_Tx" SG_ 75 VedsRw3dRib_D_Ltchd 1;
BA_ "U_CD542_MY2021_Tx" SG_ 75 VedsRw3dRib_D_Ltchd 1;
BA_ "U_T6_MCA_MY2020_Tx" SG_ 75 VedsRw3dRib_D_Ltchd 1;
BA_ "U_P702_MY2021_Tx" SG_ 75 VedsRw3dRib_D_Ltchd 1;
BA_ "U_CX727_MY2021_Tx" SG_ 75 VedsRw3dRib_D_Ltchd 1;
BA_ "GenSigSendType" SG_ 75 VedsRw3dRib_D_Ltchd 3;
BA_ "U_CD764_MY2022_Tx" SG_ 75 VedsRw1mBckl_D_Ltchd 1;
BA_ "U_U55X_MY2022_Tx" SG_ 75 VedsRw1mBckl_D_Ltchd 1;
BA_ "U_CD542_MY2021_Tx" SG_ 75 VedsRw1mBckl_D_Ltchd 1;
BA_ "U_T6_MCA_MY2020_Tx" SG_ 75 VedsRw1mBckl_D_Ltchd 1;
BA_ "U_P702_MY2021_Tx" SG_ 75 VedsRw1mBckl_D_Ltchd 1;
BA_ "U_CX727_MY2021_Tx" SG_ 75 VedsRw1mBckl_D_Ltchd 1;
BA_ "GenSigSendType" SG_ 75 VedsRw1mBckl_D_Ltchd 3;
BA_ "U_CD764_MY2022_Tx" SG_ 75 VedsRw1mBelt_D_Ltchd 1;
BA_ "U_U55X_MY2022_Tx" SG_ 75 VedsRw1mBelt_D_Ltchd 1;
BA_ "U_CD542_MY2021_Tx" SG_ 75 VedsRw1mBelt_D_Ltchd 1;
BA_ "U_T6_MCA_MY2020_Tx" SG_ 75 VedsRw1mBelt_D_Ltchd 1;
BA_ "U_P702_MY2021_Tx" SG_ 75 VedsRw1mBelt_D_Ltchd 1;
BA_ "U_CX727_MY2021_Tx" SG_ 75 VedsRw1mBelt_D_Ltchd 1;
BA_ "GenSigSendType" SG_ 75 VedsRw1mBelt_D_Ltchd 3;
BA_ "U_CD764_MY2022_Tx" SG_ 75 VedsRw2pRib_D_Ltchd 1;
BA_ "U_U55X_MY2022_Tx" SG_ 75 VedsRw2pRib_D_Ltchd 1;
BA_ "U_CD542_MY2021_Tx" SG_ 75 VedsRw2pRib_D_Ltchd 1;
BA_ "U_T6_MCA_MY2020_Tx" SG_ 75 VedsRw2pRib_D_Ltchd 1;
BA_ "U_P702_MY2021_Tx" SG_ 75 VedsRw2pRib_D_Ltchd 1;
BA_ "U_CX727_MY2021_Tx" SG_ 75 VedsRw2pRib_D_Ltchd 1;
BA_ "GenSigSendType" SG_ 75 VedsRw2pRib_D_Ltchd 3;
BA_ "U_CD764_MY2022_Tx" SG_ 75 VedsRw2dRib_D_Ltchd 1;
BA_ "U_U55X_MY2022_Tx" SG_ 75 VedsRw2dRib_D_Ltchd 1;
BA_ "U_CD542_MY2021_Tx" SG_ 75 VedsRw2dRib_D_Ltchd 1;
BA_ "U_T6_MCA_MY2020_Tx" SG_ 75 VedsRw2dRib_D_Ltchd 1;
BA_ "U_P702_MY2021_Tx" SG_ 75 VedsRw2dRib_D_Ltchd 1;
BA_ "U_CX727_MY2021_Tx" SG_ 75 VedsRw2dRib_D_Ltchd 1;
BA_ "GenSigSendType" SG_ 75 VedsRw2dRib_D_Ltchd 3;
BA_ "U_CD764_MY2022_Tx" SG_ 75 VedsRw3pBckl_D_Ltchd 1;
BA_ "U_U55X_MY2022_Tx" SG_ 75 VedsRw3pBckl_D_Ltchd 1;
BA_ "U_CD542_MY2021_Tx" SG_ 75 VedsRw3pBckl_D_Ltchd 1;
BA_ "U_T6_MCA_MY2020_Tx" SG_ 75 VedsRw3pBckl_D_Ltchd 1;
BA_ "U_P702_MY2021_Tx" SG_ 75 VedsRw3pBckl_D_Ltchd 1;
BA_ "U_CX727_MY2021_Tx" SG_ 75 VedsRw3pBckl_D_Ltchd 1;
BA_ "GenSigSendType" SG_ 75 VedsRw3pBckl_D_Ltchd 3;
BA_ "U_CD764_MY2022_Tx" SG_ 75 VedsRw3mBckl_D_Ltchd 1;
BA_ "U_U55X_MY2022_Tx" SG_ 75 VedsRw3mBckl_D_Ltchd 1;
BA_ "U_CD542_MY2021_Tx" SG_ 75 VedsRw3mBckl_D_Ltchd 1;
BA_ "U_T6_MCA_MY2020_Tx" SG_ 75 VedsRw3mBckl_D_Ltchd 1;
BA_ "U_P702_MY2021_Tx" SG_ 75 VedsRw3mBckl_D_Ltchd 1;
BA_ "U_CX727_MY2021_Tx" SG_ 75 VedsRw3mBckl_D_Ltchd 1;
BA_ "GenSigSendType" SG_ 75 VedsRw3mBckl_D_Ltchd 3;
BA_ "U_CD764_MY2022_Tx" SG_ 75 VedsRw3dBckl_D_Ltchd 1;
BA_ "U_U55X_MY2022_Tx" SG_ 75 VedsRw3dBckl_D_Ltchd 1;
BA_ "U_CD542_MY2021_Tx" SG_ 75 VedsRw3dBckl_D_Ltchd 1;
BA_ "U_T6_MCA_MY2020_Tx" SG_ 75 VedsRw3dBckl_D_Ltchd 1;
BA_ "U_P702_MY2021_Tx" SG_ 75 VedsRw3dBckl_D_Ltchd 1;
BA_ "U_CX727_MY2021_Tx" SG_ 75 VedsRw3dBckl_D_Ltchd 1;
BA_ "GenSigSendType" SG_ 75 VedsRw3dBckl_D_Ltchd 3;
BA_ "U_CD764_MY2022_Tx" SG_ 75 VedsRw2pBckl_D_Ltchd 1;
BA_ "U_U55X_MY2022_Tx" SG_ 75 VedsRw2pBckl_D_Ltchd 1;
BA_ "U_CD542_MY2021_Tx" SG_ 75 VedsRw2pBckl_D_Ltchd 1;
BA_ "U_T6_MCA_MY2020_Tx" SG_ 75 VedsRw2pBckl_D_Ltchd 1;
BA_ "U_P702_MY2021_Tx" SG_ 75 VedsRw2pBckl_D_Ltchd 1;
BA_ "U_CX727_MY2021_Tx" SG_ 75 VedsRw2pBckl_D_Ltchd 1;
BA_ "GenSigSendType" SG_ 75 VedsRw2pBckl_D_Ltchd 3;
BA_ "U_CD764_MY2022_Tx" SG_ 75 VedsRw2mBckl_D_Ltchd 1;
BA_ "U_U55X_MY2022_Tx" SG_ 75 VedsRw2mBckl_D_Ltchd 1;
BA_ "U_CD542_MY2021_Tx" SG_ 75 VedsRw2mBckl_D_Ltchd 1;
BA_ "U_T6_MCA_MY2020_Tx" SG_ 75 VedsRw2mBckl_D_Ltchd 1;
BA_ "U_P702_MY2021_Tx" SG_ 75 VedsRw2mBckl_D_Ltchd 1;
BA_ "U_CX727_MY2021_Tx" SG_ 75 VedsRw2mBckl_D_Ltchd 1;
BA_ "GenSigSendType" SG_ 75 VedsRw2mBckl_D_Ltchd 3;
BA_ "U_CD764_MY2022_Tx" SG_ 75 VedsRw2dBckl_D_Ltchd 1;
BA_ "U_U55X_MY2022_Tx" SG_ 75 VedsRw2dBckl_D_Ltchd 1;
BA_ "U_CD542_MY2021_Tx" SG_ 75 VedsRw2dBckl_D_Ltchd 1;
BA_ "U_T6_MCA_MY2020_Tx" SG_ 75 VedsRw2dBckl_D_Ltchd 1;
BA_ "U_P702_MY2021_Tx" SG_ 75 VedsRw2dBckl_D_Ltchd 1;
BA_ "U_CX727_MY2021_Tx" SG_ 75 VedsRw2dBckl_D_Ltchd 1;
BA_ "GenSigSendType" SG_ 75 VedsRw2dBckl_D_Ltchd 3;
BA_ "U_CD764_MY2022_Tx" SG_ 75 VedsRw1PasChld_D_Ltchd 1;
BA_ "U_U55X_MY2022_Tx" SG_ 75 VedsRw1PasChld_D_Ltchd 1;
BA_ "U_CD542_MY2021_Tx" SG_ 75 VedsRw1PasChld_D_Ltchd 1;
BA_ "U_T6_MCA_MY2020_Tx" SG_ 75 VedsRw1PasChld_D_Ltchd 1;
BA_ "U_P702_MY2021_Tx" SG_ 75 VedsRw1PasChld_D_Ltchd 1;
BA_ "U_CX727_MY2021_Tx" SG_ 75 VedsRw1PasChld_D_Ltchd 1;
BA_ "GenSigSendType" SG_ 75 VedsRw1PasChld_D_Ltchd 3;
BA_ "U_CD764_MY2022_Tx" SG_ 75 VedsRw1PasBckl_D_Ltchd 1;
BA_ "U_U55X_MY2022_Tx" SG_ 75 VedsRw1PasBckl_D_Ltchd 1;
BA_ "U_CD542_MY2021_Tx" SG_ 75 VedsRw1PasBckl_D_Ltchd 1;
BA_ "U_T6_MCA_MY2020_Tx" SG_ 75 VedsRw1PasBckl_D_Ltchd 1;
BA_ "U_P702_MY2021_Tx" SG_ 75 VedsRw1PasBckl_D_Ltchd 1;
BA_ "U_CX727_MY2021_Tx" SG_ 75 VedsRw1PasBckl_D_Ltchd 1;
BA_ "GenSigSendType" SG_ 75 VedsRw1PasBckl_D_Ltchd 3;
BA_ "U_CD764_MY2022_Tx" SG_ 75 VedsRw1DrvBckl_D_Ltchd 1;
BA_ "U_U55X_MY2022_Tx" SG_ 75 VedsRw1DrvBckl_D_Ltchd 1;
BA_ "U_CD542_MY2021_Tx" SG_ 75 VedsRw1DrvBckl_D_Ltchd 1;
BA_ "U_T6_MCA_MY2020_Tx" SG_ 75 VedsRw1DrvBckl_D_Ltchd 1;
BA_ "U_P702_MY2021_Tx" SG_ 75 VedsRw1DrvBckl_D_Ltchd 1;
BA_ "U_CX727_MY2021_Tx" SG_ 75 VedsRw1DrvBckl_D_Ltchd 1;
BA_ "GenSigSendType" SG_ 75 VedsRw1DrvBckl_D_Ltchd 3;
BA_ "U_CD764_MY2022_Tx" SG_ 74 VedsPasSideBag_D_Ltchd 1;
BA_ "U_U55X_MY2022_Tx" SG_ 74 VedsPasSideBag_D_Ltchd 1;
BA_ "U_CD542_MY2021_Tx" SG_ 74 VedsPasSideBag_D_Ltchd 1;
BA_ "U_T6_MCA_MY2020_Tx" SG_ 74 VedsPasSideBag_D_Ltchd 1;
BA_ "U_P702_MY2021_Tx" SG_ 74 VedsPasSideBag_D_Ltchd 1;
BA_ "U_CX727_MY2021_Tx" SG_ 74 VedsPasSideBag_D_Ltchd 1;
BA_ "GenSigSendType" SG_ 74 VedsPasSideBag_D_Ltchd 3;
BA_ "U_CD764_MY2022_Tx" SG_ 74 VedsPasCrtnBag_D_Ltchd 1;
BA_ "U_U55X_MY2022_Tx" SG_ 74 VedsPasCrtnBag_D_Ltchd 1;
BA_ "U_CD542_MY2021_Tx" SG_ 74 VedsPasCrtnBag_D_Ltchd 1;
BA_ "U_T6_MCA_MY2020_Tx" SG_ 74 VedsPasCrtnBag_D_Ltchd 1;
BA_ "U_P702_MY2021_Tx" SG_ 74 VedsPasCrtnBag_D_Ltchd 1;
BA_ "U_CX727_MY2021_Tx" SG_ 74 VedsPasCrtnBag_D_Ltchd 1;
BA_ "GenSigSendType" SG_ 74 VedsPasCrtnBag_D_Ltchd 3;
BA_ "U_CD764_MY2022_Tx" SG_ 74 VedsPasBelt_D_Ltchd 1;
BA_ "U_U55X_MY2022_Tx" SG_ 74 VedsPasBelt_D_Ltchd 1;
BA_ "U_CD542_MY2021_Tx" SG_ 74 VedsPasBelt_D_Ltchd 1;
BA_ "U_T6_MCA_MY2020_Tx" SG_ 74 VedsPasBelt_D_Ltchd 1;
BA_ "U_P702_MY2021_Tx" SG_ 74 VedsPasBelt_D_Ltchd 1;
BA_ "U_CX727_MY2021_Tx" SG_ 74 VedsPasBelt_D_Ltchd 1;
BA_ "GenSigSendType" SG_ 74 VedsPasBelt_D_Ltchd 3;
BA_ "U_CD764_MY2022_Tx" SG_ 74 VedsPasBag_D_Ltchd 1;
BA_ "U_U55X_MY2022_Tx" SG_ 74 VedsPasBag_D_Ltchd 1;
BA_ "U_CD542_MY2021_Tx" SG_ 74 VedsPasBag_D_Ltchd 1;
BA_ "U_T6_MCA_MY2020_Tx" SG_ 74 VedsPasBag_D_Ltchd 1;
BA_ "U_P702_MY2021_Tx" SG_ 74 VedsPasBag_D_Ltchd 1;
BA_ "U_CX727_MY2021_Tx" SG_ 74 VedsPasBag_D_Ltchd 1;
BA_ "GenSigSendType" SG_ 74 VedsPasBag_D_Ltchd 3;
BA_ "U_CD764_MY2022_Tx" SG_ 74 VedsMultiEvnt_D_Ltchd 1;
BA_ "U_U55X_MY2022_Tx" SG_ 74 VedsMultiEvnt_D_Ltchd 1;
BA_ "U_CD542_MY2021_Tx" SG_ 74 VedsMultiEvnt_D_Ltchd 1;
BA_ "U_T6_MCA_MY2020_Tx" SG_ 74 VedsMultiEvnt_D_Ltchd 1;
BA_ "U_P702_MY2021_Tx" SG_ 74 VedsMultiEvnt_D_Ltchd 1;
BA_ "U_CX727_MY2021_Tx" SG_ 74 VedsMultiEvnt_D_Ltchd 1;
BA_ "GenSigSendType" SG_ 74 VedsMultiEvnt_D_Ltchd 3;
BA_ "U_CD764_MY2022_Tx" SG_ 74 VedsMaxDeltaV_D_Ltchd 1;
BA_ "U_U55X_MY2022_Tx" SG_ 74 VedsMaxDeltaV_D_Ltchd 1;
BA_ "U_CD542_MY2021_Tx" SG_ 74 VedsMaxDeltaV_D_Ltchd 1;
BA_ "U_T6_MCA_MY2020_Tx" SG_ 74 VedsMaxDeltaV_D_Ltchd 1;
BA_ "U_P702_MY2021_Tx" SG_ 74 VedsMaxDeltaV_D_Ltchd 1;
BA_ "U_CX727_MY2021_Tx" SG_ 74 VedsMaxDeltaV_D_Ltchd 1;
BA_ "GenSigSendType" SG_ 74 VedsMaxDeltaV_D_Ltchd 3;
BA_ "U_CD764_MY2022_Tx" SG_ 74 VedsDrvKneeBag_D_Ltchd 1;
BA_ "U_U55X_MY2022_Tx" SG_ 74 VedsDrvKneeBag_D_Ltchd 1;
BA_ "U_CD542_MY2021_Tx" SG_ 74 VedsDrvKneeBag_D_Ltchd 1;
BA_ "U_T6_MCA_MY2020_Tx" SG_ 74 VedsDrvKneeBag_D_Ltchd 1;
BA_ "U_P702_MY2021_Tx" SG_ 74 VedsDrvKneeBag_D_Ltchd 1;
BA_ "U_CX727_MY2021_Tx" SG_ 74 VedsDrvKneeBag_D_Ltchd 1;
BA_ "GenSigSendType" SG_ 74 VedsDrvKneeBag_D_Ltchd 3;
BA_ "U_CD764_MY2022_Tx" SG_ 74 VedsEvntType_D_Ltchd 1;
BA_ "U_U55X_MY2022_Tx" SG_ 74 VedsEvntType_D_Ltchd 1;
BA_ "U_CD542_MY2021_Tx" SG_ 74 VedsEvntType_D_Ltchd 1;
BA_ "U_T6_MCA_MY2020_Tx" SG_ 74 VedsEvntType_D_Ltchd 1;
BA_ "U_P702_MY2021_Tx" SG_ 74 VedsEvntType_D_Ltchd 1;
BA_ "U_CX727_MY2021_Tx" SG_ 74 VedsEvntType_D_Ltchd 1;
BA_ "GenSigSendType" SG_ 74 VedsEvntType_D_Ltchd 3;
BA_ "U_CD764_MY2022_Tx" SG_ 74 VedsEvntRoll_D_Ltchd 1;
BA_ "U_U55X_MY2022_Tx" SG_ 74 VedsEvntRoll_D_Ltchd 1;
BA_ "U_CD542_MY2021_Tx" SG_ 74 VedsEvntRoll_D_Ltchd 1;
BA_ "U_T6_MCA_MY2020_Tx" SG_ 74 VedsEvntRoll_D_Ltchd 1;
BA_ "U_P702_MY2021_Tx" SG_ 74 VedsEvntRoll_D_Ltchd 1;
BA_ "U_CX727_MY2021_Tx" SG_ 74 VedsEvntRoll_D_Ltchd 1;
BA_ "GenSigSendType" SG_ 74 VedsEvntRoll_D_Ltchd 3;
BA_ "U_CD764_MY2022_Tx" SG_ 74 VedsDrvSideBag_D_Ltchd 1;
BA_ "U_U55X_MY2022_Tx" SG_ 74 VedsDrvSideBag_D_Ltchd 1;
BA_ "U_CD542_MY2021_Tx" SG_ 74 VedsDrvSideBag_D_Ltchd 1;
BA_ "U_T6_MCA_MY2020_Tx" SG_ 74 VedsDrvSideBag_D_Ltchd 1;
BA_ "U_P702_MY2021_Tx" SG_ 74 VedsDrvSideBag_D_Ltchd 1;
BA_ "U_CX727_MY2021_Tx" SG_ 74 VedsDrvSideBag_D_Ltchd 1;
BA_ "GenSigSendType" SG_ 74 VedsDrvSideBag_D_Ltchd 3;
BA_ "U_CD764_MY2022_Tx" SG_ 74 VedsDrvCrtnBag_D_Ltchd 1;
BA_ "U_U55X_MY2022_Tx" SG_ 74 VedsDrvCrtnBag_D_Ltchd 1;
BA_ "U_CD542_MY2021_Tx" SG_ 74 VedsDrvCrtnBag_D_Ltchd 1;
BA_ "U_T6_MCA_MY2020_Tx" SG_ 74 VedsDrvCrtnBag_D_Ltchd 1;
BA_ "U_P702_MY2021_Tx" SG_ 74 VedsDrvCrtnBag_D_Ltchd 1;
BA_ "U_CX727_MY2021_Tx" SG_ 74 VedsDrvCrtnBag_D_Ltchd 1;
BA_ "GenSigSendType" SG_ 74 VedsDrvCrtnBag_D_Ltchd 3;
BA_ "U_CD764_MY2022_Tx" SG_ 74 VedsDrvBelt_D_Ltchd 1;
BA_ "U_U55X_MY2022_Tx" SG_ 74 VedsDrvBelt_D_Ltchd 1;
BA_ "U_CD542_MY2021_Tx" SG_ 74 VedsDrvBelt_D_Ltchd 1;
BA_ "U_T6_MCA_MY2020_Tx" SG_ 74 VedsDrvBelt_D_Ltchd 1;
BA_ "U_P702_MY2021_Tx" SG_ 74 VedsDrvBelt_D_Ltchd 1;
BA_ "U_CX727_MY2021_Tx" SG_ 74 VedsDrvBelt_D_Ltchd 1;
BA_ "GenSigSendType" SG_ 74 VedsDrvBelt_D_Ltchd 3;
BA_ "U_CD764_MY2022_Tx" SG_ 74 VedsDrvBag_D_Ltchd 1;
BA_ "U_U55X_MY2022_Tx" SG_ 74 VedsDrvBag_D_Ltchd 1;
BA_ "U_CD542_MY2021_Tx" SG_ 74 VedsDrvBag_D_Ltchd 1;
BA_ "U_T6_MCA_MY2020_Tx" SG_ 74 VedsDrvBag_D_Ltchd 1;
BA_ "U_P702_MY2021_Tx" SG_ 74 VedsDrvBag_D_Ltchd 1;
BA_ "U_CX727_MY2021_Tx" SG_ 74 VedsDrvBag_D_Ltchd 1;
BA_ "GenSigSendType" SG_ 74 VedsDrvBag_D_Ltchd 3;
BA_ "U_CD764_MY2022_Tx" SG_ 74 eCallNotification 1;
BA_ "U_U55X_MY2022_Tx" SG_ 74 eCallNotification 1;
BA_ "U_CD542_MY2021_Tx" SG_ 74 eCallNotification 1;
BA_ "U_T6_MCA_MY2020_Tx" SG_ 74 eCallNotification 1;
BA_ "U_P702_MY2021_Tx" SG_ 74 eCallNotification 1;
BA_ "U_CX727_MY2021_Tx" SG_ 74 eCallNotification 1;
BA_ "GenSigSendType" SG_ 74 eCallNotification 3;
BA_ "GenSigStartValue" SG_ 74 eCallNotification 1;
BA_ "GenSigStartValueInteger" SG_ 74 eCallNotification 1;
BA_ "WakeupSignal" SG_ 947 DimmingLvlEvnt_No_Actl 1;
BA_ "U_CD764_MY2022_Rx" SG_ 947 Backlit_LED_Status 1;
BA_ "U_U55X_MY2022_Rx" SG_ 947 Backlit_LED_Status 1;
BA_ "U_CD542_MY2021_Rx" SG_ 947 Backlit_LED_Status 1;
BA_ "U_T6_MCA_MY2020_Rx" SG_ 947 Backlit_LED_Status 1;
BA_ "U_P702_MY2021_Rx" SG_ 947 Backlit_LED_Status 1;
BA_ "U_CX727_MY2021_Rx" SG_ 947 Backlit_LED_Status 1;
BA_ "WakeupSignal" SG_ 947 Backlit_LED_Status 1;
BA_ "U_CD764_MY2022_Rx" SG_ 947 TurnLghtRight_D_Rq 1;
BA_ "U_U55X_MY2022_Rx" SG_ 947 TurnLghtRight_D_Rq 1;
BA_ "U_CD542_MY2021_Rx" SG_ 947 TurnLghtRight_D_Rq 1;
BA_ "U_T6_MCA_MY2020_Rx" SG_ 947 TurnLghtRight_D_Rq 1;
BA_ "U_P702_MY2021_Rx" SG_ 947 TurnLghtRight_D_Rq 1;
BA_ "U_CX727_MY2021_Rx" SG_ 947 TurnLghtRight_D_Rq 1;
BA_ "WakeupSignal" SG_ 947 TurnLghtRight_D_Rq 1;
BA_ "U_CD542_MY2021_Rx" SG_ 947 FogLghtRearOn_B_Stat 1;
BA_ "U_T6_MCA_MY2020_Rx" SG_ 947 FogLghtRearOn_B_Stat 1;
BA_ "U_P702_MY2021_Rx" SG_ 947 FogLghtRearOn_B_Stat 1;
BA_ "U_CX727_MY2021_Rx" SG_ 947 FogLghtRearOn_B_Stat 1;
BA_ "U_CD542_MY2021_Rx" SG_ 947 FogLghtFrontOn_B_Stat 1;
BA_ "U_T6_MCA_MY2020_Rx" SG_ 947 FogLghtFrontOn_B_Stat 1;
BA_ "U_P702_MY2021_Rx" SG_ 947 FogLghtFrontOn_B_Stat 1;
BA_ "U_CX727_MY2021_Rx" SG_ 947 FogLghtFrontOn_B_Stat 1;
BA_ "U_CD764_MY2022_Rx" SG_ 947 TurnLghtLeft_D_Rq 1;
BA_ "U_U55X_MY2022_Rx" SG_ 947 TurnLghtLeft_D_Rq 1;
BA_ "U_CD542_MY2021_Rx" SG_ 947 TurnLghtLeft_D_Rq 1;
BA_ "U_T6_MCA_MY2020_Rx" SG_ 947 TurnLghtLeft_D_Rq 1;
BA_ "U_P702_MY2021_Rx" SG_ 947 TurnLghtLeft_D_Rq 1;
BA_ "U_CX727_MY2021_Rx" SG_ 947 TurnLghtLeft_D_Rq 1;
BA_ "WakeupSignal" SG_ 947 TurnLghtLeft_D_Rq 1;
BA_ "U_CD764_MY2022_Rx" SG_ 947 IgnKeyType_D_Actl 1;
BA_ "U_T6_MCA_MY2020_Rx" SG_ 947 IgnKeyType_D_Actl 1;
BA_ "GenSigStartValue" SG_ 947 IgnKeyType_D_Actl 14;
BA_ "GenSigStartValueInteger" SG_ 947 IgnKeyType_D_Actl 14;
BA_ "U_CD542_MY2021_Rx" SG_ 947 Parklamp_Status 1;
BA_ "U_CX727_MY2021_Rx" SG_ 947 Parklamp_Status 1;
BA_ "U_CD764_MY2022_Rx" SG_ 947 Parklamp_Status 1;
BA_ "U_T6_MCA_MY2020_Rx" SG_ 947 Parklamp_Status 1;
BA_ "U_U55X_MY2022_Rx" SG_ 947 Parklamp_Status 1;
BA_ "U_P702_MY2021_Rx" SG_ 947 Parklamp_Status 1;
BA_ "GenSigStartValue" SG_ 947 Parklamp_Status 1;
BA_ "GenSigStartValueInteger" SG_ 947 Parklamp_Status 1;
BA_ "WakeupSignal" SG_ 947 Parklamp_Status 1;
BA_ "U_CD764_MY2022_Rx" SG_ 947 Litval 1;
BA_ "U_U55X_MY2022_Rx" SG_ 947 Litval 1;
BA_ "U_CD542_MY2021_Rx" SG_ 947 Litval 1;
BA_ "U_T6_MCA_MY2020_Rx" SG_ 947 Litval 1;
BA_ "U_P702_MY2021_Rx" SG_ 947 Litval 1;
BA_ "U_CX727_MY2021_Rx" SG_ 947 Litval 1;
BA_ "WakeupSignal" SG_ 947 Litval 1;
BA_ "U_CD764_MY2022_Rx" SG_ 947 Key_In_Ignition_Stat 1;
BA_ "U_U55X_MY2022_Rx" SG_ 947 Key_In_Ignition_Stat 1;
BA_ "U_CD542_MY2021_Rx" SG_ 947 Key_In_Ignition_Stat 1;
BA_ "U_T6_MCA_MY2020_Rx" SG_ 947 Key_In_Ignition_Stat 1;
BA_ "U_P702_MY2021_Rx" SG_ 947 Key_In_Ignition_Stat 1;
BA_ "U_CX727_MY2021_Rx" SG_ 947 Key_In_Ignition_Stat 1;
BA_ "WakeupSignal" SG_ 947 Key_In_Ignition_Stat 1;
BA_ "U_CD764_MY2022_Rx" SG_ 947 Ignition_Status 1;
BA_ "U_U55X_MY2022_Rx" SG_ 947 Ignition_Status 1;
BA_ "U_CD542_MY2021_Rx" SG_ 947 Ignition_Status 1;
BA_ "U_T6_MCA_MY2020_Rx" SG_ 947 Ignition_Status 1;
BA_ "U_P702_MY2021_Rx" SG_ 947 Ignition_Status 1;
BA_ "U_CX727_MY2021_Rx" SG_ 947 Ignition_Status 1;
BA_ "WakeupSignal" SG_ 947 Ignition_Status 1;
BA_ "U_CD764_MY2022_Rx" SG_ 947 Dimming_Lvl 1;
BA_ "U_U55X_MY2022_Rx" SG_ 947 Dimming_Lvl 1;
BA_ "U_CD542_MY2021_Rx" SG_ 947 Dimming_Lvl 1;
BA_ "U_T6_MCA_MY2020_Rx" SG_ 947 Dimming_Lvl 1;
BA_ "U_P702_MY2021_Rx" SG_ 947 Dimming_Lvl 1;
BA_ "U_CX727_MY2021_Rx" SG_ 947 Dimming_Lvl 1;
BA_ "GenSigStartValue" SG_ 947 Dimming_Lvl 12;
BA_ "GenSigStartValueInteger" SG_ 947 Dimming_Lvl 12;
BA_ "WakeupSignal" SG_ 947 Dimming_Lvl 1;
BA_ "U_CD764_MY2022_Rx" SG_ 947 Day_Night_Status 1;
BA_ "U_U55X_MY2022_Rx" SG_ 947 Day_Night_Status 1;
BA_ "U_CD542_MY2021_Rx" SG_ 947 Day_Night_Status 1;
BA_ "U_T6_MCA_MY2020_Rx" SG_ 947 Day_Night_Status 1;
BA_ "U_P702_MY2021_Rx" SG_ 947 Day_Night_Status 1;
BA_ "U_CX727_MY2021_Rx" SG_ 947 Day_Night_Status 1;
BA_ "WakeupSignal" SG_ 947 Day_Night_Status 1;
BA_ "U_CD764_MY2022_Rx" SG_ 947 Remote_Start_Status 1;
BA_ "U_CD542_MY2021_Rx" SG_ 947 Remote_Start_Status 1;
BA_ "U_P702_MY2021_Rx" SG_ 947 Remote_Start_Status 1;
BA_ "WakeupSignal" SG_ 947 Remote_Start_Status 1;
BA_ "U_CD764_MY2022_Rx" SG_ 947 DrStatTgate_B_Actl 1;
BA_ "WakeupSignal" SG_ 947 DrStatTgate_B_Actl 1;
BA_ "WakeupSignal" SG_ 947 DrStatRr_B_Actl 1;
BA_ "WakeupSignal" SG_ 947 DrStatRl_B_Actl 1;
BA_ "U_U55X_MY2022_Rx" SG_ 947 DrStatPsngr_B_Actl 1;
BA_ "U_T6_MCA_MY2020_Rx" SG_ 947 DrStatPsngr_B_Actl 1;
BA_ "U_P702_MY2021_Rx" SG_ 947 DrStatPsngr_B_Actl 1;
BA_ "U_CD764_MY2022_Rx" SG_ 947 DrStatPsngr_B_Actl 1;
BA_ "WakeupSignal" SG_ 947 DrStatPsngr_B_Actl 1;
BA_ "U_CD764_MY2022_Rx" SG_ 947 DrStatInnrTgate_B_Actl 1;
BA_ "U_U55X_MY2022_Rx" SG_ 947 DrStatInnrTgate_B_Actl 1;
BA_ "U_CD542_MY2021_Rx" SG_ 947 DrStatInnrTgate_B_Actl 1;
BA_ "U_T6_MCA_MY2020_Rx" SG_ 947 DrStatInnrTgate_B_Actl 1;
BA_ "U_P702_MY2021_Rx" SG_ 947 DrStatInnrTgate_B_Actl 1;
BA_ "U_CX727_MY2021_Rx" SG_ 947 DrStatInnrTgate_B_Actl 1;
BA_ "WakeupSignal" SG_ 947 DrStatInnrTgate_B_Actl 1;
BA_ "WakeupSignal" SG_ 947 DrStatHood_B_Actl 1;
BA_ "U_CD764_MY2022_Rx" SG_ 947 DrStatDrv_B_Actl 1;
BA_ "U_U55X_MY2022_Rx" SG_ 947 DrStatDrv_B_Actl 1;
BA_ "U_CD542_MY2021_Rx" SG_ 947 DrStatDrv_B_Actl 1;
BA_ "U_T6_MCA_MY2020_Rx" SG_ 947 DrStatDrv_B_Actl 1;
BA_ "U_P702_MY2021_Rx" SG_ 947 DrStatDrv_B_Actl 1;
BA_ "U_CX727_MY2021_Rx" SG_ 947 DrStatDrv_B_Actl 1;
BA_ "WakeupSignal" SG_ 947 DrStatDrv_B_Actl 1;
BA_ "U_CD764_MY2022_Rx" SG_ 947 PrkBrkActv_B_Actl 1;
BA_ "ContentDependant" SG_ 947 PrkBrkActv_B_Actl 1;
BA_ "WakeupSignal" SG_ 947 PrkBrkActv_B_Actl 1;
BA_ "U_CD764_MY2022_Rx" SG_ 947 LifeCycMde_D_Actl 1;
BA_ "U_U55X_MY2022_Rx" SG_ 947 LifeCycMde_D_Actl 1;
BA_ "U_CD542_MY2021_Rx" SG_ 947 LifeCycMde_D_Actl 1;
BA_ "U_T6_MCA_MY2020_Rx" SG_ 947 LifeCycMde_D_Actl 1;
BA_ "U_P702_MY2021_Rx" SG_ 947 LifeCycMde_D_Actl 1;
BA_ "U_CX727_MY2021_Rx" SG_ 947 LifeCycMde_D_Actl 1;
BA_ "GenSigStartValue" SG_ 947 CrashEvnt_D_Stat 3;
BA_ "GenSigStartValueInteger" SG_ 947 CrashEvnt_D_Stat 3;
BA_ "WakeupSignal" SG_ 947 CrashEvnt_D_Stat 1;
BA_ "U_P702_MY2021_Rx" SG_ 947 Delay_Accy 1;
BA_ "WakeupSignal" SG_ 947 Delay_Accy 1;
BA_ "U_CD764_MY2022_Tx" SG_ 131 HeadLghtHiCtrl_D_RqAhb 1;
BA_ "U_U55X_MY2022_Tx" SG_ 131 HeadLghtHiCtrl_D_RqAhb 1;
BA_ "U_CD542_MY2021_Tx" SG_ 131 HeadLghtHiCtrl_D_RqAhb 1;
BA_ "U_T6_MCA_MY2020_Tx" SG_ 131 HeadLghtHiCtrl_D_RqAhb 1;
BA_ "U_P702_MY2021_Tx" SG_ 131 HeadLghtHiCtrl_D_RqAhb 1;
BA_ "U_CX727_MY2021_Tx" SG_ 131 HeadLghtHiCtrl_D_RqAhb 1;
BA_ "U_CD542_MY2021_Rx" SG_ 131 HeadLghtHiCtrl_D_RqAhb 1;
BA_ "U_T6_MCA_MY2020_Rx" SG_ 131 HeadLghtHiCtrl_D_RqAhb 1;
BA_ "U_P702_MY2021_Rx" SG_ 131 HeadLghtHiCtrl_D_RqAhb 1;
BA_ "U_CX727_MY2021_Rx" SG_ 131 HeadLghtHiCtrl_D_RqAhb 1;
BA_ "GenSigSendType" SG_ 131 HeadLghtHiCtrl_D_RqAhb 3;
BA_ "WakeupSignal" SG_ 131 HeadLghtHiCtrl_D_RqAhb 1;
BA_ "U_CD764_MY2022_Tx" SG_ 131 AhbStat_B_Dsply 1;
BA_ "U_U55X_MY2022_Tx" SG_ 131 AhbStat_B_Dsply 1;
BA_ "U_CD542_MY2021_Tx" SG_ 131 AhbStat_B_Dsply 1;
BA_ "U_T6_MCA_MY2020_Tx" SG_ 131 AhbStat_B_Dsply 1;
BA_ "U_P702_MY2021_Tx" SG_ 131 AhbStat_B_Dsply 1;
BA_ "U_CX727_MY2021_Tx" SG_ 131 AhbStat_B_Dsply 1;
BA_ "GenSigSendType" SG_ 131 AhbStat_B_Dsply 3;
BA_ "U_CD764_MY2022_Tx" SG_ 131 WiprFrontSwtch_D_Stat 1;
BA_ "U_U55X_MY2022_Tx" SG_ 131 WiprFrontSwtch_D_Stat 1;
BA_ "U_CD542_MY2021_Tx" SG_ 131 WiprFrontSwtch_D_Stat 1;
BA_ "U_T6_MCA_MY2020_Tx" SG_ 131 WiprFrontSwtch_D_Stat 1;
BA_ "U_P702_MY2021_Tx" SG_ 131 WiprFrontSwtch_D_Stat 1;
BA_ "U_CX727_MY2021_Tx" SG_ 131 WiprFrontSwtch_D_Stat 1;
BA_ "GenSigSendType" SG_ 131 WiprFrontSwtch_D_Stat 3;
BA_ "GenSigStartValue" SG_ 131 WiprFrontSwtch_D_Stat 9;
BA_ "GenSigStartValueInteger" SG_ 131 WiprFrontSwtch_D_Stat 9;
BA_ "U_CD764_MY2022_Tx" SG_ 131 HeadLghtHiOn_B_StatAhb 1;
BA_ "U_U55X_MY2022_Tx" SG_ 131 HeadLghtHiOn_B_StatAhb 1;
BA_ "U_CD542_MY2021_Tx" SG_ 131 HeadLghtHiOn_B_StatAhb 1;
BA_ "U_T6_MCA_MY2020_Tx" SG_ 131 HeadLghtHiOn_B_StatAhb 1;
BA_ "U_P702_MY2021_Tx" SG_ 131 HeadLghtHiOn_B_StatAhb 1;
BA_ "U_CX727_MY2021_Tx" SG_ 131 HeadLghtHiOn_B_StatAhb 1;
BA_ "GenSigSendType" SG_ 131 HeadLghtHiOn_B_StatAhb 3;
BA_ "WakeupSignal" SG_ 131 HeadLghtHiOn_B_StatAhb 1;
BA_ "U_CD764_MY2022_Tx" SG_ 131 HeadLghtHiFlash_D_Actl 1;
BA_ "U_U55X_MY2022_Tx" SG_ 131 HeadLghtHiFlash_D_Actl 1;
BA_ "U_CD542_MY2021_Tx" SG_ 131 HeadLghtHiFlash_D_Actl 1;
BA_ "U_T6_MCA_MY2020_Tx" SG_ 131 HeadLghtHiFlash_D_Actl 1;
BA_ "U_P702_MY2021_Tx" SG_ 131 HeadLghtHiFlash_D_Actl 1;
BA_ "U_CX727_MY2021_Tx" SG_ 131 HeadLghtHiFlash_D_Actl 1;
BA_ "U_CD542_MY2021_Rx" SG_ 131 HeadLghtHiFlash_D_Actl 1;
BA_ "U_P702_MY2021_Rx" SG_ 131 HeadLghtHiFlash_D_Actl 1;
BA_ "GenSigSendType" SG_ 131 HeadLghtHiFlash_D_Actl 3;
BA_ "U_CD764_MY2022_Tx" SG_ 131 TjaButtnOnOffPress 1;
BA_ "U_U55X_MY2022_Tx" SG_ 131 TjaButtnOnOffPress 1;
BA_ "U_CD542_MY2021_Tx" SG_ 131 TjaButtnOnOffPress 1;
BA_ "U_T6_MCA_MY2020_Tx" SG_ 131 TjaButtnOnOffPress 1;
BA_ "U_P702_MY2021_Tx" SG_ 131 TjaButtnOnOffPress 1;
BA_ "U_CX727_MY2021_Tx" SG_ 131 TjaButtnOnOffPress 1;
BA_ "GenSigSendType" SG_ 131 TjaButtnOnOffPress 3;
BA_ "U_CD764_MY2022_Tx" SG_ 131 AccButtnGapTogglePress 1;
BA_ "U_U55X_MY2022_Tx" SG_ 131 AccButtnGapTogglePress 1;
BA_ "U_CD542_MY2021_Tx" SG_ 131 AccButtnGapTogglePress 1;
BA_ "U_T6_MCA_MY2020_Tx" SG_ 131 AccButtnGapTogglePress 1;
BA_ "U_P702_MY2021_Tx" SG_ 131 AccButtnGapTogglePress 1;
BA_ "U_CX727_MY2021_Tx" SG_ 131 AccButtnGapTogglePress 1;
BA_ "GenSigSendType" SG_ 131 AccButtnGapTogglePress 3;
BA_ "U_CD764_MY2022_Tx" SG_ 131 HeadLghtHiFlash_D_Stat 1;
BA_ "U_U55X_MY2022_Tx" SG_ 131 HeadLghtHiFlash_D_Stat 1;
BA_ "U_CD542_MY2021_Tx" SG_ 131 HeadLghtHiFlash_D_Stat 1;
BA_ "U_T6_MCA_MY2020_Tx" SG_ 131 HeadLghtHiFlash_D_Stat 1;
BA_ "U_P702_MY2021_Tx" SG_ 131 HeadLghtHiFlash_D_Stat 1;
BA_ "U_CX727_MY2021_Tx" SG_ 131 HeadLghtHiFlash_D_Stat 1;
BA_ "GenSigSendType" SG_ 131 HeadLghtHiFlash_D_Stat 3;
BA_ "WakeupSignal" SG_ 131 HeadLghtHiFlash_D_Stat 1;
BA_ "U_CD764_MY2022_Tx" SG_ 131 WiprFront_D_Stat 1;
BA_ "U_U55X_MY2022_Tx" SG_ 131 WiprFront_D_Stat 1;
BA_ "U_CD542_MY2021_Tx" SG_ 131 WiprFront_D_Stat 1;
BA_ "U_T6_MCA_MY2020_Tx" SG_ 131 WiprFront_D_Stat 1;
BA_ "U_P702_MY2021_Tx" SG_ 131 WiprFront_D_Stat 1;
BA_ "U_CX727_MY2021_Tx" SG_ 131 WiprFront_D_Stat 1;
BA_ "U_CD764_MY2022_Rx" SG_ 131 WiprFront_D_Stat 1;
BA_ "U_U55X_MY2022_Rx" SG_ 131 WiprFront_D_Stat 1;
BA_ "ECGUsedRxSignal" SG_ 131 WiprFront_D_Stat 1;
BA_ "U_CD542_MY2021_Rx" SG_ 131 WiprFront_D_Stat 1;
BA_ "U_T6_MCA_MY2020_Rx" SG_ 131 WiprFront_D_Stat 1;
BA_ "U_P702_MY2021_Rx" SG_ 131 WiprFront_D_Stat 1;
BA_ "U_CX727_MY2021_Rx" SG_ 131 WiprFront_D_Stat 1;
BA_ "GenSigSendType" SG_ 131 WiprFront_D_Stat 3;
BA_ "GenSigStartValue" SG_ 131 WiprFront_D_Stat 15;
BA_ "GenSigStartValueInteger" SG_ 131 WiprFront_D_Stat 15;
BA_ "U_CD764_MY2022_Tx" SG_ 131 TurnLghtSwtch_D_Stat 1;
BA_ "U_U55X_MY2022_Tx" SG_ 131 TurnLghtSwtch_D_Stat 1;
BA_ "U_CD542_MY2021_Tx" SG_ 131 TurnLghtSwtch_D_Stat 1;
BA_ "U_T6_MCA_MY2020_Tx" SG_ 131 TurnLghtSwtch_D_Stat 1;
BA_ "U_P702_MY2021_Tx" SG_ 131 TurnLghtSwtch_D_Stat 1;
BA_ "U_CX727_MY2021_Tx" SG_ 131 TurnLghtSwtch_D_Stat 1;
BA_ "U_U55X_MY2022_Rx" SG_ 131 TurnLghtSwtch_D_Stat 1;
BA_ "U_CD542_MY2021_Rx" SG_ 131 TurnLghtSwtch_D_Stat 1;
BA_ "U_T6_MCA_MY2020_Rx" SG_ 131 TurnLghtSwtch_D_Stat 1;
BA_ "U_P702_MY2021_Rx" SG_ 131 TurnLghtSwtch_D_Stat 1;
BA_ "U_CX727_MY2021_Rx" SG_ 131 TurnLghtSwtch_D_Stat 1;
BA_ "U_CD764_MY2022_Rx" SG_ 131 TurnLghtSwtch_D_Stat 1;
BA_ "GenSigSendType" SG_ 131 TurnLghtSwtch_D_Stat 3;
BA_ "WakeupSignal" SG_ 131 TurnLghtSwtch_D_Stat 1;
BA_ "U_CD764_MY2022_Tx" SG_ 131 LghtAmb_D_Sns 1;
BA_ "U_U55X_MY2022_Tx" SG_ 131 LghtAmb_D_Sns 1;
BA_ "U_CD542_MY2021_Tx" SG_ 131 LghtAmb_D_Sns 1;
BA_ "U_T6_MCA_MY2020_Tx" SG_ 131 LghtAmb_D_Sns 1;
BA_ "U_P702_MY2021_Tx" SG_ 131 LghtAmb_D_Sns 1;
BA_ "U_CX727_MY2021_Tx" SG_ 131 LghtAmb_D_Sns 1;
BA_ "U_CD542_MY2021_Rx" SG_ 131 LghtAmb_D_Sns 1;
BA_ "U_T6_MCA_MY2020_Rx" SG_ 131 LghtAmb_D_Sns 1;
BA_ "U_CX727_MY2021_Rx" SG_ 131 LghtAmb_D_Sns 1;
BA_ "GenSigSendType" SG_ 131 LghtAmb_D_Sns 3;
BA_ "GenSigStartValue" SG_ 131 LghtAmb_D_Sns 7;
BA_ "GenSigStartValueInteger" SG_ 131 LghtAmb_D_Sns 7;
BA_ "U_CD764_MY2022_Tx" SG_ 131 AccButtnGapIncPress 1;
BA_ "U_U55X_MY2022_Tx" SG_ 131 AccButtnGapIncPress 1;
BA_ "U_CD542_MY2021_Tx" SG_ 131 AccButtnGapIncPress 1;
BA_ "U_T6_MCA_MY2020_Tx" SG_ 131 AccButtnGapIncPress 1;
BA_ "U_P702_MY2021_Tx" SG_ 131 AccButtnGapIncPress 1;
BA_ "U_CX727_MY2021_Tx" SG_ 131 AccButtnGapIncPress 1;
BA_ "GenSigSendType" SG_ 131 AccButtnGapIncPress 3;
BA_ "U_CD764_MY2022_Tx" SG_ 131 AccButtnGapDecPress 1;
BA_ "U_U55X_MY2022_Tx" SG_ 131 AccButtnGapDecPress 1;
BA_ "U_CD542_MY2021_Tx" SG_ 131 AccButtnGapDecPress 1;
BA_ "U_T6_MCA_MY2020_Tx" SG_ 131 AccButtnGapDecPress 1;
BA_ "U_P702_MY2021_Tx" SG_ 131 AccButtnGapDecPress 1;
BA_ "U_CX727_MY2021_Tx" SG_ 131 AccButtnGapDecPress 1;
BA_ "GenSigSendType" SG_ 131 AccButtnGapDecPress 3;
BA_ "U_CD764_MY2022_Tx" SG_ 131 AslButtnOnOffPress 1;
BA_ "U_U55X_MY2022_Tx" SG_ 131 AslButtnOnOffPress 1;
BA_ "U_CD542_MY2021_Tx" SG_ 131 AslButtnOnOffPress 1;
BA_ "U_T6_MCA_MY2020_Tx" SG_ 131 AslButtnOnOffPress 1;
BA_ "U_P702_MY2021_Tx" SG_ 131 AslButtnOnOffPress 1;
BA_ "U_CX727_MY2021_Tx" SG_ 131 AslButtnOnOffPress 1;
BA_ "GenSigSendType" SG_ 131 AslButtnOnOffPress 3;
BA_ "U_CD764_MY2022_Tx" SG_ 131 AslButtnOnOffCnclPress 1;
BA_ "U_U55X_MY2022_Tx" SG_ 131 AslButtnOnOffCnclPress 1;
BA_ "U_CD542_MY2021_Tx" SG_ 131 AslButtnOnOffCnclPress 1;
BA_ "U_T6_MCA_MY2020_Tx" SG_ 131 AslButtnOnOffCnclPress 1;
BA_ "U_P702_MY2021_Tx" SG_ 131 AslButtnOnOffCnclPress 1;
BA_ "U_CX727_MY2021_Tx" SG_ 131 AslButtnOnOffCnclPress 1;
BA_ "GenSigSendType" SG_ 131 AslButtnOnOffCnclPress 3;
BA_ "U_CD764_MY2022_Tx" SG_ 131 CcButtnOnPress 1;
BA_ "U_U55X_MY2022_Tx" SG_ 131 CcButtnOnPress 1;
BA_ "U_CD542_MY2021_Tx" SG_ 131 CcButtnOnPress 1;
BA_ "U_T6_MCA_MY2020_Tx" SG_ 131 CcButtnOnPress 1;
BA_ "U_P702_MY2021_Tx" SG_ 131 CcButtnOnPress 1;
BA_ "U_CX727_MY2021_Tx" SG_ 131 CcButtnOnPress 1;
BA_ "GenSigSendType" SG_ 131 CcButtnOnPress 3;
BA_ "U_CD764_MY2022_Tx" SG_ 131 CcButtnOnOffPress 1;
BA_ "U_U55X_MY2022_Tx" SG_ 131 CcButtnOnOffPress 1;
BA_ "U_CD542_MY2021_Tx" SG_ 131 CcButtnOnOffPress 1;
BA_ "U_T6_MCA_MY2020_Tx" SG_ 131 CcButtnOnOffPress 1;
BA_ "U_P702_MY2021_Tx" SG_ 131 CcButtnOnOffPress 1;
BA_ "U_CX727_MY2021_Tx" SG_ 131 CcButtnOnOffPress 1;
BA_ "GenSigSendType" SG_ 131 CcButtnOnOffPress 3;
BA_ "U_CD764_MY2022_Tx" SG_ 131 CcButtnOnOffCnclPress 1;
BA_ "U_U55X_MY2022_Tx" SG_ 131 CcButtnOnOffCnclPress 1;
BA_ "U_CD542_MY2021_Tx" SG_ 131 CcButtnOnOffCnclPress 1;
BA_ "U_T6_MCA_MY2020_Tx" SG_ 131 CcButtnOnOffCnclPress 1;
BA_ "U_P702_MY2021_Tx" SG_ 131 CcButtnOnOffCnclPress 1;
BA_ "U_CX727_MY2021_Tx" SG_ 131 CcButtnOnOffCnclPress 1;
BA_ "GenSigSendType" SG_ 131 CcButtnOnOffCnclPress 3;
BA_ "U_CD764_MY2022_Tx" SG_ 131 CcButtnOffPress 1;
BA_ "U_U55X_MY2022_Tx" SG_ 131 CcButtnOffPress 1;
BA_ "U_CD542_MY2021_Tx" SG_ 131 CcButtnOffPress 1;
BA_ "U_T6_MCA_MY2020_Tx" SG_ 131 CcButtnOffPress 1;
BA_ "U_P702_MY2021_Tx" SG_ 131 CcButtnOffPress 1;
BA_ "U_CX727_MY2021_Tx" SG_ 131 CcButtnOffPress 1;
BA_ "GenSigSendType" SG_ 131 CcButtnOffPress 3;
BA_ "U_CD764_MY2022_Tx" SG_ 131 CcAsllButtnResPress 1;
BA_ "U_U55X_MY2022_Tx" SG_ 131 CcAsllButtnResPress 1;
BA_ "U_CD542_MY2021_Tx" SG_ 131 CcAsllButtnResPress 1;
BA_ "U_T6_MCA_MY2020_Tx" SG_ 131 CcAsllButtnResPress 1;
BA_ "U_P702_MY2021_Tx" SG_ 131 CcAsllButtnResPress 1;
BA_ "U_CX727_MY2021_Tx" SG_ 131 CcAsllButtnResPress 1;
BA_ "GenSigSendType" SG_ 131 CcAsllButtnResPress 3;
BA_ "U_CD764_MY2022_Tx" SG_ 131 CcAslButtnSetPress 1;
BA_ "U_U55X_MY2022_Tx" SG_ 131 CcAslButtnSetPress 1;
BA_ "U_CD542_MY2021_Tx" SG_ 131 CcAslButtnSetPress 1;
BA_ "U_T6_MCA_MY2020_Tx" SG_ 131 CcAslButtnSetPress 1;
BA_ "U_P702_MY2021_Tx" SG_ 131 CcAslButtnSetPress 1;
BA_ "U_CX727_MY2021_Tx" SG_ 131 CcAslButtnSetPress 1;
BA_ "GenSigSendType" SG_ 131 CcAslButtnSetPress 3;
BA_ "U_CD764_MY2022_Tx" SG_ 131 CcAslButtnSetIncPress 1;
BA_ "U_U55X_MY2022_Tx" SG_ 131 CcAslButtnSetIncPress 1;
BA_ "U_CD542_MY2021_Tx" SG_ 131 CcAslButtnSetIncPress 1;
BA_ "U_T6_MCA_MY2020_Tx" SG_ 131 CcAslButtnSetIncPress 1;
BA_ "U_P702_MY2021_Tx" SG_ 131 CcAslButtnSetIncPress 1;
BA_ "U_CX727_MY2021_Tx" SG_ 131 CcAslButtnSetIncPress 1;
BA_ "GenSigSendType" SG_ 131 CcAslButtnSetIncPress 3;
BA_ "U_CD764_MY2022_Tx" SG_ 131 CcAslButtnSetDecPress 1;
BA_ "U_U55X_MY2022_Tx" SG_ 131 CcAslButtnSetDecPress 1;
BA_ "U_CD542_MY2021_Tx" SG_ 131 CcAslButtnSetDecPress 1;
BA_ "U_T6_MCA_MY2020_Tx" SG_ 131 CcAslButtnSetDecPress 1;
BA_ "U_P702_MY2021_Tx" SG_ 131 CcAslButtnSetDecPress 1;
BA_ "U_CX727_MY2021_Tx" SG_ 131 CcAslButtnSetDecPress 1;
BA_ "GenSigSendType" SG_ 131 CcAslButtnSetDecPress 3;
BA_ "U_CD764_MY2022_Tx" SG_ 131 CcAslButtnResIncPress 1;
BA_ "U_U55X_MY2022_Tx" SG_ 131 CcAslButtnResIncPress 1;
BA_ "U_CD542_MY2021_Tx" SG_ 131 CcAslButtnResIncPress 1;
BA_ "U_T6_MCA_MY2020_Tx" SG_ 131 CcAslButtnResIncPress 1;
BA_ "U_P702_MY2021_Tx" SG_ 131 CcAslButtnResIncPress 1;
BA_ "U_CX727_MY2021_Tx" SG_ 131 CcAslButtnResIncPress 1;
BA_ "GenSigSendType" SG_ 131 CcAslButtnResIncPress 3;
BA_ "U_CD764_MY2022_Tx" SG_ 131 CcAslButtnResDecPress 1;
BA_ "U_U55X_MY2022_Tx" SG_ 131 CcAslButtnResDecPress 1;
BA_ "U_CD542_MY2021_Tx" SG_ 131 CcAslButtnResDecPress 1;
BA_ "U_T6_MCA_MY2020_Tx" SG_ 131 CcAslButtnResDecPress 1;
BA_ "U_P702_MY2021_Tx" SG_ 131 CcAslButtnResDecPress 1;
BA_ "U_CX727_MY2021_Tx" SG_ 131 CcAslButtnResDecPress 1;
BA_ "GenSigSendType" SG_ 131 CcAslButtnResDecPress 3;
BA_ "U_CD764_MY2022_Tx" SG_ 131 CcAslButtnOnPress 1;
BA_ "U_U55X_MY2022_Tx" SG_ 131 CcAslButtnOnPress 1;
BA_ "U_CD542_MY2021_Tx" SG_ 131 CcAslButtnOnPress 1;
BA_ "U_T6_MCA_MY2020_Tx" SG_ 131 CcAslButtnOnPress 1;
BA_ "U_P702_MY2021_Tx" SG_ 131 CcAslButtnOnPress 1;
BA_ "U_CX727_MY2021_Tx" SG_ 131 CcAslButtnOnPress 1;
BA_ "GenSigSendType" SG_ 131 CcAslButtnOnPress 3;
BA_ "U_CD764_MY2022_Tx" SG_ 131 CcAslButtnOnOffCncl 1;
BA_ "U_U55X_MY2022_Tx" SG_ 131 CcAslButtnOnOffCncl 1;
BA_ "U_CD542_MY2021_Tx" SG_ 131 CcAslButtnOnOffCncl 1;
BA_ "U_T6_MCA_MY2020_Tx" SG_ 131 CcAslButtnOnOffCncl 1;
BA_ "U_P702_MY2021_Tx" SG_ 131 CcAslButtnOnOffCncl 1;
BA_ "U_CX727_MY2021_Tx" SG_ 131 CcAslButtnOnOffCncl 1;
BA_ "GenSigSendType" SG_ 131 CcAslButtnOnOffCncl 3;
BA_ "U_CD764_MY2022_Tx" SG_ 131 CcAslButtnOffCnclPress 1;
BA_ "U_U55X_MY2022_Tx" SG_ 131 CcAslButtnOffCnclPress 1;
BA_ "U_CD542_MY2021_Tx" SG_ 131 CcAslButtnOffCnclPress 1;
BA_ "U_T6_MCA_MY2020_Tx" SG_ 131 CcAslButtnOffCnclPress 1;
BA_ "U_P702_MY2021_Tx" SG_ 131 CcAslButtnOffCnclPress 1;
BA_ "U_CX727_MY2021_Tx" SG_ 131 CcAslButtnOffCnclPress 1;
BA_ "GenSigSendType" SG_ 131 CcAslButtnOffCnclPress 3;
BA_ "U_CD764_MY2022_Tx" SG_ 131 CcAslButtnIndxIncPress 1;
BA_ "U_U55X_MY2022_Tx" SG_ 131 CcAslButtnIndxIncPress 1;
BA_ "U_CD542_MY2021_Tx" SG_ 131 CcAslButtnIndxIncPress 1;
BA_ "U_T6_MCA_MY2020_Tx" SG_ 131 CcAslButtnIndxIncPress 1;
BA_ "U_P702_MY2021_Tx" SG_ 131 CcAslButtnIndxIncPress 1;
BA_ "U_CX727_MY2021_Tx" SG_ 131 CcAslButtnIndxIncPress 1;
BA_ "GenSigSendType" SG_ 131 CcAslButtnIndxIncPress 3;
BA_ "U_CD764_MY2022_Tx" SG_ 131 CcAslButtnIndxDecPress 1;
BA_ "U_U55X_MY2022_Tx" SG_ 131 CcAslButtnIndxDecPress 1;
BA_ "U_CD542_MY2021_Tx" SG_ 131 CcAslButtnIndxDecPress 1;
BA_ "U_T6_MCA_MY2020_Tx" SG_ 131 CcAslButtnIndxDecPress 1;
BA_ "U_P702_MY2021_Tx" SG_ 131 CcAslButtnIndxDecPress 1;
BA_ "U_CX727_MY2021_Tx" SG_ 131 CcAslButtnIndxDecPress 1;
BA_ "GenSigSendType" SG_ 131 CcAslButtnIndxDecPress 3;
BA_ "U_CD764_MY2022_Tx" SG_ 131 CcAslButtnDeny_B_Actl 1;
BA_ "U_U55X_MY2022_Tx" SG_ 131 CcAslButtnDeny_B_Actl 1;
BA_ "U_CD542_MY2021_Tx" SG_ 131 CcAslButtnDeny_B_Actl 1;
BA_ "U_T6_MCA_MY2020_Tx" SG_ 131 CcAslButtnDeny_B_Actl 1;
BA_ "U_P702_MY2021_Tx" SG_ 131 CcAslButtnDeny_B_Actl 1;
BA_ "U_CX727_MY2021_Tx" SG_ 131 CcAslButtnDeny_B_Actl 1;
BA_ "GenSigSendType" SG_ 131 CcAslButtnDeny_B_Actl 3;
BA_ "U_CD764_MY2022_Tx" SG_ 131 CcAslButtnCnclResPress 1;
BA_ "U_U55X_MY2022_Tx" SG_ 131 CcAslButtnCnclResPress 1;
BA_ "U_CD542_MY2021_Tx" SG_ 131 CcAslButtnCnclResPress 1;
BA_ "U_T6_MCA_MY2020_Tx" SG_ 131 CcAslButtnCnclResPress 1;
BA_ "U_P702_MY2021_Tx" SG_ 131 CcAslButtnCnclResPress 1;
BA_ "U_CX727_MY2021_Tx" SG_ 131 CcAslButtnCnclResPress 1;
BA_ "GenSigSendType" SG_ 131 CcAslButtnCnclResPress 3;
BA_ "U_CD764_MY2022_Tx" SG_ 131 CcAslButtnCnclPress 1;
BA_ "U_U55X_MY2022_Tx" SG_ 131 CcAslButtnCnclPress 1;
BA_ "U_CD542_MY2021_Tx" SG_ 131 CcAslButtnCnclPress 1;
BA_ "U_T6_MCA_MY2020_Tx" SG_ 131 CcAslButtnCnclPress 1;
BA_ "U_P702_MY2021_Tx" SG_ 131 CcAslButtnCnclPress 1;
BA_ "U_CX727_MY2021_Tx" SG_ 131 CcAslButtnCnclPress 1;
BA_ "GenSigSendType" SG_ 131 CcAslButtnCnclPress 3;
BA_ "U_CD764_MY2022_Tx" SG_ 131 LaSwtchPos_D_Stat 1;
BA_ "U_U55X_MY2022_Tx" SG_ 131 LaSwtchPos_D_Stat 1;
BA_ "U_CD542_MY2021_Tx" SG_ 131 LaSwtchPos_D_Stat 1;
BA_ "U_T6_MCA_MY2020_Tx" SG_ 131 LaSwtchPos_D_Stat 1;
BA_ "U_P702_MY2021_Tx" SG_ 131 LaSwtchPos_D_Stat 1;
BA_ "U_CX727_MY2021_Tx" SG_ 131 LaSwtchPos_D_Stat 1;
BA_ "GenSigSendType" SG_ 131 LaSwtchPos_D_Stat 3;
BA_ "U_CD764_MY2022_Rx" SG_ 992 MsgCntrPersIndex_D_Rq 1;
BA_ "U_U55X_MY2022_Rx" SG_ 992 MsgCntrPersIndex_D_Rq 1;
BA_ "U_CD542_MY2021_Rx" SG_ 992 MsgCntrPersIndex_D_Rq 1;
BA_ "U_T6_MCA_MY2020_Rx" SG_ 992 MsgCntrPersIndex_D_Rq 1;
BA_ "U_P702_MY2021_Rx" SG_ 992 MsgCntrPersIndex_D_Rq 1;
BA_ "U_CX727_MY2021_Rx" SG_ 992 MsgCntrPersIndex_D_Rq 1;
BA_ "GenSigStartValue" SG_ 992 MsgCntrPersIndex_D_Rq 4;
BA_ "GenSigStartValueInteger" SG_ 992 MsgCntrPersIndex_D_Rq 4;
BA_ "U_CD764_MY2022_Rx" SG_ 992 MsgCntrFeatConfigRq 1;
BA_ "U_U55X_MY2022_Rx" SG_ 992 MsgCntrFeatConfigRq 1;
BA_ "U_CD542_MY2021_Rx" SG_ 992 MsgCntrFeatConfigRq 1;
BA_ "U_T6_MCA_MY2020_Rx" SG_ 992 MsgCntrFeatConfigRq 1;
BA_ "U_P702_MY2021_Rx" SG_ 992 MsgCntrFeatConfigRq 1;
BA_ "U_CX727_MY2021_Rx" SG_ 992 MsgCntrFeatConfigRq 1;
BA_ "U_CD764_MY2022_Rx" SG_ 992 MsgCntrFeatNoRq 1;
BA_ "U_U55X_MY2022_Rx" SG_ 992 MsgCntrFeatNoRq 1;
BA_ "U_CD542_MY2021_Rx" SG_ 992 MsgCntrFeatNoRq 1;
BA_ "U_T6_MCA_MY2020_Rx" SG_ 992 MsgCntrFeatNoRq 1;
BA_ "U_P702_MY2021_Rx" SG_ 992 MsgCntrFeatNoRq 1;
BA_ "U_CX727_MY2021_Rx" SG_ 992 MsgCntrFeatNoRq 1;
BA_ "U_CD764_MY2022_Rx" SG_ 992 MsgCntrDsplyOp_D_Rq 1;
BA_ "U_U55X_MY2022_Rx" SG_ 992 MsgCntrDsplyOp_D_Rq 1;
BA_ "U_CD542_MY2021_Rx" SG_ 992 MsgCntrDsplyOp_D_Rq 1;
BA_ "U_T6_MCA_MY2020_Rx" SG_ 992 MsgCntrDsplyOp_D_Rq 1;
BA_ "U_P702_MY2021_Rx" SG_ 992 MsgCntrDsplyOp_D_Rq 1;
BA_ "U_CX727_MY2021_Rx" SG_ 992 MsgCntrDsplyOp_D_Rq 1;
BA_ "GenSigStartValueInteger" SG_ 970 LaRefAng_No_Req 2048;
BA_ "GenSigStartValueInteger" SG_ 970 LaCurvature_No_Calc 2048;
BA_ "GenSigSendType" SG_ 129 SelDrvMdeSwtch4_D_Stat4 3;
BA_ "GenSigSendType" SG_ 129 EngExhMdeQuiet_B_RqDrv2 3;
BA_ "U_P702_MY2021_Tx" SG_ 129 PoliceAux4Swtch_B_Stat 1;
BA_ "GenSigSendType" SG_ 129 PoliceAux4Swtch_B_Stat 3;
BA_ "U_P702_MY2021_Tx" SG_ 129 PoliceAux3Swtch_B_Stat 1;
BA_ "GenSigSendType" SG_ 129 PoliceAux3Swtch_B_Stat 3;
BA_ "U_P702_MY2021_Tx" SG_ 129 PoliceAux2Swtch_B_Stat 1;
BA_ "GenSigSendType" SG_ 129 PoliceAux2Swtch_B_Stat 3;
BA_ "U_P702_MY2021_Tx" SG_ 129 PoliceAux1Swtch_B_Stat 1;
BA_ "GenSigSendType" SG_ 129 PoliceAux1Swtch_B_Stat 3;
BA_ "U_CD764_MY2022_Tx" SG_ 129 SteWhlSwtchHome_B_Stat 1;
BA_ "U_U55X_MY2022_Tx" SG_ 129 SteWhlSwtchHome_B_Stat 1;
BA_ "U_CD542_MY2021_Tx" SG_ 129 SteWhlSwtchHome_B_Stat 1;
BA_ "U_T6_MCA_MY2020_Tx" SG_ 129 SteWhlSwtchHome_B_Stat 1;
BA_ "GenSigSendType" SG_ 129 SteWhlSwtchHome_B_Stat 3;
BA_ "U_CD764_MY2022_Tx" SG_ 129 SteWhlSwtchInfo_B_Stat 1;
BA_ "U_U55X_MY2022_Tx" SG_ 129 SteWhlSwtchInfo_B_Stat 1;
BA_ "U_CD542_MY2021_Tx" SG_ 129 SteWhlSwtchInfo_B_Stat 1;
BA_ "U_T6_MCA_MY2020_Tx" SG_ 129 SteWhlSwtchInfo_B_Stat 1;
BA_ "GenSigSendType" SG_ 129 SteWhlSwtchInfo_B_Stat 3;
BA_ "GenSigSendType" SG_ 129 SelDrvMdeSwtch_D_Stat4 3;
BA_ "GenSigSendType" SG_ 129 SelDrvMdeSwtch3_D_Stat4 3;
BA_ "ContentDependant" SG_ 129 SelDrvMdeSwtch3_D_Stat4 1;
BA_ "GenSigSendType" SG_ 129 SelDrvMdeSwtch2_D_Stat4 3;
BA_ "U_CD764_MY2022_Rx" SG_ 129 SelDrvMdeSwtch1_D_Stat4 1;
BA_ "U_CD542_MY2021_Rx" SG_ 129 SelDrvMdeSwtch1_D_Stat4 1;
BA_ "ECGUsedRxSignal" SG_ 129 SelDrvMdeSwtch1_D_Stat4 1;
BA_ "GenSigSendType" SG_ 129 SelDrvMdeSwtch1_D_Stat4 3;
BA_ "U_CD764_MY2022_Tx" SG_ 129 SteWhlSwtchView_B_Stat 1;
BA_ "U_U55X_MY2022_Tx" SG_ 129 SteWhlSwtchView_B_Stat 1;
BA_ "U_CD542_MY2021_Tx" SG_ 129 SteWhlSwtchView_B_Stat 1;
BA_ "U_T6_MCA_MY2020_Tx" SG_ 129 SteWhlSwtchView_B_Stat 1;
BA_ "U_P702_MY2021_Tx" SG_ 129 SteWhlSwtchView_B_Stat 1;
BA_ "U_CX727_MY2021_Tx" SG_ 129 SteWhlSwtchView_B_Stat 1;
BA_ "GenSigSendType" SG_ 129 SteWhlSwtchView_B_Stat 3;
BA_ "WakeupSignal" SG_ 129 SteWhlSwtchView_B_Stat 1;
BA_ "U_CD764_MY2022_Tx" SG_ 129 SteWhlSwtchSet_B_Stat 1;
BA_ "U_U55X_MY2022_Tx" SG_ 129 SteWhlSwtchSet_B_Stat 1;
BA_ "U_CD542_MY2021_Tx" SG_ 129 SteWhlSwtchSet_B_Stat 1;
BA_ "U_T6_MCA_MY2020_Tx" SG_ 129 SteWhlSwtchSet_B_Stat 1;
BA_ "U_P702_MY2021_Tx" SG_ 129 SteWhlSwtchSet_B_Stat 1;
BA_ "U_CX727_MY2021_Tx" SG_ 129 SteWhlSwtchSet_B_Stat 1;
BA_ "GenSigSendType" SG_ 129 SteWhlSwtchSet_B_Stat 3;
BA_ "WakeupSignal" SG_ 129 SteWhlSwtchSet_B_Stat 1;
BA_ "U_CD764_MY2022_Tx" SG_ 129 SteWhlSwtchPhon_B_Stat 1;
BA_ "U_U55X_MY2022_Tx" SG_ 129 SteWhlSwtchPhon_B_Stat 1;
BA_ "U_CD542_MY2021_Tx" SG_ 129 SteWhlSwtchPhon_B_Stat 1;
BA_ "U_T6_MCA_MY2020_Tx" SG_ 129 SteWhlSwtchPhon_B_Stat 1;
BA_ "U_P702_MY2021_Tx" SG_ 129 SteWhlSwtchPhon_B_Stat 1;
BA_ "U_CX727_MY2021_Tx" SG_ 129 SteWhlSwtchPhon_B_Stat 1;
BA_ "GenSigSendType" SG_ 129 SteWhlSwtchPhon_B_Stat 3;
BA_ "WakeupSignal" SG_ 129 SteWhlSwtchPhon_B_Stat 1;
BA_ "U_CD764_MY2022_Tx" SG_ 129 SteWhlSwtchNav_B_Stat 1;
BA_ "U_U55X_MY2022_Tx" SG_ 129 SteWhlSwtchNav_B_Stat 1;
BA_ "U_CD542_MY2021_Tx" SG_ 129 SteWhlSwtchNav_B_Stat 1;
BA_ "U_T6_MCA_MY2020_Tx" SG_ 129 SteWhlSwtchNav_B_Stat 1;
BA_ "U_P702_MY2021_Tx" SG_ 129 SteWhlSwtchNav_B_Stat 1;
BA_ "U_CX727_MY2021_Tx" SG_ 129 SteWhlSwtchNav_B_Stat 1;
BA_ "GenSigSendType" SG_ 129 SteWhlSwtchNav_B_Stat 3;
BA_ "WakeupSignal" SG_ 129 SteWhlSwtchNav_B_Stat 1;
BA_ "U_CD764_MY2022_Tx" SG_ 129 SteWhlSwtchMed_B_Stat 1;
BA_ "U_U55X_MY2022_Tx" SG_ 129 SteWhlSwtchMed_B_Stat 1;
BA_ "U_CD542_MY2021_Tx" SG_ 129 SteWhlSwtchMed_B_Stat 1;
BA_ "U_T6_MCA_MY2020_Tx" SG_ 129 SteWhlSwtchMed_B_Stat 1;
BA_ "U_P702_MY2021_Tx" SG_ 129 SteWhlSwtchMed_B_Stat 1;
BA_ "U_CX727_MY2021_Tx" SG_ 129 SteWhlSwtchMed_B_Stat 1;
BA_ "GenSigSendType" SG_ 129 SteWhlSwtchMed_B_Stat 3;
BA_ "WakeupSignal" SG_ 129 SteWhlSwtchMed_B_Stat 1;
BA_ "U_CD764_MY2022_Tx" SG_ 129 SteWhlSwtchIod_B_Stat 1;
BA_ "U_U55X_MY2022_Tx" SG_ 129 SteWhlSwtchIod_B_Stat 1;
BA_ "U_CD542_MY2021_Tx" SG_ 129 SteWhlSwtchIod_B_Stat 1;
BA_ "U_T6_MCA_MY2020_Tx" SG_ 129 SteWhlSwtchIod_B_Stat 1;
BA_ "U_P702_MY2021_Tx" SG_ 129 SteWhlSwtchIod_B_Stat 1;
BA_ "U_CX727_MY2021_Tx" SG_ 129 SteWhlSwtchIod_B_Stat 1;
BA_ "GenSigSendType" SG_ 129 SteWhlSwtchIod_B_Stat 3;
BA_ "WakeupSignal" SG_ 129 SteWhlSwtchIod_B_Stat 1;
BA_ "U_CD764_MY2022_Tx" SG_ 129 SteWhlSwtchHud_B_Stat 1;
BA_ "U_U55X_MY2022_Tx" SG_ 129 SteWhlSwtchHud_B_Stat 1;
BA_ "U_CD542_MY2021_Tx" SG_ 129 SteWhlSwtchHud_B_Stat 1;
BA_ "U_T6_MCA_MY2020_Tx" SG_ 129 SteWhlSwtchHud_B_Stat 1;
BA_ "U_P702_MY2021_Tx" SG_ 129 SteWhlSwtchHud_B_Stat 1;
BA_ "U_CX727_MY2021_Tx" SG_ 129 SteWhlSwtchHud_B_Stat 1;
BA_ "GenSigSendType" SG_ 129 SteWhlSwtchHud_B_Stat 3;
BA_ "WakeupSignal" SG_ 129 SteWhlSwtchHud_B_Stat 1;
BA_ "U_CD764_MY2022_Tx" SG_ 129 SteWhlSwtchBack_B_Stat 1;
BA_ "U_U55X_MY2022_Tx" SG_ 129 SteWhlSwtchBack_B_Stat 1;
BA_ "U_CD542_MY2021_Tx" SG_ 129 SteWhlSwtchBack_B_Stat 1;
BA_ "U_T6_MCA_MY2020_Tx" SG_ 129 SteWhlSwtchBack_B_Stat 1;
BA_ "U_P702_MY2021_Tx" SG_ 129 SteWhlSwtchBack_B_Stat 1;
BA_ "U_CX727_MY2021_Tx" SG_ 129 SteWhlSwtchBack_B_Stat 1;
BA_ "GenSigSendType" SG_ 129 SteWhlSwtchBack_B_Stat 3;
BA_ "WakeupSignal" SG_ 129 SteWhlSwtchBack_B_Stat 1;
BA_ "U_CD764_MY2022_Tx" SG_ 129 SteWhlSwtchMenu_B_Stat 1;
BA_ "U_U55X_MY2022_Tx" SG_ 129 SteWhlSwtchMenu_B_Stat 1;
BA_ "U_CD542_MY2021_Tx" SG_ 129 SteWhlSwtchMenu_B_Stat 1;
BA_ "U_T6_MCA_MY2020_Tx" SG_ 129 SteWhlSwtchMenu_B_Stat 1;
BA_ "U_P702_MY2021_Tx" SG_ 129 SteWhlSwtchMenu_B_Stat 1;
BA_ "U_CX727_MY2021_Tx" SG_ 129 SteWhlSwtchMenu_B_Stat 1;
BA_ "GenSigSendType" SG_ 129 SteWhlSwtchMenu_B_Stat 3;
BA_ "WakeupSignal" SG_ 129 SteWhlSwtchMenu_B_Stat 1;
BA_ "U_CD764_MY2022_Tx" SG_ 129 SteEffortInc_B_RqDrv 1;
BA_ "U_U55X_MY2022_Tx" SG_ 129 SteEffortInc_B_RqDrv 1;
BA_ "U_CD542_MY2021_Tx" SG_ 129 SteEffortInc_B_RqDrv 1;
BA_ "U_T6_MCA_MY2020_Tx" SG_ 129 SteEffortInc_B_RqDrv 1;
BA_ "U_P702_MY2021_Tx" SG_ 129 SteEffortInc_B_RqDrv 1;
BA_ "U_CX727_MY2021_Tx" SG_ 129 SteEffortInc_B_RqDrv 1;
BA_ "GenSigSendType" SG_ 129 SteEffortInc_B_RqDrv 3;
BA_ "U_CD764_MY2022_Tx" SG_ 129 SelDrvMdeInc_B_RqDrv 1;
BA_ "U_U55X_MY2022_Tx" SG_ 129 SelDrvMdeInc_B_RqDrv 1;
BA_ "U_CD542_MY2021_Tx" SG_ 129 SelDrvMdeInc_B_RqDrv 1;
BA_ "U_T6_MCA_MY2020_Tx" SG_ 129 SelDrvMdeInc_B_RqDrv 1;
BA_ "U_P702_MY2021_Tx" SG_ 129 SelDrvMdeInc_B_RqDrv 1;
BA_ "U_CX727_MY2021_Tx" SG_ 129 SelDrvMdeInc_B_RqDrv 1;
BA_ "GenSigSendType" SG_ 129 SelDrvMdeInc_B_RqDrv 3;
BA_ "U_CD764_MY2022_Tx" SG_ 129 SelDrvMdeDec_B_RqDrv 1;
BA_ "U_U55X_MY2022_Tx" SG_ 129 SelDrvMdeDec_B_RqDrv 1;
BA_ "U_CD542_MY2021_Tx" SG_ 129 SelDrvMdeDec_B_RqDrv 1;
BA_ "U_T6_MCA_MY2020_Tx" SG_ 129 SelDrvMdeDec_B_RqDrv 1;
BA_ "U_P702_MY2021_Tx" SG_ 129 SelDrvMdeDec_B_RqDrv 1;
BA_ "U_CX727_MY2021_Tx" SG_ 129 SelDrvMdeDec_B_RqDrv 1;
BA_ "GenSigSendType" SG_ 129 SelDrvMdeDec_B_RqDrv 3;
BA_ "U_CD764_MY2022_Tx" SG_ 129 SuspDampInc_B_RqDrv 1;
BA_ "U_U55X_MY2022_Tx" SG_ 129 SuspDampInc_B_RqDrv 1;
BA_ "U_CD542_MY2021_Tx" SG_ 129 SuspDampInc_B_RqDrv 1;
BA_ "U_T6_MCA_MY2020_Tx" SG_ 129 SuspDampInc_B_RqDrv 1;
BA_ "U_P702_MY2021_Tx" SG_ 129 SuspDampInc_B_RqDrv 1;
BA_ "U_CX727_MY2021_Tx" SG_ 129 SuspDampInc_B_RqDrv 1;
BA_ "GenSigSendType" SG_ 129 SuspDampInc_B_RqDrv 3;
BA_ "U_CD764_MY2022_Tx" SG_ 129 SteWhlSwtchUp_B_Stat 1;
BA_ "U_U55X_MY2022_Tx" SG_ 129 SteWhlSwtchUp_B_Stat 1;
BA_ "U_CD542_MY2021_Tx" SG_ 129 SteWhlSwtchUp_B_Stat 1;
BA_ "U_T6_MCA_MY2020_Tx" SG_ 129 SteWhlSwtchUp_B_Stat 1;
BA_ "U_P702_MY2021_Tx" SG_ 129 SteWhlSwtchUp_B_Stat 1;
BA_ "U_CX727_MY2021_Tx" SG_ 129 SteWhlSwtchUp_B_Stat 1;
BA_ "GenSigSendType" SG_ 129 SteWhlSwtchUp_B_Stat 3;
BA_ "WakeupSignal" SG_ 129 SteWhlSwtchUp_B_Stat 1;
BA_ "U_CD764_MY2022_Tx" SG_ 129 SteWhlSwtchRght_B_Stat 1;
BA_ "U_U55X_MY2022_Tx" SG_ 129 SteWhlSwtchRght_B_Stat 1;
BA_ "U_CD542_MY2021_Tx" SG_ 129 SteWhlSwtchRght_B_Stat 1;
BA_ "U_T6_MCA_MY2020_Tx" SG_ 129 SteWhlSwtchRght_B_Stat 1;
BA_ "U_P702_MY2021_Tx" SG_ 129 SteWhlSwtchRght_B_Stat 1;
BA_ "U_CX727_MY2021_Tx" SG_ 129 SteWhlSwtchRght_B_Stat 1;
BA_ "GenSigSendType" SG_ 129 SteWhlSwtchRght_B_Stat 3;
BA_ "WakeupSignal" SG_ 129 SteWhlSwtchRght_B_Stat 1;
BA_ "U_CD764_MY2022_Tx" SG_ 129 SteWhlSwtchOk_B_Stat 1;
BA_ "U_U55X_MY2022_Tx" SG_ 129 SteWhlSwtchOk_B_Stat 1;
BA_ "U_CD542_MY2021_Tx" SG_ 129 SteWhlSwtchOk_B_Stat 1;
BA_ "U_T6_MCA_MY2020_Tx" SG_ 129 SteWhlSwtchOk_B_Stat 1;
BA_ "U_P702_MY2021_Tx" SG_ 129 SteWhlSwtchOk_B_Stat 1;
BA_ "U_CX727_MY2021_Tx" SG_ 129 SteWhlSwtchOk_B_Stat 1;
BA_ "GenSigSendType" SG_ 129 SteWhlSwtchOk_B_Stat 3;
BA_ "WakeupSignal" SG_ 129 SteWhlSwtchOk_B_Stat 1;
BA_ "U_CD764_MY2022_Tx" SG_ 129 SteWhlSwtchLeft_B_Stat 1;
BA_ "U_U55X_MY2022_Tx" SG_ 129 SteWhlSwtchLeft_B_Stat 1;
BA_ "U_CD542_MY2021_Tx" SG_ 129 SteWhlSwtchLeft_B_Stat 1;
BA_ "U_T6_MCA_MY2020_Tx" SG_ 129 SteWhlSwtchLeft_B_Stat 1;
BA_ "U_P702_MY2021_Tx" SG_ 129 SteWhlSwtchLeft_B_Stat 1;
BA_ "U_CX727_MY2021_Tx" SG_ 129 SteWhlSwtchLeft_B_Stat 1;
BA_ "GenSigSendType" SG_ 129 SteWhlSwtchLeft_B_Stat 3;
BA_ "WakeupSignal" SG_ 129 SteWhlSwtchLeft_B_Stat 1;
BA_ "U_CD764_MY2022_Tx" SG_ 129 SteWhlSwtchDown_B_Stat 1;
BA_ "U_U55X_MY2022_Tx" SG_ 129 SteWhlSwtchDown_B_Stat 1;
BA_ "U_CD542_MY2021_Tx" SG_ 129 SteWhlSwtchDown_B_Stat 1;
BA_ "U_T6_MCA_MY2020_Tx" SG_ 129 SteWhlSwtchDown_B_Stat 1;
BA_ "U_P702_MY2021_Tx" SG_ 129 SteWhlSwtchDown_B_Stat 1;
BA_ "U_CX727_MY2021_Tx" SG_ 129 SteWhlSwtchDown_B_Stat 1;
BA_ "GenSigSendType" SG_ 129 SteWhlSwtchDown_B_Stat 3;
BA_ "WakeupSignal" SG_ 129 SteWhlSwtchDown_B_Stat 1;
BA_ "GenSigSendType" SG_ 1833 TesterPhysicalResVDM 3;
BA_ "U_CD764_MY2022_Rx" SG_ 1109 eCallConfirmation 1;
BA_ "U_U55X_MY2022_Rx" SG_ 1109 eCallConfirmation 1;
BA_ "U_CD542_MY2021_Rx" SG_ 1109 eCallConfirmation 1;
BA_ "U_T6_MCA_MY2020_Rx" SG_ 1109 eCallConfirmation 1;
BA_ "U_P702_MY2021_Rx" SG_ 1109 eCallConfirmation 1;
BA_ "U_CX727_MY2021_Rx" SG_ 1109 eCallConfirmation 1;
BA_ "MetaData" SG_ 1046 BpedDiffLckTq_No_Cs 1;
BA_ "GenSigStartValue" SG_ 1046 HsaMde_D_Mem 1;
BA_ "GenSigStartValueInteger" SG_ 1046 HsaMde_D_Mem 1;
BA_ "GenSigStartValue" SG_ 1046 RearDiffLck_Tq2_RqMx 4094;
BA_ "GenSigStartValueInteger" SG_ 1046 RearDiffLck_Tq2_RqMx 4094;
BA_ "U_T6_MCA_MY2020_Rx" SG_ 1046 TRLR_SWAY_EVNT_IN_PROG 1;
BA_ "U_P702_MY2021_Rx" SG_ 1046 TRLR_SWAY_EVNT_IN_PROG 1;
BA_ "U_CD764_MY2022_Rx" SG_ 1046 TCMode 1;
BA_ "U_U55X_MY2022_Rx" SG_ 1046 TCMode 1;
BA_ "U_CD542_MY2021_Rx" SG_ 1046 TCMode 1;
BA_ "U_T6_MCA_MY2020_Rx" SG_ 1046 TCMode 1;
BA_ "U_P702_MY2021_Rx" SG_ 1046 TCMode 1;
BA_ "U_CX727_MY2021_Rx" SG_ 1046 TCMode 1;
BA_ "ContentDependant" SG_ 1046 TCMode 1;
BA_ "U_CD764_MY2022_Rx" SG_ 1046 DrvSlipCtlLamp_D_Rq 1;
BA_ "U_U55X_MY2022_Rx" SG_ 1046 DrvSlipCtlLamp_D_Rq 1;
BA_ "U_CD542_MY2021_Rx" SG_ 1046 DrvSlipCtlLamp_D_Rq 1;
BA_ "U_T6_MCA_MY2020_Rx" SG_ 1046 DrvSlipCtlLamp_D_Rq 1;
BA_ "U_P702_MY2021_Rx" SG_ 1046 DrvSlipCtlLamp_D_Rq 1;
BA_ "U_CX727_MY2021_Rx" SG_ 1046 DrvSlipCtlLamp_D_Rq 1;
BA_ "U_P702_MY2021_Rx" SG_ 1046 Abs_B_Falt 1;
BA_ "U_CD764_MY2022_Rx" SG_ 1046 DrvSlipCtlMde_D_Ind 1;
BA_ "U_U55X_MY2022_Rx" SG_ 1046 DrvSlipCtlMde_D_Ind 1;
BA_ "U_CD542_MY2021_Rx" SG_ 1046 DrvSlipCtlMde_D_Ind 1;
BA_ "U_T6_MCA_MY2020_Rx" SG_ 1046 DrvSlipCtlMde_D_Ind 1;
BA_ "U_P702_MY2021_Rx" SG_ 1046 DrvSlipCtlMde_D_Ind 1;
BA_ "U_CX727_MY2021_Rx" SG_ 1046 DrvSlipCtlMde_D_Ind 1;
BA_ "U_CD764_MY2022_Rx" SG_ 1046 DrvAntiLckLamp_D_Rq 1;
BA_ "U_U55X_MY2022_Rx" SG_ 1046 DrvAntiLckLamp_D_Rq 1;
BA_ "U_CD542_MY2021_Rx" SG_ 1046 DrvAntiLckLamp_D_Rq 1;
BA_ "U_T6_MCA_MY2020_Rx" SG_ 1046 DrvAntiLckLamp_D_Rq 1;
BA_ "U_P702_MY2021_Rx" SG_ 1046 DrvAntiLckLamp_D_Rq 1;
BA_ "U_CX727_MY2021_Rx" SG_ 1046 DrvAntiLckLamp_D_Rq 1;
BA_ "MetaData" SG_ 1046 BpedMove_No_Cnt 1;
BA_ "U_CD764_MY2022_Rx" SG_ 1046 StabCtlBrk_B_Avail 1;
BA_ "U_U55X_MY2022_Rx" SG_ 1046 StabCtlBrk_B_Avail 1;
BA_ "U_T6_MCA_MY2020_Rx" SG_ 1046 StabCtlBrk_B_Avail 1;
BA_ "GenSigStartValue" SG_ 1046 StabCtlBrk_B_Avail 1;
BA_ "GenSigStartValueInteger" SG_ 1046 StabCtlBrk_B_Avail 1;
BA_ "GenSigStartValue" SG_ 1046 BpedMove_D_Actl 3;
BA_ "GenSigStartValueInteger" SG_ 1046 BpedMove_D_Actl 3;
BA_ "U_CD764_MY2022_Rx" SG_ 1046 BrkLamp_B_Rq 1;
BA_ "U_U55X_MY2022_Rx" SG_ 1046 BrkLamp_B_Rq 1;
BA_ "U_CD542_MY2021_Rx" SG_ 1046 BrkLamp_B_Rq 1;
BA_ "U_T6_MCA_MY2020_Rx" SG_ 1046 BrkLamp_B_Rq 1;
BA_ "U_P702_MY2021_Rx" SG_ 1046 BrkLamp_B_Rq 1;
BA_ "U_CX727_MY2021_Rx" SG_ 1046 BrkLamp_B_Rq 1;
BA_ "ContentDependant" SG_ 534 BrkObdData_No_Actl 1;
BA_ "ContentDependant" SG_ 534 BrkObdIndex_No_Actl 1;
BA_ "U_CD764_MY2022_Rx" SG_ 534 WhlRotatRr_No_Cnt 1;
BA_ "U_T6_MCA_MY2020_Rx" SG_ 534 WhlRotatRr_No_Cnt 1;
BA_ "U_CD764_MY2022_Rx" SG_ 534 WhlDirRr_D_Actl 1;
BA_ "U_T6_MCA_MY2020_Rx" SG_ 534 WhlDirRr_D_Actl 1;
BA_ "U_CD764_MY2022_Rx" SG_ 534 WhlDirRl_D_Actl 1;
BA_ "U_T6_MCA_MY2020_Rx" SG_ 534 WhlDirRl_D_Actl 1;
BA_ "U_CD764_MY2022_Rx" SG_ 534 WhlDirFr_D_Actl 1;
BA_ "U_T6_MCA_MY2020_Rx" SG_ 534 WhlDirFr_D_Actl 1;
BA_ "U_CD764_MY2022_Rx" SG_ 534 WhlDirFl_D_Actl 1;
BA_ "U_T6_MCA_MY2020_Rx" SG_ 534 WhlDirFl_D_Actl 1;
BA_ "U_CD764_MY2022_Rx" SG_ 534 WhlRotatRl_No_Cnt 1;
BA_ "U_T6_MCA_MY2020_Rx" SG_ 534 WhlRotatRl_No_Cnt 1;
BA_ "U_CD764_MY2022_Rx" SG_ 534 WhlRotatFr_No_Cnt 1;
BA_ "U_T6_MCA_MY2020_Rx" SG_ 534 WhlRotatFr_No_Cnt 1;
BA_ "U_CD764_MY2022_Rx" SG_ 534 WhlRotatFl_No_Cnt 1;
BA_ "U_T6_MCA_MY2020_Rx" SG_ 534 WhlRotatFl_No_Cnt 1;
BA_ "ContentDependant" SG_ 1093 StopLamp_B_RqTrlrBrk 1;
BA_ "WakeupSignal" SG_ 994 Pers4OptIn_B_Stats 1;
BA_ "U_CD764_MY2022_Rx" SG_ 994 CtrStkPersIndex_D_Actl 1;
BA_ "U_U55X_MY2022_Rx" SG_ 994 CtrStkPersIndex_D_Actl 1;
BA_ "U_CD542_MY2021_Rx" SG_ 994 CtrStkPersIndex_D_Actl 1;
BA_ "U_T6_MCA_MY2020_Rx" SG_ 994 CtrStkPersIndex_D_Actl 1;
BA_ "U_P702_MY2021_Rx" SG_ 994 CtrStkPersIndex_D_Actl 1;
BA_ "U_CX727_MY2021_Rx" SG_ 994 CtrStkPersIndex_D_Actl 1;
BA_ "GenSigStartValue" SG_ 994 CtrStkPersIndex_D_Actl 4;
BA_ "GenSigStartValueInteger" SG_ 994 CtrStkPersIndex_D_Actl 4;
BA_ "U_CD764_MY2022_Rx" SG_ 994 CtrStkFeatNoActl 1;
BA_ "U_U55X_MY2022_Rx" SG_ 994 CtrStkFeatNoActl 1;
BA_ "U_CD542_MY2021_Rx" SG_ 994 CtrStkFeatNoActl 1;
BA_ "U_T6_MCA_MY2020_Rx" SG_ 994 CtrStkFeatNoActl 1;
BA_ "U_P702_MY2021_Rx" SG_ 994 CtrStkFeatNoActl 1;
BA_ "U_CX727_MY2021_Rx" SG_ 994 CtrStkFeatNoActl 1;
BA_ "U_CD764_MY2022_Rx" SG_ 994 CtrStkFeatConfigActl 1;
BA_ "U_U55X_MY2022_Rx" SG_ 994 CtrStkFeatConfigActl 1;
BA_ "U_CD542_MY2021_Rx" SG_ 994 CtrStkFeatConfigActl 1;
BA_ "U_T6_MCA_MY2020_Rx" SG_ 994 CtrStkFeatConfigActl 1;
BA_ "U_P702_MY2021_Rx" SG_ 994 CtrStkFeatConfigActl 1;
BA_ "U_CX727_MY2021_Rx" SG_ 994 CtrStkFeatConfigActl 1;
BA_ "U_CD764_MY2022_Rx" SG_ 994 CtrStkDsplyOp_D_Rq 1;
BA_ "U_U55X_MY2022_Rx" SG_ 994 CtrStkDsplyOp_D_Rq 1;
BA_ "U_CD542_MY2021_Rx" SG_ 994 CtrStkDsplyOp_D_Rq 1;
BA_ "U_T6_MCA_MY2020_Rx" SG_ 994 CtrStkDsplyOp_D_Rq 1;
BA_ "U_P702_MY2021_Rx" SG_ 994 CtrStkDsplyOp_D_Rq 1;
BA_ "U_CX727_MY2021_Rx" SG_ 994 CtrStkDsplyOp_D_Rq 1;
BA_ "WakeupSignal" SG_ 994 Pers3OptIn_B_Stats 1;
BA_ "WakeupSignal" SG_ 994 Pers2OptIn_B_Stats 1;
BA_ "WakeupSignal" SG_ 994 Pers1OptIn_B_Stats 1;
BA_ "U_CD764_MY2022_Tx" SG_ 1836 TesterPhysicalResSCCM 1;
BA_ "U_U55X_MY2022_Tx" SG_ 1836 TesterPhysicalResSCCM 1;
BA_ "U_CD542_MY2021_Tx" SG_ 1836 TesterPhysicalResSCCM 1;
BA_ "U_T6_MCA_MY2020_Tx" SG_ 1836 TesterPhysicalResSCCM 1;
BA_ "U_P702_MY2021_Tx" SG_ 1836 TesterPhysicalResSCCM 1;
BA_ "U_CX727_MY2021_Tx" SG_ 1836 TesterPhysicalResSCCM 1;
BA_ "GenSigSendType" SG_ 1836 TesterPhysicalResSCCM 3;
BA_ "GenSigSendType" SG_ 1825 TesterPhysicalReqVDM 3;
BA_ "U_CD764_MY2022_Tx" SG_ 1108 RCMSerialNoByte8 1;
BA_ "U_U55X_MY2022_Tx" SG_ 1108 RCMSerialNoByte8 1;
BA_ "U_CD542_MY2021_Tx" SG_ 1108 RCMSerialNoByte8 1;
BA_ "U_T6_MCA_MY2020_Tx" SG_ 1108 RCMSerialNoByte8 1;
BA_ "U_P702_MY2021_Tx" SG_ 1108 RCMSerialNoByte8 1;
BA_ "U_CX727_MY2021_Tx" SG_ 1108 RCMSerialNoByte8 1;
BA_ "U_U55X_MY2022_Rx" SG_ 1108 RCMSerialNoByte8 1;
BA_ "U_T6_MCA_MY2020_Rx" SG_ 1108 RCMSerialNoByte8 1;
BA_ "U_P702_MY2021_Rx" SG_ 1108 RCMSerialNoByte8 1;
BA_ "U_CX727_MY2021_Rx" SG_ 1108 RCMSerialNoByte8 1;
BA_ "U_CD764_MY2022_Tx" SG_ 1108 RCMSerialNoByte7 1;
BA_ "U_U55X_MY2022_Tx" SG_ 1108 RCMSerialNoByte7 1;
BA_ "U_CD542_MY2021_Tx" SG_ 1108 RCMSerialNoByte7 1;
BA_ "U_T6_MCA_MY2020_Tx" SG_ 1108 RCMSerialNoByte7 1;
BA_ "U_P702_MY2021_Tx" SG_ 1108 RCMSerialNoByte7 1;
BA_ "U_CX727_MY2021_Tx" SG_ 1108 RCMSerialNoByte7 1;
BA_ "U_U55X_MY2022_Rx" SG_ 1108 RCMSerialNoByte7 1;
BA_ "U_T6_MCA_MY2020_Rx" SG_ 1108 RCMSerialNoByte7 1;
BA_ "U_P702_MY2021_Rx" SG_ 1108 RCMSerialNoByte7 1;
BA_ "U_CX727_MY2021_Rx" SG_ 1108 RCMSerialNoByte7 1;
BA_ "U_CD764_MY2022_Tx" SG_ 1108 RCMSerialNoByte6 1;
BA_ "U_U55X_MY2022_Tx" SG_ 1108 RCMSerialNoByte6 1;
BA_ "U_CD542_MY2021_Tx" SG_ 1108 RCMSerialNoByte6 1;
BA_ "U_T6_MCA_MY2020_Tx" SG_ 1108 RCMSerialNoByte6 1;
BA_ "U_P702_MY2021_Tx" SG_ 1108 RCMSerialNoByte6 1;
BA_ "U_CX727_MY2021_Tx" SG_ 1108 RCMSerialNoByte6 1;
BA_ "U_U55X_MY2022_Rx" SG_ 1108 RCMSerialNoByte6 1;
BA_ "U_T6_MCA_MY2020_Rx" SG_ 1108 RCMSerialNoByte6 1;
BA_ "U_P702_MY2021_Rx" SG_ 1108 RCMSerialNoByte6 1;
BA_ "U_CX727_MY2021_Rx" SG_ 1108 RCMSerialNoByte6 1;
BA_ "U_CD764_MY2022_Tx" SG_ 1108 RCMSerialNoByte5 1;
BA_ "U_U55X_MY2022_Tx" SG_ 1108 RCMSerialNoByte5 1;
BA_ "U_CD542_MY2021_Tx" SG_ 1108 RCMSerialNoByte5 1;
BA_ "U_T6_MCA_MY2020_Tx" SG_ 1108 RCMSerialNoByte5 1;
BA_ "U_P702_MY2021_Tx" SG_ 1108 RCMSerialNoByte5 1;
BA_ "U_CX727_MY2021_Tx" SG_ 1108 RCMSerialNoByte5 1;
BA_ "U_U55X_MY2022_Rx" SG_ 1108 RCMSerialNoByte5 1;
BA_ "U_T6_MCA_MY2020_Rx" SG_ 1108 RCMSerialNoByte5 1;
BA_ "U_P702_MY2021_Rx" SG_ 1108 RCMSerialNoByte5 1;
BA_ "U_CX727_MY2021_Rx" SG_ 1108 RCMSerialNoByte5 1;
BA_ "U_CD764_MY2022_Tx" SG_ 1108 RCMSerialNoByte4 1;
BA_ "U_U55X_MY2022_Tx" SG_ 1108 RCMSerialNoByte4 1;
BA_ "U_CD542_MY2021_Tx" SG_ 1108 RCMSerialNoByte4 1;
BA_ "U_T6_MCA_MY2020_Tx" SG_ 1108 RCMSerialNoByte4 1;
BA_ "U_P702_MY2021_Tx" SG_ 1108 RCMSerialNoByte4 1;
BA_ "U_CX727_MY2021_Tx" SG_ 1108 RCMSerialNoByte4 1;
BA_ "U_U55X_MY2022_Rx" SG_ 1108 RCMSerialNoByte4 1;
BA_ "U_T6_MCA_MY2020_Rx" SG_ 1108 RCMSerialNoByte4 1;
BA_ "U_P702_MY2021_Rx" SG_ 1108 RCMSerialNoByte4 1;
BA_ "U_CX727_MY2021_Rx" SG_ 1108 RCMSerialNoByte4 1;
BA_ "U_CD764_MY2022_Tx" SG_ 1108 RCMSerialNoByte3 1;
BA_ "U_U55X_MY2022_Tx" SG_ 1108 RCMSerialNoByte3 1;
BA_ "U_CD542_MY2021_Tx" SG_ 1108 RCMSerialNoByte3 1;
BA_ "U_T6_MCA_MY2020_Tx" SG_ 1108 RCMSerialNoByte3 1;
BA_ "U_P702_MY2021_Tx" SG_ 1108 RCMSerialNoByte3 1;
BA_ "U_CX727_MY2021_Tx" SG_ 1108 RCMSerialNoByte3 1;
BA_ "U_U55X_MY2022_Rx" SG_ 1108 RCMSerialNoByte3 1;
BA_ "U_T6_MCA_MY2020_Rx" SG_ 1108 RCMSerialNoByte3 1;
BA_ "U_P702_MY2021_Rx" SG_ 1108 RCMSerialNoByte3 1;
BA_ "U_CX727_MY2021_Rx" SG_ 1108 RCMSerialNoByte3 1;
BA_ "U_CD764_MY2022_Tx" SG_ 1108 RCMSerialNoByte2 1;
BA_ "U_U55X_MY2022_Tx" SG_ 1108 RCMSerialNoByte2 1;
BA_ "U_CD542_MY2021_Tx" SG_ 1108 RCMSerialNoByte2 1;
BA_ "U_T6_MCA_MY2020_Tx" SG_ 1108 RCMSerialNoByte2 1;
BA_ "U_P702_MY2021_Tx" SG_ 1108 RCMSerialNoByte2 1;
BA_ "U_CX727_MY2021_Tx" SG_ 1108 RCMSerialNoByte2 1;
BA_ "U_U55X_MY2022_Rx" SG_ 1108 RCMSerialNoByte2 1;
BA_ "U_T6_MCA_MY2020_Rx" SG_ 1108 RCMSerialNoByte2 1;
BA_ "U_P702_MY2021_Rx" SG_ 1108 RCMSerialNoByte2 1;
BA_ "U_CX727_MY2021_Rx" SG_ 1108 RCMSerialNoByte2 1;
BA_ "U_CD764_MY2022_Tx" SG_ 1108 RCMSerialNoByte1 1;
BA_ "U_U55X_MY2022_Tx" SG_ 1108 RCMSerialNoByte1 1;
BA_ "U_CD542_MY2021_Tx" SG_ 1108 RCMSerialNoByte1 1;
BA_ "U_T6_MCA_MY2020_Tx" SG_ 1108 RCMSerialNoByte1 1;
BA_ "U_P702_MY2021_Tx" SG_ 1108 RCMSerialNoByte1 1;
BA_ "U_CX727_MY2021_Tx" SG_ 1108 RCMSerialNoByte1 1;
BA_ "U_U55X_MY2022_Rx" SG_ 1108 RCMSerialNoByte1 1;
BA_ "U_T6_MCA_MY2020_Rx" SG_ 1108 RCMSerialNoByte1 1;
BA_ "U_P702_MY2021_Rx" SG_ 1108 RCMSerialNoByte1 1;
BA_ "U_CX727_MY2021_Rx" SG_ 1108 RCMSerialNoByte1 1;
BA_ "U_U55X_MY2022_Tx" SG_ 1107 OCSSerialNoByte8 1;
BA_ "U_T6_MCA_MY2020_Tx" SG_ 1107 OCSSerialNoByte8 1;
BA_ "U_P702_MY2021_Tx" SG_ 1107 OCSSerialNoByte8 1;
BA_ "U_CX727_MY2021_Tx" SG_ 1107 OCSSerialNoByte8 1;
BA_ "U_U55X_MY2022_Rx" SG_ 1107 OCSSerialNoByte8 1;
BA_ "U_T6_MCA_MY2020_Rx" SG_ 1107 OCSSerialNoByte8 1;
BA_ "U_P702_MY2021_Rx" SG_ 1107 OCSSerialNoByte8 1;
BA_ "U_CX727_MY2021_Rx" SG_ 1107 OCSSerialNoByte8 1;
BA_ "U_U55X_MY2022_Tx" SG_ 1107 OCSSerialNoByte7 1;
BA_ "U_T6_MCA_MY2020_Tx" SG_ 1107 OCSSerialNoByte7 1;
BA_ "U_P702_MY2021_Tx" SG_ 1107 OCSSerialNoByte7 1;
BA_ "U_CX727_MY2021_Tx" SG_ 1107 OCSSerialNoByte7 1;
BA_ "U_U55X_MY2022_Rx" SG_ 1107 OCSSerialNoByte7 1;
BA_ "U_T6_MCA_MY2020_Rx" SG_ 1107 OCSSerialNoByte7 1;
BA_ "U_P702_MY2021_Rx" SG_ 1107 OCSSerialNoByte7 1;
BA_ "U_CX727_MY2021_Rx" SG_ 1107 OCSSerialNoByte7 1;
BA_ "U_U55X_MY2022_Tx" SG_ 1107 OCSSerialNoByte6 1;
BA_ "U_T6_MCA_MY2020_Tx" SG_ 1107 OCSSerialNoByte6 1;
BA_ "U_P702_MY2021_Tx" SG_ 1107 OCSSerialNoByte6 1;
BA_ "U_CX727_MY2021_Tx" SG_ 1107 OCSSerialNoByte6 1;
BA_ "U_U55X_MY2022_Rx" SG_ 1107 OCSSerialNoByte6 1;
BA_ "U_T6_MCA_MY2020_Rx" SG_ 1107 OCSSerialNoByte6 1;
BA_ "U_P702_MY2021_Rx" SG_ 1107 OCSSerialNoByte6 1;
BA_ "U_CX727_MY2021_Rx" SG_ 1107 OCSSerialNoByte6 1;
BA_ "U_U55X_MY2022_Tx" SG_ 1107 OCSSerialNoByte5 1;
BA_ "U_T6_MCA_MY2020_Tx" SG_ 1107 OCSSerialNoByte5 1;
BA_ "U_P702_MY2021_Tx" SG_ 1107 OCSSerialNoByte5 1;
BA_ "U_CX727_MY2021_Tx" SG_ 1107 OCSSerialNoByte5 1;
BA_ "U_U55X_MY2022_Rx" SG_ 1107 OCSSerialNoByte5 1;
BA_ "U_T6_MCA_MY2020_Rx" SG_ 1107 OCSSerialNoByte5 1;
BA_ "U_P702_MY2021_Rx" SG_ 1107 OCSSerialNoByte5 1;
BA_ "U_CX727_MY2021_Rx" SG_ 1107 OCSSerialNoByte5 1;
BA_ "U_U55X_MY2022_Tx" SG_ 1107 OCSSerialNoByte4 1;
BA_ "U_T6_MCA_MY2020_Tx" SG_ 1107 OCSSerialNoByte4 1;
BA_ "U_P702_MY2021_Tx" SG_ 1107 OCSSerialNoByte4 1;
BA_ "U_CX727_MY2021_Tx" SG_ 1107 OCSSerialNoByte4 1;
BA_ "U_U55X_MY2022_Rx" SG_ 1107 OCSSerialNoByte4 1;
BA_ "U_T6_MCA_MY2020_Rx" SG_ 1107 OCSSerialNoByte4 1;
BA_ "U_P702_MY2021_Rx" SG_ 1107 OCSSerialNoByte4 1;
BA_ "U_CX727_MY2021_Rx" SG_ 1107 OCSSerialNoByte4 1;
BA_ "U_U55X_MY2022_Tx" SG_ 1107 OCSSerialNoByte3 1;
BA_ "U_T6_MCA_MY2020_Tx" SG_ 1107 OCSSerialNoByte3 1;
BA_ "U_P702_MY2021_Tx" SG_ 1107 OCSSerialNoByte3 1;
BA_ "U_CX727_MY2021_Tx" SG_ 1107 OCSSerialNoByte3 1;
BA_ "U_U55X_MY2022_Rx" SG_ 1107 OCSSerialNoByte3 1;
BA_ "U_T6_MCA_MY2020_Rx" SG_ 1107 OCSSerialNoByte3 1;
BA_ "U_P702_MY2021_Rx" SG_ 1107 OCSSerialNoByte3 1;
BA_ "U_CX727_MY2021_Rx" SG_ 1107 OCSSerialNoByte3 1;
BA_ "U_U55X_MY2022_Tx" SG_ 1107 OCSSerialNoByte2 1;
BA_ "U_T6_MCA_MY2020_Tx" SG_ 1107 OCSSerialNoByte2 1;
BA_ "U_P702_MY2021_Tx" SG_ 1107 OCSSerialNoByte2 1;
BA_ "U_CX727_MY2021_Tx" SG_ 1107 OCSSerialNoByte2 1;
BA_ "U_U55X_MY2022_Rx" SG_ 1107 OCSSerialNoByte2 1;
BA_ "U_T6_MCA_MY2020_Rx" SG_ 1107 OCSSerialNoByte2 1;
BA_ "U_P702_MY2021_Rx" SG_ 1107 OCSSerialNoByte2 1;
BA_ "U_CX727_MY2021_Rx" SG_ 1107 OCSSerialNoByte2 1;
BA_ "U_U55X_MY2022_Tx" SG_ 1107 OCSSerialNoByte1 1;
BA_ "U_T6_MCA_MY2020_Tx" SG_ 1107 OCSSerialNoByte1 1;
BA_ "U_P702_MY2021_Tx" SG_ 1107 OCSSerialNoByte1 1;
BA_ "U_CX727_MY2021_Tx" SG_ 1107 OCSSerialNoByte1 1;
BA_ "U_U55X_MY2022_Rx" SG_ 1107 OCSSerialNoByte1 1;
BA_ "U_T6_MCA_MY2020_Rx" SG_ 1107 OCSSerialNoByte1 1;
BA_ "U_P702_MY2021_Rx" SG_ 1107 OCSSerialNoByte1 1;
BA_ "U_CX727_MY2021_Rx" SG_ 1107 OCSSerialNoByte1 1;
BA_ "U_P702_MY2021_Rx" SG_ 1879 TesterPhysicalReqTBM 1;
BA_ "GenSigSendType" SG_ 1879 TesterPhysicalReqTBM 3;
BA_ "U_CD764_MY2022_Tx" SG_ 145 VehYawWActl_D_Qf 1;
BA_ "U_U55X_MY2022_Tx" SG_ 145 VehYawWActl_D_Qf 1;
BA_ "U_CD542_MY2021_Tx" SG_ 145 VehYawWActl_D_Qf 1;
BA_ "U_T6_MCA_MY2020_Tx" SG_ 145 VehYawWActl_D_Qf 1;
BA_ "U_P702_MY2021_Tx" SG_ 145 VehYawWActl_D_Qf 1;
BA_ "U_CX727_MY2021_Tx" SG_ 145 VehYawWActl_D_Qf 1;
BA_ "U_CD542_MY2021_Rx" SG_ 145 VehYawWActl_D_Qf 1;
BA_ "U_T6_MCA_MY2020_Rx" SG_ 145 VehYawWActl_D_Qf 1;
BA_ "U_P702_MY2021_Rx" SG_ 145 VehYawWActl_D_Qf 1;
BA_ "U_CX727_MY2021_Rx" SG_ 145 VehYawWActl_D_Qf 1;
BA_ "GenSigStartValue" SG_ 145 VehYawWActl_D_Qf 1;
BA_ "MetaData" SG_ 145 VehYawWActl_D_Qf 1;
BA_ "GenSigStartValueInteger" SG_ 145 VehYawWActl_D_Qf 1;
BA_ "U_CD764_MY2022_Tx" SG_ 145 VehRolWActl_D_Qf 1;
BA_ "U_U55X_MY2022_Tx" SG_ 145 VehRolWActl_D_Qf 1;
BA_ "U_CD542_MY2021_Tx" SG_ 145 VehRolWActl_D_Qf 1;
BA_ "U_T6_MCA_MY2020_Tx" SG_ 145 VehRolWActl_D_Qf 1;
BA_ "U_P702_MY2021_Tx" SG_ 145 VehRolWActl_D_Qf 1;
BA_ "U_CX727_MY2021_Tx" SG_ 145 VehRolWActl_D_Qf 1;
BA_ "GenSigStartValue" SG_ 145 VehRolWActl_D_Qf 1;
BA_ "MetaData" SG_ 145 VehRolWActl_D_Qf 1;
BA_ "GenSigStartValueInteger" SG_ 145 VehRolWActl_D_Qf 1;
BA_ "U_CD764_MY2022_Tx" SG_ 145 VehRollYawW_No_Cs 1;
BA_ "U_U55X_MY2022_Tx" SG_ 145 VehRollYawW_No_Cs 1;
BA_ "U_CD542_MY2021_Tx" SG_ 145 VehRollYawW_No_Cs 1;
BA_ "U_T6_MCA_MY2020_Tx" SG_ 145 VehRollYawW_No_Cs 1;
BA_ "U_P702_MY2021_Tx" SG_ 145 VehRollYawW_No_Cs 1;
BA_ "U_CX727_MY2021_Tx" SG_ 145 VehRollYawW_No_Cs 1;
BA_ "MetaData" SG_ 145 VehRollYawW_No_Cs 1;
BA_ "U_CD764_MY2022_Tx" SG_ 145 VehRollYaw_No_Cnt 1;
BA_ "U_U55X_MY2022_Tx" SG_ 145 VehRollYaw_No_Cnt 1;
BA_ "U_CD542_MY2021_Tx" SG_ 145 VehRollYaw_No_Cnt 1;
BA_ "U_T6_MCA_MY2020_Tx" SG_ 145 VehRollYaw_No_Cnt 1;
BA_ "U_P702_MY2021_Tx" SG_ 145 VehRollYaw_No_Cnt 1;
BA_ "U_CX727_MY2021_Tx" SG_ 145 VehRollYaw_No_Cnt 1;
BA_ "MetaData" SG_ 145 VehRollYaw_No_Cnt 1;
BA_ "U_CD764_MY2022_Tx" SG_ 145 VehYaw_W_Actl 1;
BA_ "U_U55X_MY2022_Tx" SG_ 145 VehYaw_W_Actl 1;
BA_ "U_CD542_MY2021_Tx" SG_ 145 VehYaw_W_Actl 1;
BA_ "U_T6_MCA_MY2020_Tx" SG_ 145 VehYaw_W_Actl 1;
BA_ "U_P702_MY2021_Tx" SG_ 145 VehYaw_W_Actl 1;
BA_ "U_CX727_MY2021_Tx" SG_ 145 VehYaw_W_Actl 1;
BA_ "U_CD542_MY2021_Rx" SG_ 145 VehYaw_W_Actl 1;
BA_ "U_T6_MCA_MY2020_Rx" SG_ 145 VehYaw_W_Actl 1;
BA_ "U_P702_MY2021_Rx" SG_ 145 VehYaw_W_Actl 1;
BA_ "U_CX727_MY2021_Rx" SG_ 145 VehYaw_W_Actl 1;
BA_ "GenSigStartValue" SG_ 145 VehYaw_W_Actl 65534;
BA_ "GenSigStartValueInteger" SG_ 145 VehYaw_W_Actl 65534;
BA_ "U_CD764_MY2022_Tx" SG_ 145 VehRol_W_Actl 1;
BA_ "U_U55X_MY2022_Tx" SG_ 145 VehRol_W_Actl 1;
BA_ "U_CD542_MY2021_Tx" SG_ 145 VehRol_W_Actl 1;
BA_ "U_T6_MCA_MY2020_Tx" SG_ 145 VehRol_W_Actl 1;
BA_ "U_P702_MY2021_Tx" SG_ 145 VehRol_W_Actl 1;
BA_ "U_CX727_MY2021_Tx" SG_ 145 VehRol_W_Actl 1;
BA_ "GenSigStartValue" SG_ 145 VehRol_W_Actl 65534;
BA_ "GenSigStartValueInteger" SG_ 145 VehRol_W_Actl 65534;
BA_ "U_CD764_MY2022_Rx" SG_ 1828 TesterPhysicalReqSCCM 1;
BA_ "U_U55X_MY2022_Rx" SG_ 1828 TesterPhysicalReqSCCM 1;
BA_ "U_CD542_MY2021_Rx" SG_ 1828 TesterPhysicalReqSCCM 1;
BA_ "U_T6_MCA_MY2020_Rx" SG_ 1828 TesterPhysicalReqSCCM 1;
BA_ "U_P702_MY2021_Rx" SG_ 1828 TesterPhysicalReqSCCM 1;
BA_ "U_CX727_MY2021_Rx" SG_ 1828 TesterPhysicalReqSCCM 1;
BA_ "GenSigSendType" SG_ 1828 TesterPhysicalReqSCCM 3;
BA_ "GenSigStartValue" SG_ 1045 VehStab_D_Stat 14;
BA_ "GenSigStartValueInteger" SG_ 1045 VehStab_D_Stat 14;
BA_ "GenSigStartValue" SG_ 1045 VehYawNonLin_W_Rq 4094;
BA_ "GenSigStartValueInteger" SG_ 1045 VehYawNonLin_W_Rq 4094;
BA_ "GenSigStartValue" SG_ 1045 VehYawLin_W_Rq 4094;
BA_ "GenSigStartValueInteger" SG_ 1045 VehYawLin_W_Rq 4094;
BA_ "U_CD764_MY2022_Rx" SG_ 1045 VehVActlBrk_No_Cs 1;
BA_ "U_P702_MY2021_Rx" SG_ 1045 VehVActlBrk_No_Cs 1;
BA_ "MetaData" SG_ 1045 VehVActlBrk_No_Cs 1;
BA_ "U_U55X_MY2022_Rx" SG_ 1045 Veh_V_ActlBrk 1;
BA_ "U_CD542_MY2021_Rx" SG_ 1045 Veh_V_ActlBrk 1;
BA_ "U_T6_MCA_MY2020_Rx" SG_ 1045 Veh_V_ActlBrk 1;
BA_ "U_P702_MY2021_Rx" SG_ 1045 Veh_V_ActlBrk 1;
BA_ "U_CX727_MY2021_Rx" SG_ 1045 Veh_V_ActlBrk 1;
BA_ "U_CD764_MY2022_Rx" SG_ 1045 VehVActlBrk_No_Cnt 1;
BA_ "U_P702_MY2021_Rx" SG_ 1045 VehVActlBrk_No_Cnt 1;
BA_ "MetaData" SG_ 1045 VehVActlBrk_No_Cnt 1;
BA_ "U_U55X_MY2022_Rx" SG_ 1045 VehVActlBrk_D_Qf 1;
BA_ "U_CD542_MY2021_Rx" SG_ 1045 VehVActlBrk_D_Qf 1;
BA_ "U_T6_MCA_MY2020_Rx" SG_ 1045 VehVActlBrk_D_Qf 1;
BA_ "U_P702_MY2021_Rx" SG_ 1045 VehVActlBrk_D_Qf 1;
BA_ "U_CX727_MY2021_Rx" SG_ 1045 VehVActlBrk_D_Qf 1;
BA_ "MetaData" SG_ 1045 VehVActlBrk_D_Qf 1;
BA_ "U_CD764_MY2022_Tx" SG_ 146 VehVert2_A_Actl 1;
BA_ "U_U55X_MY2022_Tx" SG_ 146 VehVert2_A_Actl 1;
BA_ "U_CD542_MY2021_Tx" SG_ 146 VehVert2_A_Actl 1;
BA_ "U_T6_MCA_MY2020_Tx" SG_ 146 VehVert2_A_Actl 1;
BA_ "U_P702_MY2021_Tx" SG_ 146 VehVert2_A_Actl 1;
BA_ "U_CX727_MY2021_Tx" SG_ 146 VehVert2_A_Actl 1;
BA_ "U_U55X_MY2022_Rx" SG_ 146 VehVert2_A_Actl 1;
BA_ "U_T6_MCA_MY2020_Rx" SG_ 146 VehVert2_A_Actl 1;
BA_ "GenSigStartValue" SG_ 146 VehVert2_A_Actl 8190;
BA_ "GenSigStartValueInteger" SG_ 146 VehVert2_A_Actl 8190;
BA_ "U_CD764_MY2022_Tx" SG_ 146 VehLatLongVertA_No_Cs 1;
BA_ "U_U55X_MY2022_Tx" SG_ 146 VehLatLongVertA_No_Cs 1;
BA_ "U_CD542_MY2021_Tx" SG_ 146 VehLatLongVertA_No_Cs 1;
BA_ "U_T6_MCA_MY2020_Tx" SG_ 146 VehLatLongVertA_No_Cs 1;
BA_ "U_P702_MY2021_Tx" SG_ 146 VehLatLongVertA_No_Cs 1;
BA_ "U_CX727_MY2021_Tx" SG_ 146 VehLatLongVertA_No_Cs 1;
BA_ "MetaData" SG_ 146 VehLatLongVertA_No_Cs 1;
BA_ "U_CD764_MY2022_Tx" SG_ 146 VehLatLongVert_No_Cnt 1;
BA_ "U_U55X_MY2022_Tx" SG_ 146 VehLatLongVert_No_Cnt 1;
BA_ "U_CD542_MY2021_Tx" SG_ 146 VehLatLongVert_No_Cnt 1;
BA_ "U_T6_MCA_MY2020_Tx" SG_ 146 VehLatLongVert_No_Cnt 1;
BA_ "U_P702_MY2021_Tx" SG_ 146 VehLatLongVert_No_Cnt 1;
BA_ "U_CX727_MY2021_Tx" SG_ 146 VehLatLongVert_No_Cnt 1;
BA_ "MetaData" SG_ 146 VehLatLongVert_No_Cnt 1;
BA_ "U_CD764_MY2022_Tx" SG_ 146 VehLong2_A_Actl 1;
BA_ "U_U55X_MY2022_Tx" SG_ 146 VehLong2_A_Actl 1;
BA_ "U_CD542_MY2021_Tx" SG_ 146 VehLong2_A_Actl 1;
BA_ "U_T6_MCA_MY2020_Tx" SG_ 146 VehLong2_A_Actl 1;
BA_ "U_P702_MY2021_Tx" SG_ 146 VehLong2_A_Actl 1;
BA_ "U_CX727_MY2021_Tx" SG_ 146 VehLong2_A_Actl 1;
BA_ "U_U55X_MY2022_Rx" SG_ 146 VehLong2_A_Actl 1;
BA_ "U_T6_MCA_MY2020_Rx" SG_ 146 VehLong2_A_Actl 1;
BA_ "U_P702_MY2021_Rx" SG_ 146 VehLong2_A_Actl 1;
BA_ "GenSigStartValue" SG_ 146 VehLong2_A_Actl 8190;
BA_ "GenSigStartValueInteger" SG_ 146 VehLong2_A_Actl 8190;
BA_ "U_CD764_MY2022_Tx" SG_ 146 VehLat2_A_Actl 1;
BA_ "U_U55X_MY2022_Tx" SG_ 146 VehLat2_A_Actl 1;
BA_ "U_CD542_MY2021_Tx" SG_ 146 VehLat2_A_Actl 1;
BA_ "U_T6_MCA_MY2020_Tx" SG_ 146 VehLat2_A_Actl 1;
BA_ "U_P702_MY2021_Tx" SG_ 146 VehLat2_A_Actl 1;
BA_ "U_CX727_MY2021_Tx" SG_ 146 VehLat2_A_Actl 1;
BA_ "U_U55X_MY2022_Rx" SG_ 146 VehLat2_A_Actl 1;
BA_ "U_T6_MCA_MY2020_Rx" SG_ 146 VehLat2_A_Actl 1;
BA_ "U_P702_MY2021_Rx" SG_ 146 VehLat2_A_Actl 1;
BA_ "GenSigStartValue" SG_ 146 VehLat2_A_Actl 8190;
BA_ "GenSigStartValueInteger" SG_ 146 VehLat2_A_Actl 8190;
BA_ "U_CD764_MY2022_Tx" SG_ 146 VehVertAActl_D_Qf 1;
BA_ "U_U55X_MY2022_Tx" SG_ 146 VehVertAActl_D_Qf 1;
BA_ "U_CD542_MY2021_Tx" SG_ 146 VehVertAActl_D_Qf 1;
BA_ "U_T6_MCA_MY2020_Tx" SG_ 146 VehVertAActl_D_Qf 1;
BA_ "U_P702_MY2021_Tx" SG_ 146 VehVertAActl_D_Qf 1;
BA_ "U_CX727_MY2021_Tx" SG_ 146 VehVertAActl_D_Qf 1;
BA_ "U_U55X_MY2022_Rx" SG_ 146 VehVertAActl_D_Qf 1;
BA_ "U_T6_MCA_MY2020_Rx" SG_ 146 VehVertAActl_D_Qf 1;
BA_ "GenSigStartValue" SG_ 146 VehVertAActl_D_Qf 1;
BA_ "MetaData" SG_ 146 VehVertAActl_D_Qf 1;
BA_ "GenSigStartValueInteger" SG_ 146 VehVertAActl_D_Qf 1;
BA_ "U_CD764_MY2022_Tx" SG_ 146 VehLongAActl_D_Qf 1;
BA_ "U_U55X_MY2022_Tx" SG_ 146 VehLongAActl_D_Qf 1;
BA_ "U_CD542_MY2021_Tx" SG_ 146 VehLongAActl_D_Qf 1;
BA_ "U_T6_MCA_MY2020_Tx" SG_ 146 VehLongAActl_D_Qf 1;
BA_ "U_P702_MY2021_Tx" SG_ 146 VehLongAActl_D_Qf 1;
BA_ "U_CX727_MY2021_Tx" SG_ 146 VehLongAActl_D_Qf 1;
BA_ "U_U55X_MY2022_Rx" SG_ 146 VehLongAActl_D_Qf 1;
BA_ "U_T6_MCA_MY2020_Rx" SG_ 146 VehLongAActl_D_Qf 1;
BA_ "U_P702_MY2021_Rx" SG_ 146 VehLongAActl_D_Qf 1;
BA_ "GenSigStartValue" SG_ 146 VehLongAActl_D_Qf 1;
BA_ "MetaData" SG_ 146 VehLongAActl_D_Qf 1;
BA_ "GenSigStartValueInteger" SG_ 146 VehLongAActl_D_Qf 1;
BA_ "U_CD764_MY2022_Tx" SG_ 146 VehLatAActl_D_Qf 1;
BA_ "U_U55X_MY2022_Tx" SG_ 146 VehLatAActl_D_Qf 1;
BA_ "U_CD542_MY2021_Tx" SG_ 146 VehLatAActl_D_Qf 1;
BA_ "U_T6_MCA_MY2020_Tx" SG_ 146 VehLatAActl_D_Qf 1;
BA_ "U_P702_MY2021_Tx" SG_ 146 VehLatAActl_D_Qf 1;
BA_ "U_CX727_MY2021_Tx" SG_ 146 VehLatAActl_D_Qf 1;
BA_ "U_U55X_MY2022_Rx" SG_ 146 VehLatAActl_D_Qf 1;
BA_ "U_T6_MCA_MY2020_Rx" SG_ 146 VehLatAActl_D_Qf 1;
BA_ "U_P702_MY2021_Rx" SG_ 146 VehLatAActl_D_Qf 1;
BA_ "GenSigStartValue" SG_ 146 VehLatAActl_D_Qf 1;
BA_ "MetaData" SG_ 146 VehLatAActl_D_Qf 1;
BA_ "GenSigStartValueInteger" SG_ 146 VehLatAActl_D_Qf 1;
BA_ "U_T6_MCA_MY2020_Rx" SG_ 1938 TesterPhysicalReqATCM 1;
BA_ "U_U55X_MY2022_Rx" SG_ 1938 TesterPhysicalReqATCM 1;
BA_ "U_P702_MY2021_Rx" SG_ 1938 TesterPhysicalReqATCM 1;
BA_ "GenSigSendType" SG_ 1938 TesterPhysicalReqATCM 3;
BA_ "GenSigSendType" SG_ 984 DsmcMsgTxt_D_Dsply 3;
BA_ "GenSigSendType" SG_ 984 AhbFeat_D_Stat 3;
BA_ "GenSigSendType" SG_ 984 AhbcStat_B_Dsply 3;
BA_ "U_CD764_MY2022_Rx" SG_ 984 AhbHiBeam_D_Rq 1;
BA_ "U_U55X_MY2022_Rx" SG_ 984 AhbHiBeam_D_Rq 1;
BA_ "U_CD542_MY2021_Rx" SG_ 984 AhbHiBeam_D_Rq 1;
BA_ "U_T6_MCA_MY2020_Rx" SG_ 984 AhbHiBeam_D_Rq 1;
BA_ "U_P702_MY2021_Rx" SG_ 984 AhbHiBeam_D_Rq 1;
BA_ "U_CX727_MY2021_Rx" SG_ 984 AhbHiBeam_D_Rq 1;
BA_ "GenSigSendType" SG_ 984 AhbHiBeam_D_Rq 3;
BA_ "GenSigSendType" SG_ 984 DasWarn_D_Dsply 3;
BA_ "GenSigSendType" SG_ 984 DasStats_D_Dsply 3;
BA_ "GenSigSendType" SG_ 984 DasAlrtLvl_D_Dsply 3;
BA_ "GenSigSendType" SG_ 984 CamraStats_D_Dsply 3;
BA_ "GenSigSendType" SG_ 984 CamraDefog_B_Req 3;
BA_ "GenSigSendType" SG_ 984 LaHandsOff_D_Dsply 3;
BA_ "GenSigSendType" SG_ 984 LaDenyStats_B_Dsply 3;
BA_ "GenSigSendType" SG_ 984 LaActvStats_D_Dsply 3;
BA_ "U_CD542_MY2021_Rx" SG_ 984 AhbcRampingV_D_Rq 1;
BA_ "U_T6_MCA_MY2020_Rx" SG_ 984 AhbcRampingV_D_Rq 1;
BA_ "U_P702_MY2021_Rx" SG_ 984 AhbcRampingV_D_Rq 1;
BA_ "U_CX727_MY2021_Rx" SG_ 984 AhbcRampingV_D_Rq 1;
BA_ "GenSigSendType" SG_ 984 AhbcRampingV_D_Rq 3;
BA_ "GenSigSendType" SG_ 984 PersIndexIpma_D_Actl 3;
BA_ "GenSigStartValue" SG_ 984 PersIndexIpma_D_Actl 4;
BA_ "GenSigStartValueInteger" SG_ 984 PersIndexIpma_D_Actl 4;
BA_ "GenSigSendType" SG_ 984 FeatNoIpmaActl 3;
BA_ "GenSigSendType" SG_ 984 FeatConfigIpmaActl 3;
BA_ "U_CD764_MY2022_Tx" SG_ 998 PersIndexSccm_D_Actl 1;
BA_ "U_U55X_MY2022_Tx" SG_ 998 PersIndexSccm_D_Actl 1;
BA_ "U_CD542_MY2021_Tx" SG_ 998 PersIndexSccm_D_Actl 1;
BA_ "U_T6_MCA_MY2020_Tx" SG_ 998 PersIndexSccm_D_Actl 1;
BA_ "U_P702_MY2021_Tx" SG_ 998 PersIndexSccm_D_Actl 1;
BA_ "U_CX727_MY2021_Tx" SG_ 998 PersIndexSccm_D_Actl 1;
BA_ "GenSigSendType" SG_ 998 PersIndexSccm_D_Actl 3;
BA_ "GenSigStartValue" SG_ 998 PersIndexSccm_D_Actl 4;
BA_ "GenSigStartValueInteger" SG_ 998 PersIndexSccm_D_Actl 4;
BA_ "U_CD764_MY2022_Tx" SG_ 998 FeatNoSccmActl 1;
BA_ "U_U55X_MY2022_Tx" SG_ 998 FeatNoSccmActl 1;
BA_ "U_CD542_MY2021_Tx" SG_ 998 FeatNoSccmActl 1;
BA_ "U_T6_MCA_MY2020_Tx" SG_ 998 FeatNoSccmActl 1;
BA_ "U_P702_MY2021_Tx" SG_ 998 FeatNoSccmActl 1;
BA_ "U_CX727_MY2021_Tx" SG_ 998 FeatNoSccmActl 1;
BA_ "GenSigSendType" SG_ 998 FeatNoSccmActl 3;
BA_ "U_CD764_MY2022_Tx" SG_ 998 FeatConfigSccmActl 1;
BA_ "U_U55X_MY2022_Tx" SG_ 998 FeatConfigSccmActl 1;
BA_ "U_CD542_MY2021_Tx" SG_ 998 FeatConfigSccmActl 1;
BA_ "U_T6_MCA_MY2020_Tx" SG_ 998 FeatConfigSccmActl 1;
BA_ "U_P702_MY2021_Tx" SG_ 998 FeatConfigSccmActl 1;
BA_ "U_CX727_MY2021_Tx" SG_ 998 FeatConfigSccmActl 1;
BA_ "GenSigSendType" SG_ 998 FeatConfigSccmActl 3;
BA_ "U_U55X_MY2022_Tx" SG_ 613 BeltWarnThres_D_Stat 1;
BA_ "U_T6_MCA_MY2020_Tx" SG_ 613 BeltWarnThres_D_Stat 1;
BA_ "U_P702_MY2021_Tx" SG_ 613 BeltWarnThres_D_Stat 1;
BA_ "U_CX727_MY2021_Tx" SG_ 613 BeltWarnThres_D_Stat 1;
BA_ "U_U55X_MY2022_Rx" SG_ 613 BeltWarnThres_D_Stat 1;
BA_ "U_T6_MCA_MY2020_Rx" SG_ 613 BeltWarnThres_D_Stat 1;
BA_ "U_P702_MY2021_Rx" SG_ 613 BeltWarnThres_D_Stat 1;
BA_ "U_CX727_MY2021_Rx" SG_ 613 BeltWarnThres_D_Stat 1;
BA_ "GenSigSendType" SG_ 613 BeltWarnThres_D_Stat 3;
BA_ "GenSigStartValue" SG_ 613 BeltWarnThres_D_Stat 6;
BA_ "GenSigStartValueInteger" SG_ 613 BeltWarnThres_D_Stat 6;
BA_ "U_U55X_MY2022_Tx" SG_ 613 VehicleMYCalibrationId 1;
BA_ "U_T6_MCA_MY2020_Tx" SG_ 613 VehicleMYCalibrationId 1;
BA_ "U_P702_MY2021_Tx" SG_ 613 VehicleMYCalibrationId 1;
BA_ "U_CX727_MY2021_Tx" SG_ 613 VehicleMYCalibrationId 1;
BA_ "U_U55X_MY2022_Rx" SG_ 613 VehicleMYCalibrationId 1;
BA_ "U_T6_MCA_MY2020_Rx" SG_ 613 VehicleMYCalibrationId 1;
BA_ "U_P702_MY2021_Rx" SG_ 613 VehicleMYCalibrationId 1;
BA_ "U_CX727_MY2021_Rx" SG_ 613 VehicleMYCalibrationId 1;
BA_ "U_U55X_MY2022_Tx" SG_ 613 VehicleCalibrationId 1;
BA_ "U_T6_MCA_MY2020_Tx" SG_ 613 VehicleCalibrationId 1;
BA_ "U_P702_MY2021_Tx" SG_ 613 VehicleCalibrationId 1;
BA_ "U_CX727_MY2021_Tx" SG_ 613 VehicleCalibrationId 1;
BA_ "U_U55X_MY2022_Rx" SG_ 613 VehicleCalibrationId 1;
BA_ "U_T6_MCA_MY2020_Rx" SG_ 613 VehicleCalibrationId 1;
BA_ "U_P702_MY2021_Rx" SG_ 613 VehicleCalibrationId 1;
BA_ "U_CX727_MY2021_Rx" SG_ 613 VehicleCalibrationId 1;
BA_ "U_U55X_MY2022_Tx" SG_ 613 OCSSensrDataUpperLim 1;
BA_ "U_T6_MCA_MY2020_Tx" SG_ 613 OCSSensrDataUpperLim 1;
BA_ "U_P702_MY2021_Tx" SG_ 613 OCSSensrDataUpperLim 1;
BA_ "U_CX727_MY2021_Tx" SG_ 613 OCSSensrDataUpperLim 1;
BA_ "U_U55X_MY2022_Rx" SG_ 613 OCSSensrDataUpperLim 1;
BA_ "U_T6_MCA_MY2020_Rx" SG_ 613 OCSSensrDataUpperLim 1;
BA_ "U_P702_MY2021_Rx" SG_ 613 OCSSensrDataUpperLim 1;
BA_ "U_CX727_MY2021_Rx" SG_ 613 OCSSensrDataUpperLim 1;
BA_ "GenSigSendType" SG_ 613 OCSSensrDataUpperLim 3;
BA_ "U_U55X_MY2022_Tx" SG_ 613 OCSSensrDataLowerLim 1;
BA_ "U_T6_MCA_MY2020_Tx" SG_ 613 OCSSensrDataLowerLim 1;
BA_ "U_P702_MY2021_Tx" SG_ 613 OCSSensrDataLowerLim 1;
BA_ "U_CX727_MY2021_Tx" SG_ 613 OCSSensrDataLowerLim 1;
BA_ "U_U55X_MY2022_Rx" SG_ 613 OCSSensrDataLowerLim 1;
BA_ "U_T6_MCA_MY2020_Rx" SG_ 613 OCSSensrDataLowerLim 1;
BA_ "U_P702_MY2021_Rx" SG_ 613 OCSSensrDataLowerLim 1;
BA_ "U_CX727_MY2021_Rx" SG_ 613 OCSSensrDataLowerLim 1;
BA_ "GenSigSendType" SG_ 613 OCSSensrDataLowerLim 3;
BA_ "U_U55X_MY2022_Tx" SG_ 613 OCSLevel2Error 1;
BA_ "U_T6_MCA_MY2020_Tx" SG_ 613 OCSLevel2Error 1;
BA_ "U_P702_MY2021_Tx" SG_ 613 OCSLevel2Error 1;
BA_ "U_CX727_MY2021_Tx" SG_ 613 OCSLevel2Error 1;
BA_ "U_U55X_MY2022_Rx" SG_ 613 OCSLevel2Error 1;
BA_ "U_T6_MCA_MY2020_Rx" SG_ 613 OCSLevel2Error 1;
BA_ "U_P702_MY2021_Rx" SG_ 613 OCSLevel2Error 1;
BA_ "U_CX727_MY2021_Rx" SG_ 613 OCSLevel2Error 1;
BA_ "GenSigSendType" SG_ 613 ObjectEntrapped 3;
BA_ "U_U55X_MY2022_Tx" SG_ 613 OCSLevel1Error 1;
BA_ "U_T6_MCA_MY2020_Tx" SG_ 613 OCSLevel1Error 1;
BA_ "U_P702_MY2021_Tx" SG_ 613 OCSLevel1Error 1;
BA_ "U_CX727_MY2021_Tx" SG_ 613 OCSLevel1Error 1;
BA_ "U_U55X_MY2022_Rx" SG_ 613 OCSLevel1Error 1;
BA_ "U_T6_MCA_MY2020_Rx" SG_ 613 OCSLevel1Error 1;
BA_ "U_P702_MY2021_Rx" SG_ 613 OCSLevel1Error 1;
BA_ "U_CX727_MY2021_Rx" SG_ 613 OCSLevel1Error 1;
BA_ "GenSigSendType" SG_ 613 OCSLevel1Error 3;
BA_ "U_CD764_MY2022_Tx" SG_ 1664 UUDTRCMResponse1 1;
BA_ "U_U55X_MY2022_Tx" SG_ 1664 UUDTRCMResponse1 1;
BA_ "U_CD542_MY2021_Tx" SG_ 1664 UUDTRCMResponse1 1;
BA_ "U_T6_MCA_MY2020_Tx" SG_ 1664 UUDTRCMResponse1 1;
BA_ "U_P702_MY2021_Tx" SG_ 1664 UUDTRCMResponse1 1;
BA_ "U_CX727_MY2021_Tx" SG_ 1664 UUDTRCMResponse1 1;
BA_ "GenSigSendType" SG_ 1664 UUDTRCMResponse1 3;
BA_ "U_CD764_MY2022_Rx" SG_ 1814 TesterPhysicalReqGWM_H2 1;
BA_ "U_U55X_MY2022_Rx" SG_ 1814 TesterPhysicalReqGWM_H2 1;
BA_ "U_CD542_MY2021_Rx" SG_ 1814 TesterPhysicalReqGWM_H2 1;
BA_ "ECGUsedRxSignal" SG_ 1814 TesterPhysicalReqGWM_H2 1;
BA_ "U_T6_MCA_MY2020_Rx" SG_ 1814 TesterPhysicalReqGWM_H2 1;
BA_ "GenSigSendType" SG_ 1814 TesterPhysicalReqGWM_H2 3;
BA_ "U_CD764_MY2022_Rx" SG_ 2033 TesterPhysicalReqPCU 1;
BA_ "U_U55X_MY2022_Rx" SG_ 2033 TesterPhysicalReqPCU 1;
BA_ "U_CD542_MY2021_Rx" SG_ 2033 TesterPhysicalReqPCU 1;
BA_ "U_T6_MCA_MY2020_Rx" SG_ 2033 TesterPhysicalReqPCU 1;
BA_ "U_P702_MY2021_Rx" SG_ 2033 TesterPhysicalReqPCU 1;
BA_ "U_CX727_MY2021_Rx" SG_ 2033 TesterPhysicalReqPCU 1;
BA_ "GenSigSendType" SG_ 2033 TesterPhysicalReqPCU 3;
BA_ "GenSigStartValue" SG_ 130 Veh_V_RqMxTrlrAid 255;
BA_ "GenSigStartValueInteger" SG_ 130 Veh_V_RqMxTrlrAid 255;
BA_ "GenSigStartValueInteger" SG_ 130 DrvSte_Tq_Actl 128;
BA_ "U_P702_MY2021_Rx" SG_ 130 SteMdule_D_Stat 1;
BA_ "GenSigStartValue" SG_ 130 SteMdule_U_Meas 255;
BA_ "GenSigStartValueInteger" SG_ 130 SteMdule_U_Meas 255;
BA_ "GenSigStartValue" SG_ 130 SteMdule_I_Est 4095;
BA_ "GenSigStartValueInteger" SG_ 130 SteMdule_I_Est 4095;
BA_ "U_CD764_MY2022_Rx" SG_ 130 EPAS_Failure 1;
BA_ "U_U55X_MY2022_Rx" SG_ 130 EPAS_Failure 1;
BA_ "U_CD542_MY2021_Rx" SG_ 130 EPAS_Failure 1;
BA_ "U_T6_MCA_MY2020_Rx" SG_ 130 EPAS_Failure 1;
BA_ "U_P702_MY2021_Rx" SG_ 130 EPAS_Failure 1;
BA_ "GenSigStartValue" SG_ 130 SteeringColumnTorque 254;
BA_ "GenSigStartValueInteger" SG_ 130 SteeringColumnTorque 254;
BA_ "U_CD764_MY2022_Tx" SG_ 1855 TesterPhysicalResRCM 1;
BA_ "U_U55X_MY2022_Tx" SG_ 1855 TesterPhysicalResRCM 1;
BA_ "U_CD542_MY2021_Tx" SG_ 1855 TesterPhysicalResRCM 1;
BA_ "U_T6_MCA_MY2020_Tx" SG_ 1855 TesterPhysicalResRCM 1;
BA_ "U_P702_MY2021_Tx" SG_ 1855 TesterPhysicalResRCM 1;
BA_ "U_CX727_MY2021_Tx" SG_ 1855 TesterPhysicalResRCM 1;
BA_ "GenSigSendType" SG_ 1855 TesterPhysicalResRCM 3;
BA_ "U_CD764_MY2022_Rx" SG_ 1847 TesterPhysicalReqRCM 1;
BA_ "U_U55X_MY2022_Rx" SG_ 1847 TesterPhysicalReqRCM 1;
BA_ "U_CD542_MY2021_Rx" SG_ 1847 TesterPhysicalReqRCM 1;
BA_ "U_T6_MCA_MY2020_Rx" SG_ 1847 TesterPhysicalReqRCM 1;
BA_ "U_P702_MY2021_Rx" SG_ 1847 TesterPhysicalReqRCM 1;
BA_ "U_CX727_MY2021_Rx" SG_ 1847 TesterPhysicalReqRCM 1;
BA_ "GenSigSendType" SG_ 1847 TesterPhysicalReqRCM 3;
BA_ "GenSigSendType" SG_ 827 LghtAmbIntns_D2_Sns 3;
BA_ "GenSigStartValue" SG_ 827 LghtAmbIntns_D2_Sns 3;
BA_ "U_CD764_MY2022_Tx" SG_ 827 SteClmnSwtchTlt_D_Stat 1;
BA_ "U_U55X_MY2022_Tx" SG_ 827 SteClmnSwtchTlt_D_Stat 1;
BA_ "U_CD542_MY2021_Tx" SG_ 827 SteClmnSwtchTlt_D_Stat 1;
BA_ "U_T6_MCA_MY2020_Tx" SG_ 827 SteClmnSwtchTlt_D_Stat 1;
BA_ "U_P702_MY2021_Tx" SG_ 827 SteClmnSwtchTlt_D_Stat 1;
BA_ "U_CX727_MY2021_Tx" SG_ 827 SteClmnSwtchTlt_D_Stat 1;
BA_ "GenSigSendType" SG_ 827 SteClmnSwtchTlt_D_Stat 3;
BA_ "WakeupSignal" SG_ 827 SteClmnSwtchTlt_D_Stat 1;
BA_ "U_CD764_MY2022_Tx" SG_ 827 SteClmnSwtchTel_D_Stat 1;
BA_ "U_U55X_MY2022_Tx" SG_ 827 SteClmnSwtchTel_D_Stat 1;
BA_ "U_CD542_MY2021_Tx" SG_ 827 SteClmnSwtchTel_D_Stat 1;
BA_ "U_T6_MCA_MY2020_Tx" SG_ 827 SteClmnSwtchTel_D_Stat 1;
BA_ "U_P702_MY2021_Tx" SG_ 827 SteClmnSwtchTel_D_Stat 1;
BA_ "U_CX727_MY2021_Tx" SG_ 827 SteClmnSwtchTel_D_Stat 1;
BA_ "GenSigSendType" SG_ 827 SteClmnSwtchTel_D_Stat 3;
BA_ "WakeupSignal" SG_ 827 SteClmnSwtchTel_D_Stat 1;
BA_ "U_CD764_MY2022_Tx" SG_ 827 LghtAmbIntns_D_Sns 1;
BA_ "U_U55X_MY2022_Tx" SG_ 827 LghtAmbIntns_D_Sns 1;
BA_ "U_CD542_MY2021_Tx" SG_ 827 LghtAmbIntns_D_Sns 1;
BA_ "U_T6_MCA_MY2020_Tx" SG_ 827 LghtAmbIntns_D_Sns 1;
BA_ "U_P702_MY2021_Tx" SG_ 827 LghtAmbIntns_D_Sns 1;
BA_ "U_CX727_MY2021_Tx" SG_ 827 LghtAmbIntns_D_Sns 1;
BA_ "GenSigSendType" SG_ 827 LghtAmbIntns_D_Sns 3;
BA_ "U_CD764_MY2022_Tx" SG_ 827 LghtAmb_Intns_Sns 1;
BA_ "U_U55X_MY2022_Tx" SG_ 827 LghtAmb_Intns_Sns 1;
BA_ "U_CD542_MY2021_Tx" SG_ 827 LghtAmb_Intns_Sns 1;
BA_ "U_T6_MCA_MY2020_Tx" SG_ 827 LghtAmb_Intns_Sns 1;
BA_ "U_P702_MY2021_Tx" SG_ 827 LghtAmb_Intns_Sns 1;
BA_ "U_CX727_MY2021_Tx" SG_ 827 LghtAmb_Intns_Sns 1;
BA_ "U_CD764_MY2022_Rx" SG_ 848 RILStat 1;
BA_ "U_U55X_MY2022_Rx" SG_ 848 RILStat 1;
BA_ "U_CD542_MY2021_Rx" SG_ 848 RILStat 1;
BA_ "U_T6_MCA_MY2020_Rx" SG_ 848 RILStat 1;
BA_ "U_P702_MY2021_Rx" SG_ 848 RILStat 1;
BA_ "U_CX727_MY2021_Rx" SG_ 848 RILStat 1;
BA_ "U_CD764_MY2022_Tx" SG_ 1822 TesterPhysicalResGWM_H2 1;
BA_ "U_U55X_MY2022_Tx" SG_ 1822 TesterPhysicalResGWM_H2 1;
BA_ "U_CD542_MY2021_Tx" SG_ 1822 TesterPhysicalResGWM_H2 1;
BA_ "ECGUsedTxSignal" SG_ 1822 TesterPhysicalResGWM_H2 1;
BA_ "U_T6_MCA_MY2020_Tx" SG_ 1822 TesterPhysicalResGWM_H2 1;
BA_ "GenSigSendType" SG_ 1822 TesterPhysicalResGWM_H2 3;
BA_ "U_U55X_MY2022_Tx" SG_ 1901 TesterPhysicalResOCS 1;
BA_ "U_T6_MCA_MY2020_Tx" SG_ 1901 TesterPhysicalResOCS 1;
BA_ "U_P702_MY2021_Tx" SG_ 1901 TesterPhysicalResOCS 1;
BA_ "U_CX727_MY2021_Tx" SG_ 1901 TesterPhysicalResOCS 1;
BA_ "GenSigSendType" SG_ 1901 TesterPhysicalResOCS 3;
BA_ "U_U55X_MY2022_Rx" SG_ 1893 TesterPhysicalReqOCS 1;
BA_ "U_T6_MCA_MY2020_Rx" SG_ 1893 TesterPhysicalReqOCS 1;
BA_ "U_P702_MY2021_Rx" SG_ 1893 TesterPhysicalReqOCS 1;
BA_ "U_CX727_MY2021_Rx" SG_ 1893 TesterPhysicalReqOCS 1;
BA_ "GenSigSendType" SG_ 1893 TesterPhysicalReqOCS 3;
BA_ "U_T6_MCA_MY2020_Tx" SG_ 1946 TesterPhysicalResATCM 1;
BA_ "U_U55X_MY2022_Tx" SG_ 1946 TesterPhysicalResATCM 1;
BA_ "U_P702_MY2021_Tx" SG_ 1946 TesterPhysicalResATCM 1;
BA_ "GenSigSendType" SG_ 1946 TesterPhysicalResATCM 3;
BA_ "GenSigSendType" SG_ 1887 TesterPhysicalResTBM 3;
BA_ "GenSigStartValue" SG_ 392 HudShifPoint_N_Actl 30;
BA_ "GenSigStartValueInteger" SG_ 392 HudShifPoint_N_Actl 30;
BA_ "GenSigSendType" SG_ 392 HudMde_D_Stat 3;
BA_ "GenSigSendType" SG_ 392 HudLedMde_D_Stat 3;
BA_ "GenSigSendType" SG_ 392 HudLed9On_B_Stat 3;
BA_ "GenSigSendType" SG_ 392 HudLed8On_B_Stat 3;
BA_ "GenSigSendType" SG_ 392 HudLed7On_B_Stat 3;
BA_ "GenSigSendType" SG_ 392 Hud_B_Falt 3;
BA_ "GenSigSendType" SG_ 392 HudActv_B_Actl 3;
BA_ "GenSigSendType" SG_ 392 Hud_B_Avail 3;
BA_ "GenSigStartValue" SG_ 392 Hud_B_Avail 1;
BA_ "GenSigStartValueInteger" SG_ 392 Hud_B_Avail 1;
BA_ "GenSigSendType" SG_ 392 HudLed6On_B_Stat 3;
BA_ "GenSigSendType" SG_ 392 HudLed5On_B_Stat 3;
BA_ "GenSigSendType" SG_ 392 HudLed4On_B_Stat 3;
BA_ "GenSigSendType" SG_ 392 HudLed3On_B_Stat 3;
BA_ "GenSigSendType" SG_ 392 HudLed2On_B_Stat 3;
BA_ "GenSigSendType" SG_ 392 HudLed1On_B_Stat 3;
BA_ "GenSigSendType" SG_ 392 HudLed18On_B_Stat 3;
BA_ "GenSigSendType" SG_ 392 HudLed17On_B_Stat 3;
BA_ "GenSigSendType" SG_ 392 HudLed16On_B_Stat 3;
BA_ "GenSigSendType" SG_ 392 HudLed15On_B_Stat 3;
BA_ "GenSigSendType" SG_ 392 HudLed14On_B_Stat 3;
BA_ "GenSigSendType" SG_ 392 HudLed13On_B_Stat 3;
BA_ "GenSigSendType" SG_ 392 HudLed12On_B_Stat 3;
BA_ "GenSigSendType" SG_ 392 HudLed11On_B_Stat 3;
BA_ "GenSigSendType" SG_ 392 HudLed10On_B_Stat 3;
VAL_ 391 CadsRadarStat_D_Qf 3 "OK" 2 "Not_Within_Specifications" 1 "No_Data_Exists" 0 "Faulty" ;
VAL_ 391 HudBlk3_B_Rq 1 "Yes" 0 "No" ;
VAL_ 391 HudBlk2_B_Rq 1 "Yes" 0 "No" ;
VAL_ 391 HudBlk1_B_Rq 1 "Yes" 0 "No" ;
VAL_ 391 HudFlashRate_D_Actl 3 "Unused" 2 "Flash_4Hz_50Prct_DutyCycle" 1 "On" 0 "Off" ;
VAL_ 391 CmbbBrkPrchg_D_Rq 3 "Undefined" 2 "Level_2_PreCharge_Request" 1 "Level_1_PreCharge_Request" 0 "No_PreCharge_Request" ;
VAL_ 391 CmbbBrkDecel_B_Rq 1 "Yes" 0 "No" ;
VAL_ 391 CmbbBaSens_D_Rq 3 "Level_3" 2 "Level_2" 1 "Level_1" 0 "Normal" ;
VAL_ 535 WhlRr_W_Meas 32767 "Fault" 32766 "Unknown" ;
VAL_ 535 WhlRl_W_Meas 32767 "Fault" 32766 "Unknown" ;
VAL_ 535 WhlFr_W_Meas 32767 "Fault" 32766 "Unknown" ;
VAL_ 535 WhlFl_W_Meas 32767 "Fault" 32766 "Unknown" ;
VAL_ 531 VehStop_D_Stat 3 "Faulty" 2 "NoDataExists" 1 "Yes" 0 "No" ;
VAL_ 531 TracCtlPtActv_B_Actl 1 "Active" 0 "Inactive" ;
VAL_ 531 LscmbbMntr_B_Err 1 "DisplayMessage" 0 "NoMessage" ;
VAL_ 531 LscmbbBrkDis_B_Actl 1 "Yes" 0 "No" ;
VAL_ 531 LscmbbDeny_B_ActlBrk 1 "Yes" 0 "No" ;
VAL_ 531 PrkBrkYwLamp_D_Rq 3 "Fast_Flash" 2 "Slow_Flash" 1 "On" 0 "Off" ;
VAL_ 531 PrkBrkRedLamp_D_Rq 3 "Fast_Flash" 2 "Slow_Flash" 1 "On" 0 "Off" ;
VAL_ 531 VehicleStationary 1 "Yes" 0 "No" ;
VAL_ 531 LscmbbBrkDecel_B_Actl 1 "Yes" 0 "No" ;
VAL_ 531 AbsActv_B_Actl 1 "Yes" 0 "No" ;
VAL_ 531 StabCtlBrkActv_B_Actl 1 "Yes" 0 "No" ;
VAL_ 531 CmbbBrkPrchg_B_Actl 1 "Yes" 0 "No" ;
VAL_ 531 CmbbBrkDecel_B_Actl 1 "Yes" 0 "No" ;
VAL_ 531 CmbbBaSensInc_B_Actl 1 "Yes" 0 "No" ;
VAL_ 531 AccBrkWarm_B_Actl 1 "Yes" 0 "No" ;
VAL_ 531 AccBrkTotTqMn_B_Actl 1 "Yes" 0 "No" ;
VAL_ 531 AccBrkPrchgActv_B_Actl 1 "Yes" 0 "No" ;
VAL_ 531 AccBrkDis_B_Actl 1 "Yes" 0 "No" ;
VAL_ 531 AccBrkDeny_B_Actl 1 "Yes" 0 "No" ;
VAL_ 531 AccBrkActv_B_Actl 1 "Yes" 0 "No" ;
VAL_ 531 PrplDrgCtlActv_B_Actl 1 "Active" 0 "Inactive" ;
VAL_ 531 LscmbbBaSensInc_B_Actl 1 "Yes" 0 "No" ;
VAL_ 531 CmbbBrkDis_B_Actl 1 "Yes" 0 "No" ;
VAL_ 531 CmbbDeny_B_ActlBrk 1 "Yes" 0 "No" ;
VAL_ 531 CcDis_B_Cmd 1 "Yes" 0 "No" ;
VAL_ 531 VehLongOvrGnd_A_Est 1023 "Fault" 1022 "Unknown" ;
VAL_ 531 LscmbBrkPrchg_B_Actl 1 "Active" 0 "Inactive" ;
VAL_ 531 AccStopActv_B_ActlBrk 1 "Yes" 0 "No" ;
VAL_ 531 AccDis_B_ActlEpb 1 "Yes" 0 "No" ;
VAL_ 531 PrkBrkMsgTxt_D_Rq 15 "Message15" 14 "Message14" 13 "Message13" 12 "Message12" 11 "Message11" 10 "Message10" 9 "Message9" 8 "Message8" 7 "Message7" 6 "Message6" 5 "Message5" 4 "Message4" 3 "Message3" 2 "Message2" 1 "Message1" 0 "No_Message" ;
VAL_ 531 PrkBrkStatus 7 "GeneralFault_MaintenceMode" 6 "ECD_by_Brake_ECU_Active" 5 "EPB_Limphome_Active" 4 "Rear_Caliper_Open" 3 "RWU_By_EPB_Active" 2 "Rear_Caliper_Transition" 1 "Rear_Caliper_Closed" 0 "Not_Supported" ;
VAL_ 137 SteWhlOffstRq_D_Stat 3 "Faulty" 2 "NoDataExists" 1 "Allow_External_Angle_Req" 0 "Deny_External_Angle_Req" ;
VAL_ 137 SteWhlOffst_An_TotActl 32767 "Faulty" 32766 "NoDataExists" ;
VAL_ 137 SteWhlBrkOffst_An_Actl 32767 "Faulty" 32766 "NoDataExists" ;
VAL_ 136 SteWhlBrkOffst_An_Rq 32767 "Faulty" 32766 "NoDataExists" ;
VAL_ 604 WhlDirAvgDrv_D_Actl 3 "Faulty" 2 "NoDataExists" 1 "Backward" 0 "Forward" ;
VAL_ 604 PrplTqMnRgen_B_Actl 1 "Yes" 0 "No" ;
VAL_ 604 WhlDirAvgDrv_D_Actl_UB 1 "Fresh_data" 0 "Unchanged_data" ;
VAL_ 604 PrplTqMnRgen_B_Actl_UB 1 "Fresh_data" 0 "Unchanged_data" ;
VAL_ 125 VehRolComp_W_Actl 4094 "NoDataExists" 4095 "Fault" ;
VAL_ 125 VehVertComp_A_Actl 1022 "NoDataExists" 1023 "Fault" ;
VAL_ 125 BrkTot_Tq_RqArb 8191 "Fault" 8190 "Unknown" ;
VAL_ 125 BrkTot_Tq_Actl 8191 "Fault" 8190 "Unknown" ;
VAL_ 125 HsaStat_D_Actl 7 "Faulty" 6 "FaultyWithDriverIndication" 5 "SlowRelease" 4 "FastRelease" 3 "ActiveBrakePedalReleased" 2 "ActiveBrakePedalPressed" 1 "FindingGradient" 0 "Inactive" ;
VAL_ 119 VehTrvlDir_D_Stat 7 "Faulty" 6 "NoDataExists" 5 "NotUsed2" 4 "NotUsed1" 3 "Reverse" 2 "LikelyReverse" 1 "Forward" 0 "LikelyForward" ;
VAL_ 119 VehOverGnd_V_Est 65535 "Invalid" 65534 "Unknown" ;
VAL_ 119 VehLongComp_A_Actl 1023 "Fault" 1022 "NoDataExists" ;
VAL_ 119 VehLatComp_A_Actl 1023 "Fault" 1022 "NoDataExists" ;
VAL_ 119 VehYawComp_W_Actl 4095 "Fault" 4094 "NoDataExists" ;
VAL_ 118 ApaBrkErr_D_Stat 3 "Faulty" 2 "NoDataExists" 1 "Yes" 0 "No" ;
VAL_ 118 BrkCtrFnd_B_Stat 1 "Yes" 0 "No" ;
VAL_ 118 BrkTerrMdeChng_D_Rdy 7 "Fault" 6 "Undefined_2" 5 "Undefined_1" 4 "ModeUnavailDrInputRqd" 3 "SpOpModes_NotSupported" 2 "ModeUnavailDynamicCond" 1 "Module_In_Initialization" 0 "Mode_Change_Available" ;
VAL_ 118 BrkTerrMde_D_Actl 7 "Fail_Safe_Default" 6 "Dynamic_Mode" 5 "Rock_Crawl_Mode" 4 "Mud_Ruts_Mode" 3 "Sand_Mode" 2 "Undefined" 1 "Low_Mu_Mode" 0 "Special_Operating_Mode_Off" ;
VAL_ 118 DrvSte_D_Stat 15 "NotUsed10" 14 "NotUsed9" 13 "NotUsed8" 12 "NotUsed7" 11 "NotUsed6" 10 "NotUsed5" 9 "NotUsed4" 8 "NotUsed3" 7 "NotUsed2" 6 "NotUsed1" 5 "Request_Active" 4 "Ignition_Off" 3 "DSR_in_Normal_Idle_Mode" 2 "EPAS_Comm_Disturbed" 1 "DSR_Request_Not_Applicable" 0 "DSR_Deactivated" ;
VAL_ 118 DrvSte_Tq_Rq 255 "Invalid" 254 "Unknown" ;
VAL_ 118 EmgcyBrkLamp_D_Rq 3 "NotUsed" 2 "Active_at_standstill" 1 "Active_at_speed" 0 "Inactive" ;
VAL_ 118 StopLamp_B_RqBrk 1 "Active" 0 "Inactive" ;
VAL_ 118 SteWhlCompAnEst_D_Qf 3 "OK" 2 "Not_Within_Specifications" 1 "No_Data_Exists" 0 "Faulty" ;
VAL_ 75 VedsPasKneeBag_D_Ltchd 7 "Fault" 6 "NotSupported" 5 "Unused_3" 4 "Unused_2" 3 "Unused_1" 2 "NotDeployed" 1 "Deployed" 0 "NoEvent" ;
VAL_ 75 VedsRw3pRib_D_Ltchd 7 "Fault" 6 "NotSupported" 5 "Unused_3" 4 "Unused_2" 3 "Unused_1" 2 "NotDeployed" 1 "Deployed" 0 "NoEvent" ;
VAL_ 75 VedsRw3dRib_D_Ltchd 7 "Fault" 6 "NotSupported" 5 "Unused_3" 4 "Unused_2" 3 "Unused_1" 2 "NotDeployed" 1 "Deployed" 0 "NoEvent" ;
VAL_ 75 VedsRw1mBckl_D_Ltchd 5 "Unused_3" 4 "Unused_2" 3 "Unused_1" 2 "NotBelted" 1 "Belted" 0 "NoEvent" 7 "Fault" 6 "NotSupported" ;
VAL_ 75 VedsRw1mBelt_D_Ltchd 7 "Fault" 6 "NotSupported" 5 "Unused_3" 4 "Unused_2" 3 "Unused_1" 2 "NotDeployed" 1 "Deployed" 0 "NoEvent" ;
VAL_ 75 VedsRw2pRib_D_Ltchd 7 "Fault" 6 "NotSupported" 5 "Unused_3" 4 "Unused_2" 3 "Unused_1" 2 "NotDeployed" 1 "Deployed" 0 "NoEvent" ;
VAL_ 75 VedsRw2dRib_D_Ltchd 7 "Fault" 6 "NotSupported" 5 "Unused_3" 4 "Unused_2" 3 "Unused_1" 2 "NotDeployed" 1 "Deployed" 0 "NoEvent" ;
VAL_ 75 VedsRw3pBckl_D_Ltchd 5 "Unused_3" 4 "Unused_2" 3 "Unused_1" 2 "NotBelted" 1 "Belted" 0 "NoEvent" 7 "Fault" 6 "NotSupported" ;
VAL_ 75 VedsRw3mBckl_D_Ltchd 5 "Unused_3" 4 "Unused_2" 3 "Unused_1" 2 "NotBelted" 1 "Belted" 0 "NoEvent" 7 "Fault" 6 "NotSupported" ;
VAL_ 75 VedsRw3dBckl_D_Ltchd 5 "Unused_3" 4 "Unused_2" 3 "Unused_1" 2 "NotBelted" 1 "Belted" 0 "NoEvent" 7 "Fault" 6 "NotSupported" ;
VAL_ 75 VedsRw2pBckl_D_Ltchd 5 "Unused_3" 4 "Unused_2" 3 "Unused_1" 2 "NotBelted" 1 "Belted" 0 "NoEvent" 7 "Fault" 6 "NotSupported" ;
VAL_ 75 VedsRw2mBckl_D_Ltchd 5 "Unused_3" 4 "Unused_2" 3 "Unused_1" 2 "NotBelted" 1 "Belted" 0 "NoEvent" 7 "Fault" 6 "NotSupported" ;
VAL_ 75 VedsRw2dBckl_D_Ltchd 5 "Unused_3" 4 "Unused_2" 3 "Unused_1" 2 "NotBelted" 1 "Belted" 0 "NoEvent" 7 "Fault" 6 "NotSupported" ;
VAL_ 75 VedsRw1PasChld_D_Ltchd 7 "Fault" 6 "NotSupported" 5 "Unused_3" 4 "Unused_2" 3 "Unused_1" 2 "ChildNotDetected" 1 "ChildDetected" 0 "NoEvent" ;
VAL_ 75 VedsRw1PasBckl_D_Ltchd 5 "Unused_3" 4 "Unused_2" 3 "Unused_1" 2 "NotBelted" 1 "Belted" 0 "NoEvent" 7 "Fault" 6 "NotSupported" ;
VAL_ 75 VedsRw1DrvBckl_D_Ltchd 5 "Unused_3" 4 "Unused_2" 3 "Unused_1" 2 "NotBelted" 1 "Belted" 0 "NoEvent" 7 "Fault" 6 "NotSupported" ;
VAL_ 74 VedsPasSideBag_D_Ltchd 7 "Fault" 6 "NotSupported" 5 "Unused_3" 4 "Unused_2" 3 "Unused_1" 2 "NotDeployed" 1 "Deployed" 0 "NoEvent" ;
VAL_ 74 VedsPasCrtnBag_D_Ltchd 7 "Fault" 6 "NotSupported" 5 "Unused_3" 4 "Unused_2" 3 "Unused_1" 2 "NotDeployed" 1 "Deployed" 0 "NoEvent" ;
VAL_ 74 VedsPasBelt_D_Ltchd 7 "Fault" 6 "NotSupported" 5 "Unused_3" 4 "Unused_2" 3 "Unused_1" 2 "NotDeployed" 1 "Deployed" 0 "NoEvent" ;
VAL_ 74 VedsPasBag_D_Ltchd 7 "Fault" 6 "NotSupported" 5 "Unused_3" 4 "Unused_2" 3 "Unused_1" 2 "NotDeployed" 1 "Deployed" 0 "NoEvent" ;
VAL_ 74 VedsMultiEvnt_D_Ltchd 7 "Fault" 6 "NotSupported" 5 "Unused_3" 4 "Unused_2" 3 "Unused_1" 2 "Yes" 1 "No" 0 "NoEvent" ;
VAL_ 74 VedsMaxDeltaV_D_Ltchd 0 "NoEvent" 255 "Fault" 254 "NotSupported" ;
VAL_ 74 VedsDrvKneeBag_D_Ltchd 7 "Fault" 6 "NotSupported" 5 "Unused_3" 4 "Unused_2" 3 "Unused_1" 2 "NotDeployed" 1 "Deployed" 0 "NoEvent" ;
VAL_ 74 VedsEvntType_D_Ltchd 7 "Fault" 6 "NotSupported" 5 "Unused" 4 "Rolllover" 3 "Rear" 2 "Side" 1 "Frontal" 0 "NoEvent" ;
VAL_ 74 VedsEvntRoll_D_Ltchd 7 "Fault" 6 "NotSupported" 5 "Unused_3" 4 "Unused_2" 3 "Unused_1" 2 "Yes" 1 "No" 0 "NoEvent" ;
VAL_ 74 VedsDrvSideBag_D_Ltchd 7 "Fault" 6 "NotSupported" 5 "Unused_3" 4 "Unused_2" 3 "Unused_1" 2 "NotDeployed" 1 "Deployed" 0 "NoEvent" ;
VAL_ 74 VedsDrvCrtnBag_D_Ltchd 7 "Fault" 6 "NotSupported" 5 "Unused_3" 4 "Unused_2" 3 "Unused_1" 2 "NotDeployed" 1 "Deployed" 0 "NoEvent" ;
VAL_ 74 VedsDrvBelt_D_Ltchd 7 "Fault" 6 "NotSupported" 5 "Unused_3" 4 "Unused_2" 3 "Unused_1" 2 "NotDeployed" 1 "Deployed" 0 "NoEvent" ;
VAL_ 74 VedsDrvBag_D_Ltchd 7 "Fault" 6 "NotSupported" 5 "Unused_3" 4 "Unused_2" 3 "Unused_1" 2 "NotDeployed" 1 "Deployed" 0 "NoEvent" ;
VAL_ 74 eCallNotification 3 "Not_Used" 2 "Active" 1 "Normal" 0 "Not_Supported" ;
VAL_ 947 ValetMode_D_Mem 1 "On" 0 "Off" ;
VAL_ 947 DrStatDrvErrCnt_B_Stat 1 "Yes" 0 "No" ;
VAL_ 947 Backlit_LED_Status 15 "Unused3" 14 "Unused2" 13 "Unused1" 12 "Night_12" 11 "Night_11" 10 "Night_10" 9 "Night_9" 8 "Night_8" 7 "Night_7" 6 "Night_6" 5 "Night_5" 4 "Night_4" 3 "Night_3" 2 "Night_2" 1 "Night_1" 0 "Off" ;
VAL_ 947 TurnLghtRight_D_Rq 3 "Seq" 2 "On" 1 "Off" 0 "Null" ;
VAL_ 947 TurnLghtRightOn_B_Stat 1 "On" 0 "Off" ;
VAL_ 947 TurnLghtLeftOn_B_Stat 1 "On" 0 "Off" ;
VAL_ 947 FogLghtRearOn_B_Stat 1 "On" 0 "Off" ;
VAL_ 947 FogLghtFrontOn_B_Stat 1 "On" 0 "Off" ;
VAL_ 947 TurnLghtLeft_D_Rq 3 "Seq" 2 "On" 1 "Off" 0 "Null" ;
VAL_ 947 IgnKeyType_D_Actl 15 "Invalid" 14 "Unknown" 3 "Key_Not_Prgrm_Read_Failure" 2 "Key_In_Ign_My_Key" 1 "Key_In_Ign_Standard_Key" 0 "Key_Read_In_Progress" ;
VAL_ 947 Parklamp_Status 3 "Invalid" 2 "Unknown" 1 "On" 0 "Off" ;
VAL_ 947 Litval 255 "Invalid" 254 "Unknown" 5 "Day" 4 "Twilight_4" 3 "Twilight_3" 2 "Twilight_2" 1 "Twilight_1" 0 "Night" ;
VAL_ 947 Key_In_Ignition_Stat 1 "In" 0 "Out" ;
VAL_ 947 Ignition_Status 0 "Unknown" 1 "Off" 15 "Invalid" 8 "Start" 4 "Run" 2 "Accessory" ;
VAL_ 947 Dimming_Lvl 255 "Invalid" 254 "Unknown" 18 "Day_6" 17 "Day_5" 16 "Day_4" 15 "Day_3" 14 "Day_2" 13 "Day_1" 12 "Night_12" 11 "Night_11" 10 "Night_10" 9 "Night_9" 8 "Night_8" 7 "Night_7" 6 "Night_6" 5 "Night_5" 4 "Night_4" 3 "Night_3" 2 "Night_2" 1 "Night_1" 0 "Off" ;
VAL_ 947 Day_Night_Status 3 "NotUsed" 2 "Night" 1 "Day" 0 "Null" ;
VAL_ 947 Remote_Start_Status 3 "Invalid" 2 "Unknown" 1 "Remote" 0 "Null" ;
VAL_ 947 DrStatTgate_B_Actl 1 "Ajar" 0 "Closed" ;
VAL_ 947 DrStatRr_B_Actl 1 "Ajar" 0 "Closed" ;
VAL_ 947 DrStatRl_B_Actl 1 "Ajar" 0 "Closed" ;
VAL_ 947 DrStatPsngr_B_Actl 1 "Ajar" 0 "Closed" ;
VAL_ 947 DrStatInnrTgate_B_Actl 1 "Ajar" 0 "Closed" ;
VAL_ 947 DrStatHood_B_Actl 1 "Ajar" 0 "Closed" ;
VAL_ 947 DrStatDrv_B_Actl 1 "Ajar" 0 "Closed" ;
VAL_ 947 PrkBrkActv_B_Actl 1 "Active" 0 "Inactive" ;
VAL_ 947 LifeCycMde_D_Actl 3 "Transport" 2 "NotUsed" 1 "Factory" 0 "Normal" ;
VAL_ 947 CrashEvnt_D_Stat 3 "Invalid" 2 "Fuel_Cutoff_Event" 1 "Deploy_Event" 0 "No_Event" ;
VAL_ 947 FuelPmpInhbt_B_Stat 1 "Inhibit" 0 "No_Inibit" ;
VAL_ 947 BodySrvcRqd_B_Rq 1 "Yes" 0 "No" ;
VAL_ 947 Delay_Accy 1 "On" 0 "Off" ;
VAL_ 131 HeadLghtHiCtrl_D_RqAhb 7 "NotUsed2" 6 "NotUsed1" 5 "Auto_HiBeam" 4 "Auto_LoBeam" 3 "Flash" 2 "Man_HiBeam" 1 "Man_LoBeam" 0 "Null" ;
VAL_ 131 AhbStat_B_Dsply 1 "On" 0 "Off" ;
VAL_ 131 WiprFrontSwtch_D_Stat 15 "NotUsed6" 14 "NotUsed5" 13 "NotUsed4" 12 "NotUsed3" 11 "NotUsed2" 10 "NotUsed1" 9 "PositionNotDetermined" 8 "High" 7 "Low" 6 "Position6" 5 "Position5" 4 "Position4" 3 "Position3" 2 "Position2" 1 "Position1" 0 "Off" ;
VAL_ 131 HeadLghtHiOn_B_StatAhb 1 "On" 0 "Off" ;
VAL_ 131 HeadLghtHiFlash_D_Actl 3 "NotUsed" 2 "High" 1 "Flash_to_Pass" 0 "Null" ;
VAL_ 131 TjaButtnOnOffPress 1 "Pressed" 0 "Not_Pressed" ;
VAL_ 131 AccButtnGapTogglePress 1 "Pressed" 0 "Not_Pressed" ;
VAL_ 131 HeadLghtHiFlash_D_Stat 3 "NotUsed" 2 "High" 1 "Flash_to_Pass" 0 "Null" ;
VAL_ 131 WiprFront_D_Stat 15 "NO_DATA_EXISTS" 14 "STALLED" 13 "RESERVED" 12 "AUTO_ADJUST" 11 "COURTESYWIPE" 10 "AUTO_HIGH" 9 "AUTO_LOW" 8 "WASH" 7 "MIST_FLICK" 6 "MAN_HIGH" 5 "MAN_LOW" 4 "MAN_INT_ON" 3 "MAN_INT_OFF" 2 "OFF_MOVING" 1 "AUTO_OFF" 0 "OFF" ;
VAL_ 131 TurnLghtSwtch_D_Stat 3 "Unused_Treat_As_Off" 2 "Right" 1 "Left" 0 "Off" ;
VAL_ 131 LghtAmb_D_Sns 7 "No_Data_Exists" 6 "Unused2" 5 "Unused1" 4 "Tunnel_Off" 3 "Tunnel_On" 2 "Twilight" 1 "Light" 0 "Dark" ;
VAL_ 131 AccButtnGapIncPress 1 "Button_Pressed" 0 "Button_Not_Pressed" ;
VAL_ 131 AccButtnGapDecPress 1 "Button_Pressed" 0 "Button_Not_Pressed" ;
VAL_ 131 AslButtnOnOffPress 1 "Button_Pressed" 0 "Button_Not_Pressed" ;
VAL_ 131 AslButtnOnOffCnclPress 1 "Button_Pressed" 0 "Button_Not_Pressed" ;
VAL_ 131 CcButtnOnPress 1 "Button_Pressed" 0 "Button_Not_Pressed" ;
VAL_ 131 CcButtnOnOffPress 1 "Button_Pressed" 0 "Button_Not_Pressed" ;
VAL_ 131 CcButtnOnOffCnclPress 1 "Button_Pressed" 0 "Button_Not_Pressed" ;
VAL_ 131 CcButtnOffPress 1 "Button_Pressed" 0 "Button_Not_Pressed" ;
VAL_ 131 CcAsllButtnResPress 1 "Button_Pressed" 0 "Button_Not_Pressed" ;
VAL_ 131 CcAslButtnSetPress 1 "Button_Pressed" 0 "Button_Not_Pressed" ;
VAL_ 131 CcAslButtnSetIncPress 1 "Button_Pressed" 0 "Button_Not_Pressed" ;
VAL_ 131 CcAslButtnSetDecPress 1 "Button_Pressed" 0 "Button_Not_Pressed" ;
VAL_ 131 CcAslButtnResIncPress 1 "Button_Pressed" 0 "Button_Not_Pressed" ;
VAL_ 131 CcAslButtnResDecPress 1 "Button_Pressed" 0 "Button_Not_Pressed" ;
VAL_ 131 CcAslButtnOnPress 1 "Button_Pressed" 0 "Button_Not_Pressed" ;
VAL_ 131 CcAslButtnOnOffCncl 1 "Button_Pressed" 0 "Button_Not_Pressed" ;
VAL_ 131 CcAslButtnOffCnclPress 1 "Button_Pressed" 0 "Button_Not_Pressed" ;
VAL_ 131 CcAslButtnIndxIncPress 1 "Button_Pressed" 0 "Button_Not_Pressed" ;
VAL_ 131 CcAslButtnIndxDecPress 1 "Button_Pressed" 0 "Button_Not_Pressed" ;
VAL_ 131 CcAslButtnDeny_B_Actl 1 "Yes" 0 "No" ;
VAL_ 131 CcAslButtnCnclResPress 1 "Button_Pressed" 0 "Button_Not_Pressed" ;
VAL_ 131 CcAslButtnCnclPress 1 "Button_Pressed" 0 "Button_Not_Pressed" ;
VAL_ 131 LaSwtchPos_D_Stat 3 "Fault" 2 "Unused" 1 "Pressed" 0 "Open" ;
VAL_ 992 MsgCntrPersIndex_D_Rq 7 "Unused_3" 6 "Unused_2" 5 "Unused_1" 4 "Vehicle" 3 "PERS_4" 2 "PERS_3" 1 "PERS_2" 0 "PERS_1" ;
VAL_ 992 MsgCntrDsplyOp_D_Rq 7 "Unused_2" 6 "Unused_1" 5 "Copy" 4 "Restore" 3 "Upload" 2 "Set" 1 "Query" 0 "Null" ;
VAL_ 970 LkaDrvOvrrd_D_Rq 3 "Level_3" 2 "Level_2" 1 "Level_1" 0 "Level_0" ;
VAL_ 970 LkaActvStats_D2_Req 7 "NotUsed" 6 "LkaIncrIntervRight" 5 "LkaSupprRight" 4 "LkaStandIntervRight" 3 "LkaSupprLeft" 2 "LkaStandIntervLeft" 1 "LkaIncrIntervLeft" 0 "LkaNoInterv" ;
VAL_ 970 LaRefAng_No_Req 4095 "Fault" ;
VAL_ 970 LaRampType_B_Req 1 "Quick" 0 "Smooth" ;
VAL_ 970 LaCurvature_No_Calc 4095 "Fault" ;
VAL_ 970 LdwActvStats_D_Req 7 "LDW_Suppress_Right_Left" 6 "Not_Used2" 5 "LDW_Suppress_Right" 4 "LDW_Warning_Right" 3 "LDW_Suppress_Left" 2 "LDW_Warning_Left" 1 "LDW_DemoVibration" 0 "LDW_Idle" ;
VAL_ 970 LdwActvIntns_D_Req 3 "High" 2 "Medium" 1 "Low" 0 "None" ;
VAL_ 129 SelDrvMdeSwtch4_D_Stat4 3 "Faulty" 2 "Pressed" 1 "NotPressed" 0 "Null" ;
VAL_ 129 EngExhMdeQuiet_B_RqDrv2 1 "Pressed" 0 "Not_Pressed" ;
VAL_ 129 PoliceAux4Swtch_B_Stat 1 "Switch_Active" 0 "Switch_Not_Active" ;
VAL_ 129 PoliceAux3Swtch_B_Stat 1 "Switch_Active" 0 "Switch_Not_Active" ;
VAL_ 129 PoliceAux2Swtch_B_Stat 1 "Switch_Active" 0 "Switch_Not_Active" ;
VAL_ 129 PoliceAux1Swtch_B_Stat 1 "Switch_Active" 0 "Switch_Not_Active" ;
VAL_ 129 SteWhlSwtchHome_B_Stat 1 "Pressed" 0 "Not_Pressed" ;
VAL_ 129 SteWhlSwtchInfo_B_Stat 1 "Pressed" 0 "Not_Pressed" ;
VAL_ 129 SelDrvMdeSwtch_D_Stat4 3 "Faulty" 2 "SwitchState2" 1 "SwitchState1" 0 "NotPressed" ;
VAL_ 129 SelDrvMdeSwtch3_D_Stat4 3 "Faulty" 2 "Pressed" 1 "NotPressed" 0 "Null" ;
VAL_ 129 SelDrvMdeSwtch2_D_Stat4 3 "Faulty" 2 "Pressed" 1 "NotPressed" 0 "Null" ;
VAL_ 129 SelDrvMdeSwtch1_D_Stat4 3 "Faulty" 2 "Pressed" 1 "NotPressed" 0 "Null" ;
VAL_ 129 SteWhlSwtchView_B_Stat 1 "Pressed" 0 "Not_Pressed" ;
VAL_ 129 SteWhlSwtchSet_B_Stat 1 "Pressed" 0 "Not_Pressed" ;
VAL_ 129 SteWhlSwtchPhon_B_Stat 1 "Pressed" 0 "Not_Pressed" ;
VAL_ 129 SteWhlSwtchNav_B_Stat 1 "Pressed" 0 "Not_Pressed" ;
VAL_ 129 SteWhlSwtchMed_B_Stat 1 "Pressed" 0 "Not_Pressed" ;
VAL_ 129 SteWhlSwtchIod_B_Stat 1 "Pressed" 0 "Not_Pressed" ;
VAL_ 129 SteWhlSwtchHud_B_Stat 1 "Pressed" 0 "Not_Pressed" ;
VAL_ 129 SteWhlSwtchBack_B_Stat 1 "Pressed" 0 "Not_Pressed" ;
VAL_ 129 SteWhlSwtchMenu_B_Stat 1 "Pressed" 0 "Not_Pressed" ;
VAL_ 129 SteEffortInc_B_RqDrv 1 "Pressed" 0 "Not_Pressed" ;
VAL_ 129 SelDrvMdeInc_B_RqDrv 1 "Pressed" 0 "Not_Pressed" ;
VAL_ 129 SelDrvMdeDec_B_RqDrv 1 "Pressed" 0 "Not_Pressed" ;
VAL_ 129 SuspDampInc_B_RqDrv 1 "Pressed" 0 "Not_Pressed" ;
VAL_ 129 SteWhlSwtchUp_B_Stat 1 "Pressed" 0 "Not_Pressed" ;
VAL_ 129 SteWhlSwtchRght_B_Stat 1 "Pressed" 0 "Not_Pressed" ;
VAL_ 129 SteWhlSwtchOk_B_Stat 1 "Pressed" 0 "Not_Pressed" ;
VAL_ 129 SteWhlSwtchLeft_B_Stat 1 "Pressed" 0 "Not_Pressed" ;
VAL_ 129 SteWhlSwtchDown_B_Stat 1 "Pressed" 0 "Not_Pressed" ;
VAL_ 1109 eCallConfirmation 7 "Unused_2" 6 "CallComplete_DTMF_Timeout" 5 "eCall_Configured_Off" 4 "Call_Unsuccessful" 3 "Call_Cancelled" 2 "Call_Completed" 1 "Call_In_Progress" 0 "Normal" ;
VAL_ 1046 PrkBrkDynmc_D_Allw 3 "NotUsed" 2 "EPB_ECD_NotPossible" 1 "EPB_ECD_Possible" 0 "Used_at_Start_Up" ;
VAL_ 1046 BrkPrkBrkDynmc_B_Actl 1 "Active" 0 "Inactive" ;
VAL_ 1046 HsaMde_D_Mem 3 "Undefined" 2 "Manual" 1 "Automatic" 0 "Off" ;
VAL_ 1046 BrkBstrVac_B_Rq 1 "Yes" 0 "No" ;
VAL_ 1046 HdcMde_D_Actl 7 "Fault" 6 "Temporarily_Unavailable" 5 "NotEnabled_WrongGearSel" 4 "NotEnabled_SpdLimitExceed" 3 "Active_Braking" 2 "Not_Active_Braking" 1 "Off" 0 "Undefined" ;
VAL_ 1046 RearDiffLck_Tq2_RqMx 4095 "Faulty" ;
VAL_ 1046 TRLR_SWAY_EVNT_IN_PROG 1 "Yes" 0 "No" ;
VAL_ 1046 TRLR_SWAY_CONFIG_STAT 1 "On" 0 "Off" ;
VAL_ 1046 TCMode 1 "Active" 0 "Inactive" ;
VAL_ 1046 DrvSlipCtlLamp_D_Rq 3 "Fast_Flash" 2 "Slow_Flash" 1 "On" 0 "Off" ;
VAL_ 1046 Abs_B_Falt 1 "Yes" 0 "No" ;
VAL_ 1046 DrvSlipCtlMde_D_Ind 3 "App_Specific_Off_Mode_3" 2 "App_Specific_Off_Mode_2" 1 "App_Specific_Off_Mode_1" 0 "Default_Mode" ;
VAL_ 1046 DrvAntiLckLamp_D_Rq 3 "Fast_Flash" 2 "Slow_Flash" 1 "On" 0 "Off" ;
VAL_ 1046 StabCtlBrk_B_Avail 1 "Yes" 0 "No" ;
VAL_ 1046 DrvHdcWarnInfo_D_Rq 3 "Undefined" 2 "Lamp_On_Continuously" 1 "Lamp_Flashing" 0 "Lamp_Off_Continuously" ;
VAL_ 1046 DrvHdcMsg_D_Rq 7 "Undefined" 6 "Speed_too_High" 5 "Temporarily_Unavailable" 4 "System_Fault" 3 "Select_Gear" 2 "Off" 1 "On" 0 "No_Message" ;
VAL_ 1046 DrvHdcLampInfo_D_Rq 3 "Fast_Flash" 2 "Slow_Flash" 1 "On" 0 "Off" ;
VAL_ 1046 RearDiffElckrOpen_B_Rq 1 "Yes" 0 "No" ;
VAL_ 1046 BpedMove_D_Actl 3 "Unknown" 2 "DriverApplyingBrakePedal" 1 "NoAutonomousBrkPdlMovement" 0 "AutonomousBrkPedalMove" ;
VAL_ 1046 ChimeBrk_B_Rq 1 "Yes" 0 "No" ;
VAL_ 1046 BrkLamp_B_Rq 1 "Yes" 0 "No" ;
VAL_ 1046 HILL_DESC_MC 7 "Fault_Detected" 6 "Cooling_Down" 5 "Abort_Apply_Brakes" 4 "Active" 3 "Disabled" 2 "Enabled" 1 "Off_Road" 0 "Normal" ;
VAL_ 534 WhlDirRr_D_Actl 3 "Faulty" 2 "NoDataExists" 1 "Backward" 0 "Forward" ;
VAL_ 534 WhlDirRl_D_Actl 3 "Faulty" 2 "NoDataExists" 1 "Backward" 0 "Forward" ;
VAL_ 534 WhlDirFr_D_Actl 3 "Faulty" 2 "NoDataExists" 1 "Backward" 0 "Forward" ;
VAL_ 534 WhlDirFl_D_Actl 3 "Faulty" 2 "NoDataExists" 1 "Backward" 0 "Forward" ;
VAL_ 1093 TrlBrkInitOut_D_Stat 3 "Heavy" 2 "Medium" 1 "Light" 0 "Null" ;
VAL_ 1093 TrlrBrkMde_D_Actl 1 "Electric_Over_Hydraulic" 0 "Electric" ;
VAL_ 1093 TrlrBrkDsply_B_Rq 1 "Yes" 0 "No" ;
VAL_ 1093 TrlrBrkDcnnt_B_Actl 1 "Yes" 0 "No" ;
VAL_ 1093 TrlrBrkActCnnct_B_Actl 1 "Yes" 0 "No" ;
VAL_ 1093 StopLamp_B_RqTrlrBrk 1 "Yes" 0 "No" ;
VAL_ 1093 TrlrBrkCtl_B_Falt 1 "Yes" 0 "No" ;
VAL_ 1093 TrlrBrkActCirct_B_Falt 1 "Yes" 0 "No" ;
VAL_ 994 PersCtaSplitView_D_Rq 3 "EnabledFull" 2 "Enabled_180SwitchOnly" 1 "Disabled" 0 "Null" ;
VAL_ 994 PersStore_D_Rq 7 "Unused_2" 6 "Unused_1" 5 "Vehicle" 4 "PERS_4" 3 "PERS_3" 2 "PERS_2" 1 "PERS_1" 0 "Null" ;
VAL_ 994 Pers4OptIn_B_Stats 1 "OPTED_IN" 0 "NOT_OPTED_IN" ;
VAL_ 994 CtrStkPersIndex_D_Actl 7 "Unused_3" 6 "Unused_2" 5 "Unused_1" 4 "Vehicle" 3 "PERS_4" 2 "PERS_3" 1 "PERS_2" 0 "PERS_1" ;
VAL_ 994 CtrStkDsplyOp_D_Rq 7 "Unused_2" 6 "Unused_1" 5 "Copy" 4 "Restore" 3 "Upload" 2 "Set" 1 "Query" 0 "Null" ;
VAL_ 994 Pers3OptIn_B_Stats 1 "OPTED_IN" 0 "NOT_OPTED_IN" ;
VAL_ 994 Pers2OptIn_B_Stats 1 "OPTED_IN" 0 "NOT_OPTED_IN" ;
VAL_ 994 Pers1OptIn_B_Stats 1 "OPTED_IN" 0 "NOT_OPTED_IN" ;
VAL_ 1108 RCMSerialNoByte8 255 "Invalid" 254 "Unknown" ;
VAL_ 1108 RCMSerialNoByte7 255 "Invalid" 254 "Unknown" ;
VAL_ 1108 RCMSerialNoByte6 255 "Invalid" 254 "Unknown" ;
VAL_ 1108 RCMSerialNoByte5 255 "Invalid" 254 "Unknown" ;
VAL_ 1108 RCMSerialNoByte4 255 "Invalid" 254 "Unknown" ;
VAL_ 1108 RCMSerialNoByte3 255 "Invalid" 254 "Unknown" ;
VAL_ 1108 RCMSerialNoByte2 255 "Invalid" 254 "Unknown" ;
VAL_ 1108 RCMSerialNoByte1 255 "Invalid" 254 "Unknown" ;
VAL_ 1107 OCSSerialNoByte8 255 "Invalid" 254 "Unknown" ;
VAL_ 1107 OCSSerialNoByte7 255 "Invalid" 254 "Unknown" ;
VAL_ 1107 OCSSerialNoByte6 255 "Invalid" 254 "Unknown" ;
VAL_ 1107 OCSSerialNoByte5 255 "Invalid" 254 "Unknown" ;
VAL_ 1107 OCSSerialNoByte4 255 "Invalid" 254 "Unknown" ;
VAL_ 1107 OCSSerialNoByte3 255 "Invalid" 254 "Unknown" ;
VAL_ 1107 OCSSerialNoByte2 255 "Invalid" 254 "Unknown" ;
VAL_ 1107 OCSSerialNoByte1 255 "Invalid" 254 "Unknown" ;
VAL_ 145 VehYawWActl_D_Qf 3 "OK" 2 "Not_Within_Specifications" 1 "No_Data_Exists" 0 "Faulty" ;
VAL_ 145 VehRolWActl_D_Qf 3 "OK" 2 "Not_Within_Specifications" 1 "No_Data_Exists" 0 "Faulty" ;
VAL_ 145 VehYaw_W_Actl 65535 "Faulty" 65534 "NoDataExists" ;
VAL_ 145 VehRol_W_Actl 65535 "Faulty" 65534 "NoDataExists" ;
VAL_ 1045 VehStab_D_Stat 15 "Faulty" 14 "No_Data_Exists" 13 "NotUsed6" 12 "NotUsed5" 11 "NotUsed4" 10 "NotUsed3" 9 "NotUsed2" 8 "Combined_OS_and_US" 7 "High_SSRA_no_OS" 6 "Straight" 5 "Post_Oversteer" 4 "Post_Transition" 3 "Countersteer" 2 "Understeer" 1 "Oversteer" 0 "Linear" ;
VAL_ 1045 BrkFluidLvl_D_Stat 3 "Invalid" 2 "Unknown" 1 "Low" 0 "OK" ;
VAL_ 1045 LsmcBrkDecel_D_Stat 7 "NotUsed_3" 6 "NotUsed_2" 5 "NotUsed_1" 4 "Denied" 3 "FaultDegraded" 2 "FaultExt" 1 "On" 0 "Off" ;
VAL_ 1045 VehYawNonLin_W_Rq 4095 "Fault" 4094 "Unknown" ;
VAL_ 1045 VehYawLin_W_Rq 4095 "Fault" 4094 "Unknown" ;
VAL_ 1045 VehVActlBrk_D_Qf 3 "OK" 2 "Not_Within_Specifications" 1 "No_Data_Exists" 0 "Faulty" ;
VAL_ 146 VehVert2_A_Actl 8191 "Faulty" 8190 "NoDataExists" ;
VAL_ 146 VehLong2_A_Actl 8191 "Faulty" 8190 "NoDataExists" ;
VAL_ 146 VehLat2_A_Actl 8191 "Faulty" 8190 "NoDataExists" ;
VAL_ 146 VehVertAActl_D_Qf 3 "OK" 2 "Not_Within_Specifications" 1 "No_Data_Exists" 0 "Faulty" ;
VAL_ 146 VehLongAActl_D_Qf 3 "OK" 2 "Not_Within_Specifications" 1 "No_Data_Exists" 0 "Faulty" ;
VAL_ 146 VehLatAActl_D_Qf 3 "OK" 2 "Not_Within_Specifications" 1 "No_Data_Exists" 0 "Faulty" ;
VAL_ 1152 TerrStat_D_RqDsply 15 "Reserved4" 14 "Reserved3" 13 "Reserved2" 12 "Crawl_Mode_4LOW_Reqd" 11 "Economy_Mode_Select" 10 "ModeChangeNotAvailable" 9 "Terrain_Sys_Not_Avail" 8 "Terrain_System_Fault" 7 "Mode_Change_InProgress" 6 "Dynamics_Mode_Select" 5 "Rock_Crawl_Mode_Select" 4 "Sand_Mode_Select" 3 "Mud_Ruts_Mode_Select" 2 "Low_Mu_Mode_Select" 1 "Special_Modes_Off" 0 "No_Message" ;
VAL_ 1152 TerrMde_D_RqDrv 7 "Fail_Safe_Default" 6 "Dynamic_Mode" 5 "Rock_Crawl_Mode" 4 "Mud_Ruts_Mode" 3 "Sand_Mode" 2 "Undefined" 1 "Low_Mu_Mode" 0 "Special_Operating_Mode_Off" ;
VAL_ 984 DsmcMsgTxt_D_Dsply 3 "Blockage" 2 "DriverNotSeen" 1 "Fault" 0 "NoMessage" ;
VAL_ 984 AhbFeat_D_Stat 3 "ADB" 2 "GFHB" 1 "AHBC" 0 "None" ;
VAL_ 984 AhbcStat_B_Dsply 1 "On" 0 "Off" ;
VAL_ 984 AhbHiBeam_D_Rq 3 "NotUsed" 2 "HighBeamRecommended" 1 "LowBeamRecommended" 0 "DeactivatedUnavailable" ;
VAL_ 984 DasWarn_D_Dsply 3 "Undefined" 2 "Warning_Level_2" 1 "Warning_Level_1" 0 "No_Warning" ;
VAL_ 984 DasStats_D_Dsply 3 "Available" 2 "Unavailable_Other" 1 "Feedback_due_to_Speed" 0 "Off" ;
VAL_ 984 DasAlrtLvl_D_Dsply 5 "Alertness_Level_5" 4 "Alertness_Level_4" 3 "Alertness_Level_3" 2 "Alertness_Level_2" 1 "Alertness_Level_1" 0 "Undefined" ;
VAL_ 984 CamraStats_D_Dsply 3 "FrtCam_TempUnavailOther" 2 "FrtCam_TempUnavailVisibile" 1 "Front_Camera_Service_Reqd" 0 "Front_Camera_OK" ;
VAL_ 984 CamraDefog_B_Req 1 "On" 0 "Off" ;
VAL_ 984 LaHandsOff_D_Dsply 3 "Suppressed" 2 "Level2" 1 "Level1" 0 "HandsOn" ;
VAL_ 984 LaDenyStats_B_Dsply 1 "Unavailable" 0 "Available" ;
VAL_ 984 LaActvStats_D_Dsply 31 "Unused7" 30 "LA_Off" 29 "Unused5" 28 "Unused4" 27 "Unused3" 26 "Unused2" 25 "Unused1" 24 "InerveneLeft_InterveneRght" 23 "WarnLeft_InterveneRight" 22 "SuppressLeft_InterveneRght" 21 "AvailLeft_InterveneRhtt" 20 "NoLeft_InterveneRight" 19 "InterveneLeft_WarnRight" 18 "WarnLeft_WarnRight" 17 "SuppressLeft_WarnRight" 16 "AvailableLeft_WarnRight" 15 "NoLeft_WarnRight" 14 "InterveneLeft_SuppressRght" 13 "WarnLeft_SuppressRight" 12 "SuppressLeft_SuppressRight" 11 "AvailLeft_SuppressRight" 10 "NoLeft_SuppressRight" 9 "InterveneLeft_AvailRight" 8 "WarnLeft_AvailRight" 7 "SuppressLeft_AvailRight" 6 "AvailableLeft_AvailRight" 5 "NoLeft_AvailableRight" 4 "InterveneLeft_NoRight" 3 "WarnLeft_NoRight" 2 "SuppressLeft_NoRight" 1 "AvailableLeft_NoRight" 0 "NoLeft_NoRight" ;
VAL_ 984 AhbcRampingV_D_Rq 3 "Slow" 2 "Medium" 1 "Fast" 0 "Immediately" ;
VAL_ 984 PersIndexIpma_D_Actl 7 "Unused_3" 6 "Unused_2" 5 "Unused_1" 4 "Vehicle" 3 "PERS_4" 2 "PERS_3" 1 "PERS_2" 0 "PERS_1" ;
VAL_ 998 PersIndexSccm_D_Actl 7 "Unused_3" 6 "Unused_2" 5 "Unused_1" 4 "Vehicle" 3 "PERS_4" 2 "PERS_3" 1 "PERS_2" 0 "PERS_1" ;
VAL_ 613 BeltWarnThres_D_Stat 7 "Faulty" 6 "No_Data_Exists" 5 "NotUsed3" 4 "NotUsed2" 3 "NotUsed1" 2 "Over_Threshold" 1 "Under_Threshold" 0 "NotSupported" ;
VAL_ 613 VehicleMYCalibrationId 255 "Invalid" ;
VAL_ 613 VehicleCalibrationId 255 "Invalid" ;
VAL_ 613 OCSSensrDataUpperLim 255 "Invalid" ;
VAL_ 613 OCSSensrDataLowerLim 255 "Invalid" ;
VAL_ 613 OCSLevel2Error 1 "Yes" 0 "No" ;
VAL_ 613 ObjectEntrapped 1 "Yes" 0 "No" ;
VAL_ 613 OCSLevel1Error 1 "Yes" 0 "No" ;
VAL_ 130 TrlrHitchLamp_D_Rqst 1 "On" 0 "Off" ;
VAL_ 130 VehVTrlrAid_B_Rq 1 "Request" 0 "NoRequest" ;
VAL_ 130 SteEffort_D_Stat 7 "NotUsed_3" 6 "NotUsed_2" 5 "NotUsed_1" 4 "SpecialMode_2" 3 "SpecialMode_1" 2 "Comfort" 1 "Sport" 0 "Normal" ;
VAL_ 130 DrvSteActv_B_Stat 1 "Active" 0 "Inactive" ;
VAL_ 130 DrvSte_Tq_Actl 255 "Invalid" 254 "Unknown" ;
VAL_ 130 SteMdule_D_Stat 7 "NotUsed" 6 "EPAS_Failure3" 5 "EPAS_Failure2" 4 "System_Failure" 3 "EPAS_Shutdown" 2 "Normal_Op_Full_Assist" 1 "Normal_Op_Limited_Assist" 0 "EPAS_Initialization" ;
VAL_ 130 SteMdule_U_Meas 255 "Invalid" ;
VAL_ 130 SteMdule_I_Est 4095 "Invalid" ;
VAL_ 130 EPAS_Failure 3 "SERVICE_POWER_STEERING_NOW" 2 "SERVICE_POWER_STEERING" 1 "POWER_STRG_ASSIST_FAULT" 0 "EPAS_OK_NO_MESSAGE" ;
VAL_ 130 SteeringColumnTorque 255 "Invalid" 254 "Unknown" ;
VAL_ 130 SAPPAngleControlStat6 1 "RequestedAngleNotReached" 0 "RequestedAngleCanBeReached" ;
VAL_ 130 SAPPAngleControlStat5 1 "StrgColTorqueExceed_EAROn" 0 "ExternalSigContentOKforEAC" ;
VAL_ 130 SAPPAngleControlStat4 1 "SpeedLimitExceededEAROn" 0 "ExternalSigContentOKforEAC" ;
VAL_ 130 SAPPAngleControlStat3 1 "EARactiveNoReverseEngage" 0 "ExternalSigContentOKforEAC" ;
VAL_ 130 SAPPAngleControlStat2 1 "Rel_ExtSteeringAngleReqx" 0 "NoRel_ExtSteeringAngleReqx" ;
VAL_ 130 SAPPAngleControlStat1 3 "Fault" 2 "Active" 1 "Open" 0 "Closed" ;
VAL_ 827 LghtAmbIntns_D2_Sns 3 "Faulty" 2 "High" 1 "Medium" 0 "Low" ;
VAL_ 827 SteClmnSwtchTlt_D_Stat 3 "Unused" 2 "Down" 1 "Up" 0 "Null" ;
VAL_ 827 SteClmnSwtchTel_D_Stat 3 "Unused" 2 "Rearward" 1 "Forward" 0 "Null" ;
VAL_ 827 LghtAmbIntns_D_Sns 3 "Faulty" 2 "High" 1 "Low" 0 "Null" ;
VAL_ 848 RILStat 3 "Fault" 2 "Plant_Mode" 1 "On" 0 "Off" ;
VAL_ 392 HudMde_D_Stat 7 "NotUsed3" 6 "NotUsed2" 5 "NotUsed1" 4 "Manual" 3 "Drag" 2 "RoadCourse" 1 "Tach" 0 "Off" ;
VAL_ 392 HudLedMde_D_Stat 3 "Not_Used" 2 "Flash" 1 "On" 0 "Off" ;
VAL_ 392 HudLed9On_B_Stat 1 "On" 0 "Off" ;
VAL_ 392 HudLed8On_B_Stat 1 "On" 0 "Off" ;
VAL_ 392 HudLed7On_B_Stat 1 "On" 0 "Off" ;
VAL_ 392 Hud_B_Falt 1 "Yes" 0 "No" ;
VAL_ 392 HudActv_B_Actl 1 "Yes" 0 "No" ;
VAL_ 392 Hud_B_Avail 1 "Yes" 0 "No" ;
VAL_ 392 HudLed6On_B_Stat 1 "On" 0 "Off" ;
VAL_ 392 HudLed5On_B_Stat 1 "On" 0 "Off" ;
VAL_ 392 HudLed4On_B_Stat 1 "On" 0 "Off" ;
VAL_ 392 HudLed3On_B_Stat 1 "On" 0 "Off" ;
VAL_ 392 HudLed2On_B_Stat 1 "On" 0 "Off" ;
VAL_ 392 HudLed1On_B_Stat 1 "On" 0 "Off" ;
VAL_ 392 HudLed18On_B_Stat 1 "On" 0 "Off" ;
VAL_ 392 HudLed17On_B_Stat 1 "On" 0 "Off" ;
VAL_ 392 HudLed16On_B_Stat 1 "On" 0 "Off" ;
VAL_ 392 HudLed15On_B_Stat 1 "On" 0 "Off" ;
VAL_ 392 HudLed14On_B_Stat 1 "On" 0 "Off" ;
VAL_ 392 HudLed13On_B_Stat 1 "On" 0 "Off" ;
VAL_ 392 HudLed12On_B_Stat 1 "On" 0 "Off" ;
VAL_ 392 HudLed11On_B_Stat 1 "On" 0 "Off" ;
VAL_ 392 HudLed10On_B_Stat 1 "On" 0 "Off" ;
